VERSION ""

NS_ :

BS_:

BU_: GW_ABFD ADCU3_ABFD

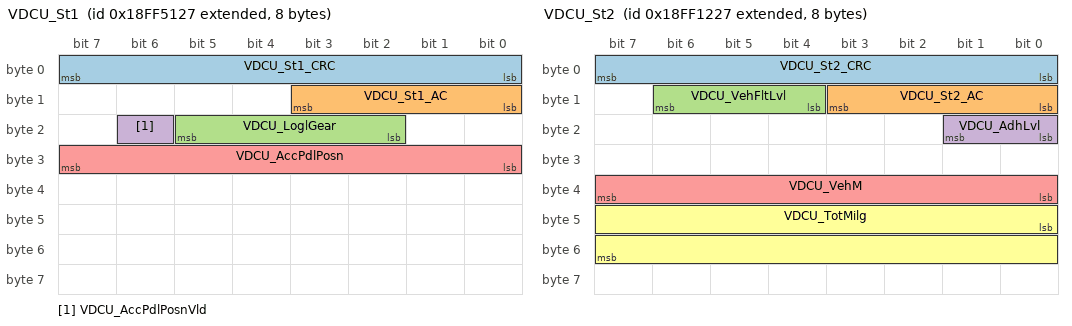
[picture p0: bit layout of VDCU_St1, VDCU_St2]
BO_ 2566869287 VDCU_St1: 8 GW_ABFD
 SG_ VDCU_St1_CRC : 0|8@1+ (1,0) [0|255] ""  ADCU3_ABFD
 SG_ VDCU_St1_AC : 8|4@1+ (1,0) [0|14] ""  ADCU3_ABFD
 SG_ VDCU_LoglGear : 18|4@1+ (1,0) [0|15] ""  ADCU3_ABFD
 SG_ VDCU_AccPdlPosnVld : 22|1@1+ (1,0) [0|1] ""  ADCU3_ABFD
 SG_ VDCU_AccPdlPosn : 24|8@1+ (1,0) [0|100] "%"  ADCU3_ABFD

BO_ 2566853159 VDCU_St2: 8 GW_ABFD
 SG_ VDCU_St2_CRC : 0|8@1+ (1,0) [0|255] ""  ADCU3_ABFD
 SG_ VDCU_St2_AC : 8|4@1+ (1,0) [0|14] ""  ADCU3_ABFD
 SG_ VDCU_VehFltLvl : 12|3@1+ (1,0) [0|7] ""  ADCU3_ABFD
 SG_ VDCU_AdhLvl : 16|2@1+ (1,0) [0|3] ""  ADCU3_ABFD
 SG_ VDCU_VehM : 32|8@1+ (400,0) [0|102000] "kg"  ADCU3_ABFD
 SG_ VDCU_TotMilg : 40|16@1+ (1,0) [0|2000] "km"  ADCU3_ABFD

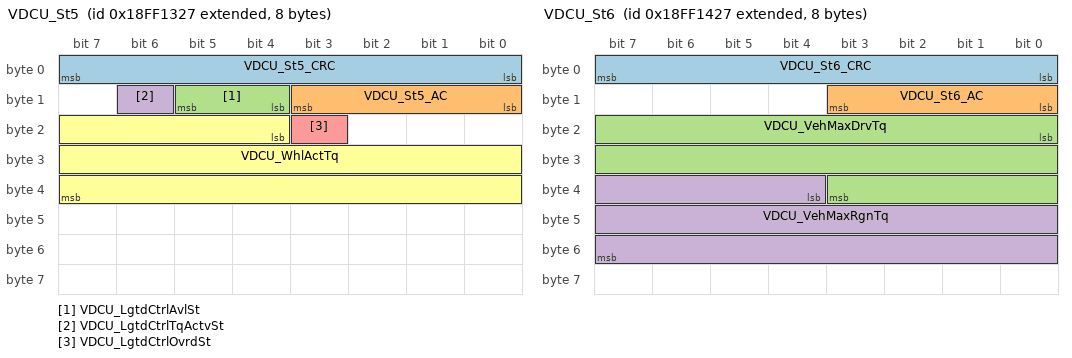
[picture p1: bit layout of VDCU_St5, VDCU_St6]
BO_ 2566853415 VDCU_St5: 8 GW_ABFD
 SG_ VDCU_St5_CRC : 0|8@1+ (1,0) [0|255] ""  ADCU3_ABFD
 SG_ VDCU_St5_AC : 8|4@1+ (1,0) [0|14] ""  ADCU3_ABFD
 SG_ VDCU_LgtdCtrlAvlSt : 12|2@1+ (1,0) [0|3] ""  ADCU3_ABFD
 SG_ VDCU_LgtdCtrlTqActvSt : 14|1@1+ (1,0) [0|1] ""  ADCU3_ABFD
 SG_ VDCU_LgtdCtrlOvrdSt : 19|1@1+ (1,0) [0|1] ""  ADCU3_ABFD
 SG_ VDCU_WhlActTq : 20|20@1+ (5,-150000) [-150000|150000] "Nm"  ADCU3_ABFD

BO_ 2566853671 VDCU_St6: 8 GW_ABFD
 SG_ VDCU_St6_CRC : 0|8@1+ (1,0) [0|255] ""  ADCU3_ABFD
 SG_ VDCU_St6_AC : 8|4@1+ (1,0) [0|14] ""  ADCU3_ABFD
 SG_ VDCU_VehMaxDrvTq : 16|20@1+ (5,0) [0|150000] "Nm"  ADCU3_ABFD
 SG_ VDCU_VehMaxRgnTq : 36|20@1+ (5,-150000) [-150000|0] "Nm"  ADCU3_ABFD

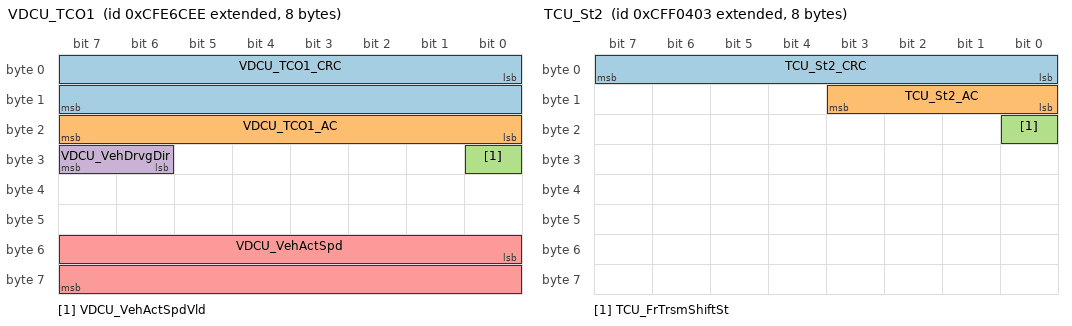
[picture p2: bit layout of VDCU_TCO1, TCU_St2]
BO_ 2365484270 VDCU_TCO1: 8 GW_ABFD
 SG_ VDCU_TCO1_CRC : 0|16@1+ (1,0) [0|65535] ""  ADCU3_ABFD
 SG_ VDCU_TCO1_AC : 16|8@1+ (1,0) [0|255] ""  ADCU3_ABFD
 SG_ VDCU_VehActSpdVld : 24|1@1+ (1,0) [0|1] ""  ADCU3_ABFD
 SG_ VDCU_VehDrvgDir : 30|2@1+ (1,0) [0|3] ""  ADCU3_ABFD
 SG_ VDCU_VehActSpd : 48|16@1+ (0.00390625,0) [0|250.996] "km/h"  ADCU3_ABFD

BO_ 2566844711 VDCU_CCVS1: 8 GW_ABFD
 SG_ VDCU_BrkPdlSwt : 28|2@1+ (1,0) [0|3] ""  ADCU3_ABFD

BO_ 2365526280 MCUF_St1: 8 GW_ABFD
 SG_ MCUF_FrMotActSpd : 32|16@1+ (1,-20000) [-20000|20000] "rpm"  ADCU3_ABFD

BO_ 2365522947 TCU_St2: 8 GW_ABFD
 SG_ TCU_St2_CRC : 0|8@1+ (1,0) [0|255] ""  ADCU3_ABFD
 SG_ TCU_St2_AC : 8|4@1+ (1,0) [0|14] ""  ADCU3_ABFD
 SG_ TCU_FrTrsmShiftSt : 16|1@1+ (1,0) [0|1] ""  ADCU3_ABFD

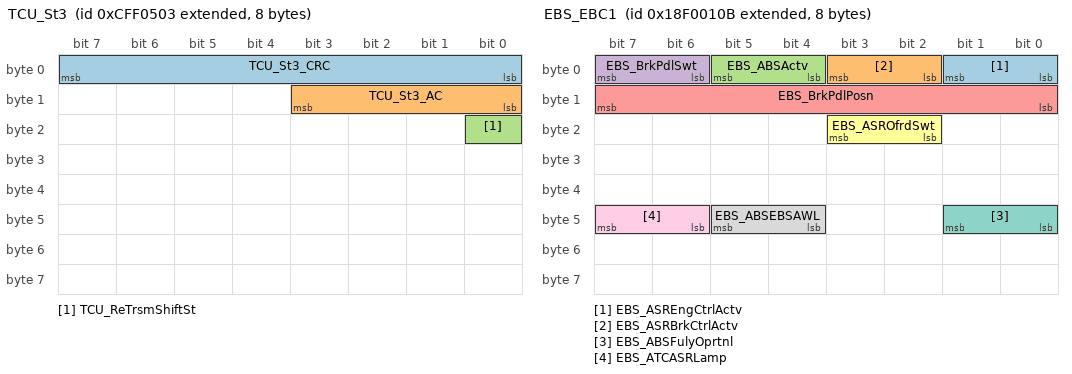
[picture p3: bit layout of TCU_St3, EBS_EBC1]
BO_ 2365523203 TCU_St3: 8 GW_ABFD
 SG_ TCU_St3_CRC : 0|8@1+ (1,0) [0|255] ""  ADCU3_ABFD
 SG_ TCU_St3_AC : 8|4@1+ (1,0) [0|14] ""  ADCU3_ABFD
 SG_ TCU_ReTrsmShiftSt : 16|1@1+ (1,0) [0|1] ""  ADCU3_ABFD

BO_ 2565865739 EBS_EBC1: 8 GW_ABFD
 SG_ EBS_ASREngCtrlActv : 0|2@1+ (1,0) [0|3] ""  ADCU3_ABFD
 SG_ EBS_ASRBrkCtrlActv : 2|2@1+ (1,0) [0|3] ""  ADCU3_ABFD
 SG_ EBS_ABSActv : 4|2@1+ (1,0) [0|3] ""  ADCU3_ABFD
 SG_ EBS_BrkPdlSwt : 6|2@1+ (1,0) [0|3] ""  ADCU3_ABFD
 SG_ EBS_BrkPdlPosn : 8|8@1+ (0.4,0) [0|100] "%"  ADCU3_ABFD
 SG_ EBS_ASROfrdSwt : 18|2@1+ (1,0) [0|3] ""  ADCU3_ABFD
 SG_ EBS_ABSFulyOprtnl : 40|2@1+ (1,0) [0|3] ""  ADCU3_ABFD
 SG_ EBS_ABSEBSAWL : 44|2@1+ (1,0) [0|3] ""  ADCU3_ABFD
 SG_ EBS_ATCASRLamp : 46|2@1+ (1,0) [0|3] ""  ADCU3_ABFD

BO_ 2566831883 EBS_EBC2: 8 GW_ABFD
 SG_ EBS_TwoFrAxleSpd : 0|16@1+ (0.00390625,0) [0|251] "km/h"  ADCU3_ABFD

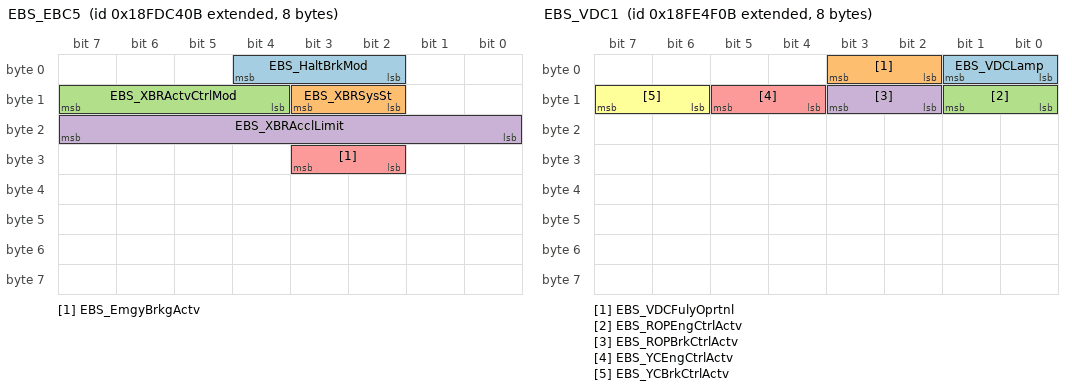
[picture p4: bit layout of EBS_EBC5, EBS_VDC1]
BO_ 2566767627 EBS_EBC5: 8 GW_ABFD
 SG_ EBS_HaltBrkMod : 2|3@1+ (1,0) [0|7] ""  ADCU3_ABFD
 SG_ EBS_XBRSysSt : 10|2@1+ (1,0) [0|3] ""  ADCU3_ABFD
 SG_ EBS_XBRActvCtrlMod : 12|4@1+ (1,0) [0|15] ""  ADCU3_ABFD
 SG_ EBS_XBRAcclLimit : 16|8@1+ (0.1,-12.5) [-10|0] "m/s^2"  ADCU3_ABFD
 SG_ EBS_EmgyBrkgActv : 26|2@1+ (1,0) [0|3] ""  ADCU3_ABFD

BO_ 2566803211 EBS_VDC1: 8 GW_ABFD
 SG_ EBS_VDCLamp : 0|2@1+ (1,0) [0|3] ""  ADCU3_ABFD
 SG_ EBS_VDCFulyOprtnl : 2|2@1+ (1,0) [0|3] ""  ADCU3_ABFD
 SG_ EBS_ROPEngCtrlActv : 8|2@1+ (1,0) [0|3] ""  ADCU3_ABFD
 SG_ EBS_ROPBrkCtrlActv : 10|2@1+ (1,0) [0|3] ""  ADCU3_ABFD
 SG_ EBS_YCEngCtrlActv : 12|2@1+ (1,0) [0|3] ""  ADCU3_ABFD
 SG_ EBS_YCBrkCtrlActv : 14|2@1+ (1,0) [0|3] ""  ADCU3_ABFD

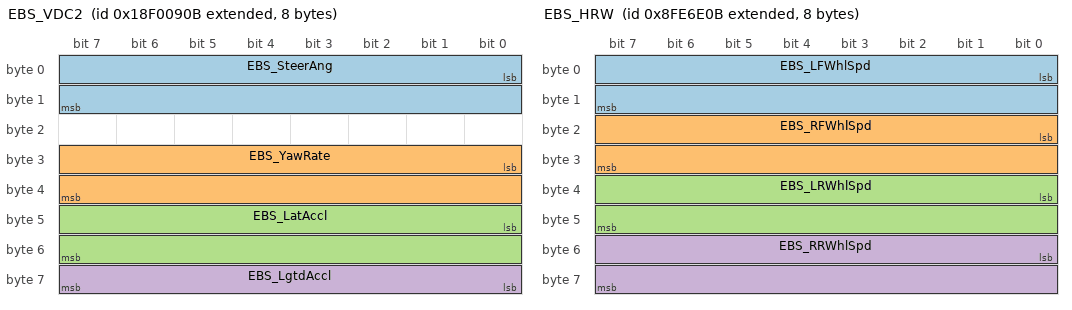
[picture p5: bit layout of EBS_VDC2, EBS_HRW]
BO_ 2565867787 EBS_VDC2: 8 GW_ABFD
 SG_ EBS_SteerAng : 0|16@1+ (0.0009765625,-31.374) [-31.374|31.374] "rad"  ADCU3_ABFD
 SG_ EBS_YawRate : 24|16@1+ (0.0001220703125,-3.92) [-3.92|3.92] "rad/s"  ADCU3_ABFD
 SG_ EBS_LatAccl : 40|16@1+ (0.00048828125,-15.687) [-15.687|15.687] "m/s^2"  ADCU3_ABFD
 SG_ EBS_LgtdAccl : 56|8@1+ (0.1,-12.5) [-12.5|12.5] "m/s^2"  ADCU3_ABFD

BO_ 2298375691 EBS_HRW: 8 GW_ABFD
 SG_ EBS_LFWhlSpd : 0|16@1+ (0.00390625,0) [0|251] "km/h"  ADCU3_ABFD
 SG_ EBS_RFWhlSpd : 16|16@1+ (0.00390625,0) [0|251] "km/h"  ADCU3_ABFD
 SG_ EBS_LRWhlSpd : 32|16@1+ (0.00390625,0) [0|251] "km/h"  ADCU3_ABFD
 SG_ EBS_RRWhlSpd : 48|16@1+ (0.00390625,0) [0|251] "km/h"  ADCU3_ABFD

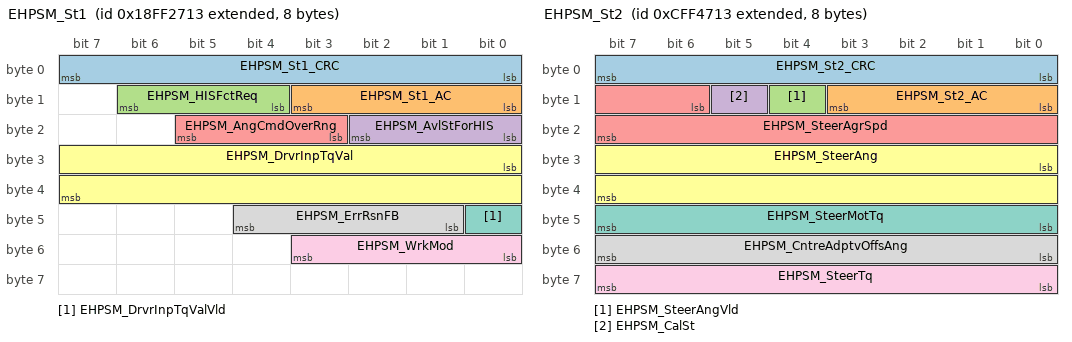
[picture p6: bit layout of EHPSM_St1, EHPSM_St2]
BO_ 2566858515 EHPSM_St1: 8 GW_ABFD
 SG_ EHPSM_St1_CRC : 0|8@1+ (1,0) [0|255] ""  ADCU3_ABFD
 SG_ EHPSM_St1_AC : 8|4@1+ (1,0) [0|14] ""  ADCU3_ABFD
 SG_ EHPSM_HISFctReq : 12|3@1+ (1,0) [0|7] ""  ADCU3_ABFD
 SG_ EHPSM_AvlStForHIS : 16|3@1+ (1,0) [0|7] ""  ADCU3_ABFD
 SG_ EHPSM_AngCmdOverRng : 19|3@1+ (1,0) [0|1] ""  ADCU3_ABFD
 SG_ EHPSM_DrvrInpTqVal : 24|16@1+ (0.1,-12.8) [-12.8|12.7] "Nm"  ADCU3_ABFD
 SG_ EHPSM_DrvrInpTqValVld : 40|1@1+ (1,0) [0|1] ""  ADCU3_ABFD
 SG_ EHPSM_ErrRsnFB : 41|4@1+ (1,0) [0|15] ""  ADCU3_ABFD
 SG_ EHPSM_WrkMod : 48|4@1+ (1,0) [0|15] ""  ADCU3_ABFD

BO_ 2365540115 EHPSM_St2: 8 GW_ABFD
 SG_ EHPSM_St2_CRC : 0|8@1+ (1,0) [0|255] ""  ADCU3_ABFD
 SG_ EHPSM_St2_AC : 8|4@1+ (1,0) [0|14] ""  ADCU3_ABFD
 SG_ EHPSM_SteerAngVld : 12|1@1+ (1,0) [0|1] ""  ADCU3_ABFD
 SG_ EHPSM_CalSt : 13|1@1+ (1,0) [0|1] ""  ADCU3_ABFD
 SG_ EHPSM_SteerAgrSpd : 14|10@1+ (4,-1016) [-1016|1016] "deg/s"  ADCU3_ABFD
 SG_ EHPSM_SteerAng : 24|16@1+ (0.1,-1575) [-1575|1575] "deg"  ADCU3_ABFD
 SG_ EHPSM_SteerMotTq : 40|8@1+ (0.1,-12.8) [-12.8|12.7] "Nm"  ADCU3_ABFD
 SG_ EHPSM_CntreAdptvOffsAng : 48|8@1+ (0.1,-12.8) [-12.8|12.7] "deg"  ADCU3_ABFD
 SG_ EHPSM_SteerTq : 56|8@1+ (0.1,-12.8) [-12.8|12.7] "Nm"  ADCU3_ABFD

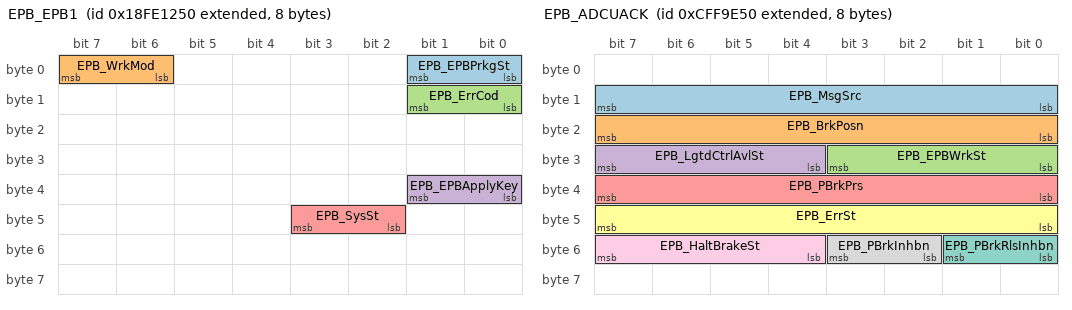
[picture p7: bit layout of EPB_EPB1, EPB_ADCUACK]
BO_ 2566787664 EPB_EPB1: 8 GW_ABFD
 SG_ EPB_EPBPrkgSt : 0|2@1+ (1,0) [0|3] ""  ADCU3_ABFD
 SG_ EPB_WrkMod : 6|2@1+ (1,0) [0|3] ""  ADCU3_ABFD
 SG_ EPB_ErrCod : 8|2@1+ (1,0) [0|3] ""  ADCU3_ABFD
 SG_ EPB_EPBApplyKey : 32|2@1+ (1,0) [0|3] ""  ADCU3_ABFD
 SG_ EPB_SysSt : 42|2@1+ (1,0) [0|3] ""  ADCU3_ABFD

BO_ 2365562448 EPB_ADCUACK: 8 GW_ABFD
 SG_ EPB_MsgSrc : 8|8@1+ (1,0) [0|255] ""  ADCU3_ABFD
 SG_ EPB_BrkPosn : 16|8@1+ (1,-125) [-100|100] "%"  ADCU3_ABFD
 SG_ EPB_EPBWrkSt : 24|4@1+ (1,0) [0|15] ""  ADCU3_ABFD
 SG_ EPB_LgtdCtrlAvlSt : 28|4@1+ (1,0) [0|15] ""  ADCU3_ABFD
 SG_ EPB_PBrkPrs : 32|8@1+ (4,0) [0|1020] ""  ADCU3_ABFD
 SG_ EPB_ErrSt : 40|8@1+ (1,0) [0|255] ""  ADCU3_ABFD
 SG_ EPB_PBrkRlsInhbn : 48|2@1+ (1,0) [0|3] ""  ADCU3_ABFD
 SG_ EPB_PBrkInhbn : 50|2@1+ (1,0) [0|3] ""  ADCU3_ABFD
 SG_ EPB_HaltBrakeSt : 52|4@1+ (1,0) [0|15] ""  ADCU3_ABFD

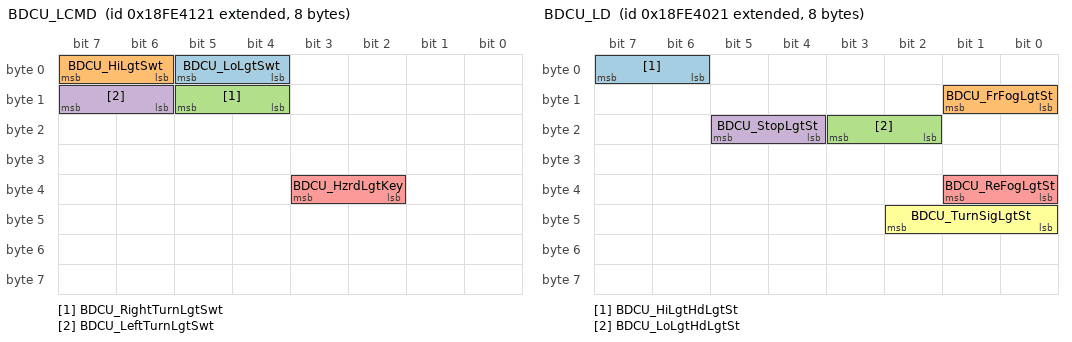
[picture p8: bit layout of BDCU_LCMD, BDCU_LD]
BO_ 2566799649 BDCU_LCMD: 8 GW_ABFD
 SG_ BDCU_LoLgtSwt : 4|2@1+ (1,0) [0|3] ""  ADCU3_ABFD
 SG_ BDCU_HiLgtSwt : 6|2@1+ (1,0) [0|3] ""  ADCU3_ABFD
 SG_ BDCU_RightTurnLgtSwt : 12|2@1+ (1,0) [0|3] ""  ADCU3_ABFD
 SG_ BDCU_LeftTurnLgtSwt : 14|2@1+ (1,0) [0|3] ""  ADCU3_ABFD
 SG_ BDCU_HzrdLgtKey : 34|2@1+ (1,0) [0|3] ""  ADCU3_ABFD

BO_ 2566799393 BDCU_LD: 8 GW_ABFD
 SG_ BDCU_HiLgtHdLgtSt : 6|2@1+ (1,0) [0|3] ""  ADCU3_ABFD
 SG_ BDCU_FrFogLgtSt : 8|2@1+ (1,0) [0|3] ""  ADCU3_ABFD
 SG_ BDCU_LoLgtHdLgtSt : 18|2@1+ (1,0) [0|3] ""  ADCU3_ABFD
 SG_ BDCU_StopLgtSt : 20|2@1+ (1,0) [0|3] ""  ADCU3_ABFD
 SG_ BDCU_ReFogLgtSt : 32|2@1+ (1,0) [0|3] ""  ADCU3_ABFD
 SG_ BDCU_TurnSigLgtSt : 40|3@1+ (1,0) [0|7] ""  ADCU3_ABFD

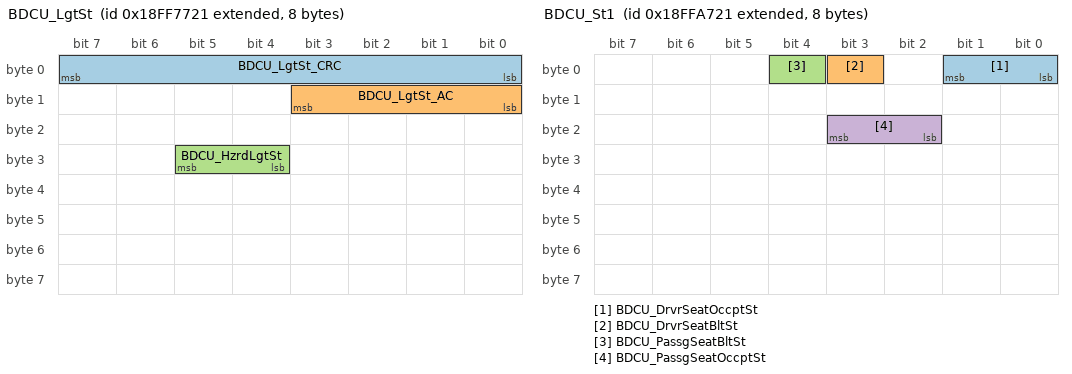
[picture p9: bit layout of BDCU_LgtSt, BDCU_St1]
BO_ 2566879009 BDCU_LgtSt: 8 GW_ABFD
 SG_ BDCU_LgtSt_CRC : 0|8@1+ (1,0) [0|255] ""  ADCU3_ABFD
 SG_ BDCU_LgtSt_AC : 8|4@1+ (1,0) [0|14] ""  ADCU3_ABFD
 SG_ BDCU_HzrdLgtSt : 28|2@1+ (1,0) [0|3] ""  ADCU3_ABFD

BO_ 2566891297 BDCU_St1: 8 GW_ABFD
 SG_ BDCU_DrvrSeatOccptSt : 0|2@1+ (1,0) [0|3] ""  ADCU3_ABFD
 SG_ BDCU_DrvrSeatBltSt : 3|1@1+ (1,0) [0|1] ""  ADCU3_ABFD
 SG_ BDCU_PassgSeatBltSt : 4|1@1+ (1,0) [0|1] ""  ADCU3_ABFD
 SG_ BDCU_PassgSeatOccptSt : 18|2@1+ (1,0) [0|3] ""  ADCU3_ABFD

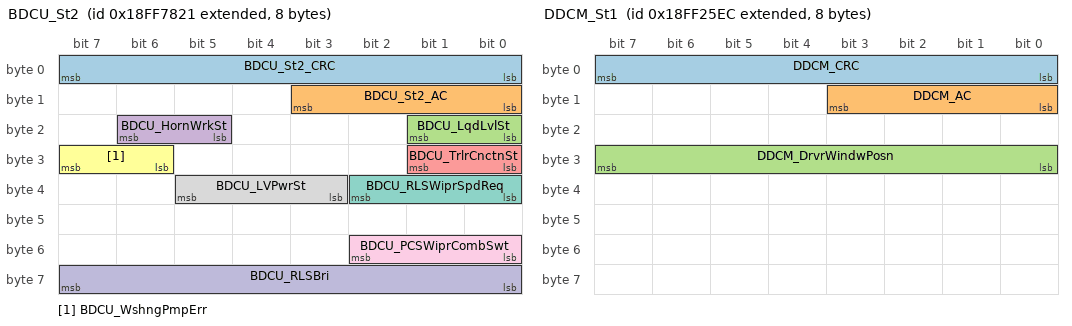
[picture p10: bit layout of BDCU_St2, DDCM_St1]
BO_ 2566879265 BDCU_St2: 8 GW_ABFD
 SG_ BDCU_St2_CRC : 0|8@1+ (1,0) [0|255] ""  ADCU3_ABFD
 SG_ BDCU_St2_AC : 8|4@1+ (1,0) [0|14] ""  ADCU3_ABFD
 SG_ BDCU_LqdLvlSt : 16|2@1+ (1,0) [0|3] ""  ADCU3_ABFD
 SG_ BDCU_HornWrkSt : 21|2@1+ (1,0) [0|3] ""  ADCU3_ABFD
 SG_ BDCU_TrlrCnctnSt : 24|2@1+ (1,0) [0|3] ""  ADCU3_ABFD
 SG_ BDCU_WshngPmpErr : 30|2@1+ (1,0) [0|3] ""  ADCU3_ABFD
 SG_ BDCU_RLSWiprSpdReq : 32|3@1+ (1,0) [0|7] ""  ADCU3_ABFD
 SG_ BDCU_LVPwrSt : 35|3@1+ (1,0) [0|7] ""  ADCU3_ABFD
 SG_ BDCU_PCSWiprCombSwt : 48|3@1+ (1,0) [0|7] ""  ADCU3_ABFD
 SG_ BDCU_RLSBri : 56|8@1+ (100,0) [0|25000] "LUX"  ADCU3_ABFD

BO_ 2566858220 DDCM_St1: 8 GW_ABFD
 SG_ DDCM_CRC : 0|8@1+ (1,0) [0|255] ""  ADCU3_ABFD
 SG_ DDCM_AC : 8|4@1+ (1,0) [0|14] ""  ADCU3_ABFD
 SG_ DDCM_DrvrWindwPosn : 24|8@1+ (1,0) [0|255] "%"  ADCU3_ABFD

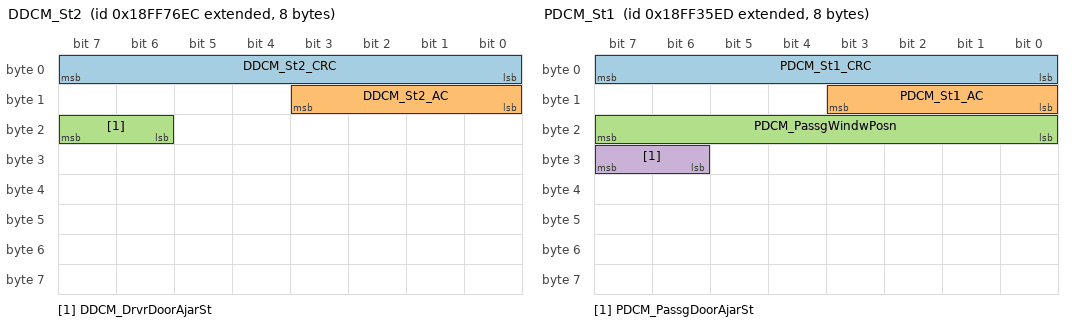
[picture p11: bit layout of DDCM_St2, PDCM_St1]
BO_ 2566878956 DDCM_St2: 8 GW_ABFD
 SG_ DDCM_St2_CRC : 0|8@1+ (1,0) [0|255] ""  ADCU3_ABFD
 SG_ DDCM_St2_AC : 8|4@1+ (1,0) [0|14] ""  ADCU3_ABFD
 SG_ DDCM_DrvrDoorAjarSt : 22|2@1+ (1,0) [0|3] ""  ADCU3_ABFD

BO_ 2566862317 PDCM_St1: 8 GW_ABFD
 SG_ PDCM_St1_CRC : 0|8@1+ (1,0) [0|255] ""  ADCU3_ABFD
 SG_ PDCM_St1_AC : 8|4@1+ (1,0) [0|14] ""  ADCU3_ABFD
 SG_ PDCM_PassgWindwPosn : 16|8@1+ (1,0) [0|100] "%"  ADCU3_ABFD
 SG_ PDCM_PassgDoorAjarSt : 30|2@1+ (1,0) [0|3] ""  ADCU3_ABFD

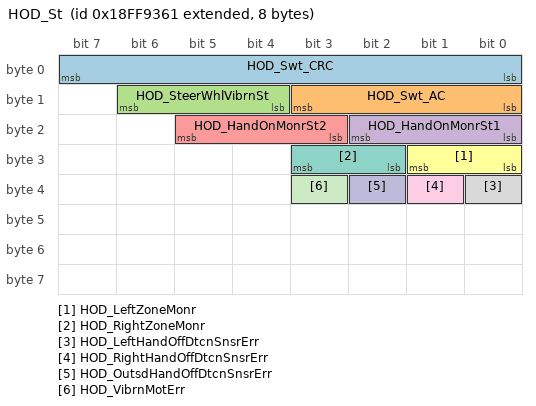
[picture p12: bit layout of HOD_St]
BO_ 2566886241 HOD_St: 8 GW_ABFD
 SG_ HOD_Swt_CRC : 0|8@1+ (1,0) [0|255] ""  ADCU3_ABFD
 SG_ HOD_Swt_AC : 8|4@1+ (1,0) [0|14] ""  ADCU3_ABFD
 SG_ HOD_SteerWhlVibrnSt : 12|3@1+ (1,0) [0|7] ""  ADCU3_ABFD
 SG_ HOD_HandOnMonrSt1 : 16|3@1+ (1,0) [0|7] ""  ADCU3_ABFD
 SG_ HOD_HandOnMonrSt2 : 19|3@1+ (1,0) [0|7] ""  ADCU3_ABFD
 SG_ HOD_LeftZoneMonr : 24|2@1+ (1,0) [0|3] ""  ADCU3_ABFD
 SG_ HOD_RightZoneMonr : 26|2@1+ (1,0) [0|3] ""  ADCU3_ABFD
 SG_ HOD_LeftHandOffDtcnSnsrErr : 32|1@1+ (1,0) [0|1] ""  ADCU3_ABFD
 SG_ HOD_RightHandOffDtcnSnsrErr : 33|1@1+ (1,0) [0|1] ""  ADCU3_ABFD
 SG_ HOD_OutsdHandOffDtcnSnsrErr : 34|1@1+ (1,0) [0|1] ""  ADCU3_ABFD
 SG_ HOD_VibrnMotErr : 35|1@1+ (1,0) [0|1] ""  ADCU3_ABFD

BO_ 2566845491 TPMS_TIRE: 8 GW_ABFD
 SG_ TPMS_TireHiTWarn : 32|2@1+ (1,0) [0|3] ""  ADCU3_ABFD
 SG_ TPMS_TireHiLoPWarn : 61|3@1+ (1,0) [0|3] ""  ADCU3_ABFD

BO_ 659 ADCU3A_St1: 64 ADCU3_ABFD
 SG_ ADCU3A_St1_CRC : 0|16@1+ (1,0) [0|65535] "" Vector__XXX
 SG_ ADCU3A_St1_AC : 16|8@1+ (1,0) [0|255] "" Vector__XXX
 SG_ ADCU3A_HNASwtFB : 24|1@1+ (1,0) [0|1] "" Vector__XXX
 SG_ ADCU3A_LaneChgSwtFB : 25|1@1+ (1,0) [0|1] "" Vector__XXX
 SG_ ADCU3A_AutoLaneChgCfmFB : 26|1@1+ (1,0) [0|1] "" Vector__XXX
 SG_ ADCU3A_AutoLaneChgRmnSetFB : 27|2@1+ (1,0) [0|3] "" Vector__XXX
 SG_ ADCU3A_AutoLaneChgSetFB : 29|2@1+ (1,0) [0|3] "" Vector__XXX
 SG_ ADCU3A_HWAStudyModSwtFB : 31|1@1+ (1,0) [0|1] "" Vector__XXX
 SG_ ADCU3A_HWAHNAWrkst : 33|4@1+ (1,0) [0|15] "" Vector__XXX
 SG_ ADCU3A_ALCFctSt : 37|3@1+ (1,0) [0|7] "" Vector__XXX
 SG_ ADCU3A_TakeOverReq : 40|3@1+ (1,0) [0|7] "" Vector__XXX
 SG_ ADCU3A_HWAHNAFctRmn : 43|4@1+ (1,0) [0|15] "" Vector__XXX
 SG_ ADCU3A_LaneChgReq : 48|2@1+ (1,0) [0|3] "" Vector__XXX
 SG_ ADCU3A_TurnLgtClsRmn : 50|1@1+ (1,0) [0|1] "" Vector__XXX
 SG_ ADCU3A_HWAFctLamp : 51|3@1+ (1,0) [0|7] "" Vector__XXX
 SG_ ADCU3A_LgtdCtrlSpdSetSt : 56|8@1+ (1,0) [0|255] "km/h" Vector__XXX
 SG_ ADCU3A_LgtdCtrlTigapSetSt : 64|3@1+ (1,0) [0|7] "" Vector__XXX
 SG_ ADCU3A_LgtdCtrlTarDisp : 67|3@1+ (1,0) [0|7] "" Vector__XXX
 SG_ ADCU3A_LeftFisrtLaneTyp : 82|3@1+ (1,0) [0|7] "" Vector__XXX
 SG_ ADCU3A_LeftFirstLaneTrackSt : 85|3@1+ (1,0) [0|7] "" Vector__XXX
 SG_ ADCU3A_LeftFirstLaneDy : 88|13@1+ (0.00390625,-16) [-16|15.9921875] "m" Vector__XXX
 SG_ ADCU3A_LeftFirstLaneAngYaw : 104|16@1+ (0.00390625,-125) [-125|130.9921875] "°" Vector__XXX
 SG_ ADCU3A_LeftFirstLaneCrvt : 120|16@1+ (7.8125E-006,-0.25) [-0.25|0.261984375] "1/m" Vector__XXX
 SG_ ADCU3A_LeftFirstLaneCrvtChg : 136|16@1+ (6.25E-008,-0.002) [-0.002|0.002095875] "1/m^2" Vector__XXX
 SG_ ADCU3A_LeftSecLaneTyp : 154|3@1+ (1,0) [0|7] "" Vector__XXX
 SG_ ADCU3_LeftSecLaneTrackSt : 157|3@1+ (1,0) [0|7] "" Vector__XXX
 SG_ ADCU3A_LeftSecLaneDy : 160|13@1+ (0.00390625,-16) [-16|15.9921875] "m" Vector__XXX
 SG_ ADCU3A_LeftSecLaneAngYaw : 176|16@1+ (0.00390625,-125) [-125|130.9921875] "°" Vector__XXX
 SG_ ADCU3A_LeftSecLaneCrvt : 192|16@1+ (7.8125E-006,-0.25) [-0.25|0.261984375] "1/m" Vector__XXX
 SG_ ADCU3A_LeftSecLaneCrvtChg : 208|16@1+ (6.25E-008,-0.002) [-0.002|0.002095875] "1/m^2" Vector__XXX
 SG_ ADCU3A_RightFisrtLaneTyp : 370|3@1+ (1,0) [0|7] "" Vector__XXX
 SG_ ADCU3A_RightFirstLaneTrackSt : 373|3@1+ (1,0) [0|7] "" Vector__XXX
 SG_ ADCU3A_RightFirstLaneDy : 376|13@1+ (0.00390625,-16) [-16|15.9921875] "m" Vector__XXX
 SG_ ADCU3A_RightFirstLaneAngYaw : 392|16@1+ (0.00390625,-125) [-125|130.9921875] "°" Vector__XXX
 SG_ ADCU3A_RightFirstLaneCrvt : 408|16@1+ (7.8125E-006,-0.25) [-0.25|0.261984375] "1/m" Vector__XXX
 SG_ ADCU3A_RightFirstLaneCrvtChg : 424|16@1+ (6.25E-008,-0.002) [-0.002|0.002095875] "1/m^2" Vector__XXX

BO_ 660 ADCU3A_St2: 64 ADCU3_ABFD
 SG_ ADCU3A_St2_CRC : 0|16@1+ (1,0) [0|65535] "" Vector__XXX
 SG_ ADCU3A_St2_AC : 16|8@1+ (1,0) [0|255] "" Vector__XXX
 SG_ ADCU3A_RightSecLaneTyp : 26|3@1+ (1,0) [0|7] "" Vector__XXX
 SG_ ADCU3_RightSecLaneTrackSt : 29|3@1+ (1,0) [0|7] "" Vector__XXX
 SG_ ADCU3A_RightSecLaneDy : 32|13@1+ (0.00390625,-16) [-16|15.9921875] "m" Vector__XXX
 SG_ ADCU3A_RightSecLaneAngYaw : 48|16@1+ (0.00390625,-125) [-125|130.9921875] "°" Vector__XXX
 SG_ ADCU3A_RightSecLaneCrvt : 64|16@1+ (7.8125E-006,-0.25) [-0.25|0.261984375] "1/m" Vector__XXX
 SG_ ADCU3A_RightSecLaneCrvtChg : 80|16@1+ (6.25E-008,-0.002) [-0.002|0.002095875] "1/m^2" Vector__XXX
 SG_ ADCU3A_LeftTar01YawAng : 96|9@1+ (1,-180) [-180|179] "°" Vector__XXX
 SG_ ADCU3A_LeftTar02YawAng : 105|9@1+ (1,-180) [-180|179] "°" Vector__XXX
 SG_ ADCU3A_LeftTar03YawAng : 114|9@1+ (1,-180) [-180|179] "°" Vector__XXX
 SG_ ADCU3A_LeftTar04YawAng : 123|9@1+ (1,-180) [-180|179] "°" Vector__XXX
 SG_ ADCU3A_LeftTar05YawAng : 132|9@1+ (1,-180) [-180|179] "°" Vector__XXX
 SG_ ADCU3A_LeftTar06YawAng : 141|9@1+ (1,-180) [-180|179] "°" Vector__XXX
 SG_ ADCU3A_LeftTar07YawAng : 150|9@1+ (1,-180) [-180|179] "°" Vector__XXX
 SG_ ADCU3A_LeftTar08YawAng : 159|9@1+ (1,-180) [-180|179] "°" Vector__XXX
 SG_ ADCU3A_RightTar01YawAng : 168|9@1+ (1,-180) [-180|179] "°" Vector__XXX
 SG_ ADCU3A_RightTar02YawAng : 177|9@1+ (1,-180) [-180|179] "°" Vector__XXX
 SG_ ADCU3A_RightTar03YawAng : 186|9@1+ (1,-180) [-180|179] "°" Vector__XXX
 SG_ ADCU3A_RightTar04YawAng : 195|9@1+ (1,-180) [-180|179] "°" Vector__XXX
 SG_ ADCU3A_RightTar05YawAng : 204|9@1+ (1,-180) [-180|179] "°" Vector__XXX
 SG_ ADCU3A_RightTar06YawAng : 213|9@1+ (1,-180) [-180|179] "°" Vector__XXX
 SG_ ADCU3A_RightTar07YawAng : 222|9@1+ (1,-180) [-180|179] "°" Vector__XXX
 SG_ ADCU3A_RightTar08YawAng : 231|9@1+ (1,-180) [-180|179] "°" Vector__XXX
 SG_ ADCU3A_LgtdCtrlMainTarID : 240|5@1+ (1,0) [0|31] "" Vector__XXX
 SG_ ADCU3A_LeftTar01Dtcd : 245|1@1+ (1,0) [0|1] "" Vector__XXX
 SG_ ADCU3A_LeftTar01ID : 248|5@1+ (1,0) [0|31] "" Vector__XXX
 SG_ ADCU3A_LeftTar01Typ : 256|4@1+ (1,0) [0|7] "" Vector__XXX
 SG_ ADCU3A_LeftTar01Dx : 264|13@1+ (0.05,-180) [-180|229.5] "m" Vector__XXX
 SG_ ADCU3A_LeftTar01Dy : 280|13@1+ (0.05,-180) [-180|229.5] "m" Vector__XXX
 SG_ ADCU3A_LeftTar02Dtcd : 293|1@1+ (1,0) [0|1] "" Vector__XXX
 SG_ ADCU3A_LeftTar02ID : 296|5@1+ (1,0) [0|31] "" Vector__XXX
 SG_ ADCU3A_LeftTar02Typ : 301|3@1+ (1,0) [0|7] "" Vector__XXX
 SG_ ADCU3A_LeftTar02Dx : 304|13@1+ (0.05,-180) [-180|229.5] "m" Vector__XXX
 SG_ ADCU3A_LeftTar02Dy : 320|13@1+ (0.05,-180) [-180|229.5] "m" Vector__XXX
 SG_ ADCU3A_LeftTar03Dtcd : 333|1@1+ (1,0) [0|1] "" Vector__XXX
 SG_ ADCU3A_LeftTar03ID : 336|5@1+ (1,0) [0|31] "" Vector__XXX
 SG_ ADCU3A_LeftTar03Typ : 341|3@1+ (1,0) [0|7] "" Vector__XXX
 SG_ ADCU3A_LeftTar03Dx : 344|13@1+ (0.05,-180) [-180|229.5] "m" Vector__XXX
 SG_ ADCU3A_LeftTar03Dy : 360|13@1+ (0.05,-180) [-180|229.5] "m" Vector__XXX
 SG_ ADCU3A_LeftTar04Dtcd : 373|1@1+ (1,0) [0|1] "" Vector__XXX
 SG_ ADCU3A_LeftTar04ID : 376|5@1+ (1,0) [0|31] "" Vector__XXX
 SG_ ADCU3A_LeftTar04Typ : 381|3@1+ (1,0) [0|7] "" Vector__XXX
 SG_ ADCU3A_LeftTar04Dx : 384|13@1+ (0.05,-180) [-180|229.5] "m" Vector__XXX
 SG_ ADCU3A_LeftTar04Dy : 400|13@1+ (0.05,-180) [-180|229.5] "m" Vector__XXX
 SG_ ADCU3A_LeftTar05Dtcd : 413|1@1+ (1,0) [0|1] "" Vector__XXX
 SG_ ADCU3A_LeftTar05ID : 416|5@1+ (1,0) [0|31] "" Vector__XXX
 SG_ ADCU3A_LeftTar05Typ : 421|3@1+ (1,0) [0|7] "" Vector__XXX
 SG_ ADCU3A_LeftTar05Dx : 424|13@1+ (0.05,-180) [-180|229.5] "m" Vector__XXX
 SG_ ADCU3A_LeftTar05Dy : 440|13@1+ (0.05,-180) [-180|229.5] "m" Vector__XXX
 SG_ ADCU3A_FrTar01YawAng : 456|9@1+ (1,-180) [-180|179] "°" Vector__XXX
 SG_ ADCU3A_FrTar02YawAng : 465|9@1+ (1,-180) [-180|179] "°" Vector__XXX

BO_ 675 ADCU3A_St3: 64 ADCU3_ABFD
 SG_ ADCU3A_St3_CRC : 0|16@1+ (1,0) [0|65535] "" Vector__XXX
 SG_ ADCU3A_St3_AC : 16|8@1+ (1,0) [0|255] "" Vector__XXX
 SG_ ADCU3A_LeftTar06Dtcd : 24|1@1+ (1,0) [0|1] "" Vector__XXX
 SG_ ADCU3A_LeftTar06ID : 26|5@1+ (1,0) [0|31] "" Vector__XXX
 SG_ ADCU3A_LeftTar06Typ : 32|3@1+ (1,0) [0|7] "" Vector__XXX
 SG_ ADCU3A_LeftTar06Dx : 35|13@1+ (0.05,-180) [-180|229.5] "m" Vector__XXX
 SG_ ADCU3A_LeftTar06Dy : 48|13@1+ (0.05,-180) [-180|229.5] "m" Vector__XXX
 SG_ ADCU3A_LeftTar07Dtcd : 61|1@1+ (1,0) [0|1] "" Vector__XXX
 SG_ ADCU3A_LeftTar07ID : 64|5@1+ (1,0) [0|31] "" Vector__XXX
 SG_ ADCU3A_LeftTar07Typ : 69|3@1+ (1,0) [0|7] "" Vector__XXX
 SG_ ADCU3A_LeftTar07Dx : 72|13@1+ (0.05,-180) [-180|229.5] "m" Vector__XXX
 SG_ ADCU3A_LeftTar07Dy : 88|13@1+ (0.05,-180) [-180|229.5] "m" Vector__XXX
 SG_ ADCU3A_LeftTar08Dtcd : 101|1@1+ (1,0) [0|1] "" Vector__XXX
 SG_ ADCU3A_LeftTar08ID : 104|5@1+ (1,0) [0|31] "" Vector__XXX
 SG_ ADCU3A_LeftTar08Typ : 109|3@1+ (1,0) [0|7] "" Vector__XXX
 SG_ ADCU3A_LeftTar08Dx : 112|13@1+ (0.05,-180) [-180|229.5] "m" Vector__XXX
 SG_ ADCU3A_LeftTar08Dy : 128|13@1+ (0.05,-180) [-180|229.5] "m" Vector__XXX
 SG_ ADCU3A_RightTar01Dtcd : 141|1@1+ (1,0) [0|1] "" Vector__XXX
 SG_ ADCU3A_RightTar01ID : 144|5@1+ (1,0) [0|31] "" Vector__XXX
 SG_ ADCU3A_RightTar01Typ : 149|3@1+ (1,0) [0|7] "" Vector__XXX
 SG_ ADCU3A_RightTar01Dx : 152|13@1+ (0.05,-180) [-180|229.5] "m" Vector__XXX
 SG_ ADCU3A_RightTar01Dy : 168|13@1+ (0.05,-180) [-180|229.5] "m" Vector__XXX
 SG_ ADCU3A_RightTar02Dtcd : 181|1@1+ (1,0) [0|1] "" Vector__XXX
 SG_ ADCU3A_RightTar02ID : 184|5@1+ (1,0) [0|31] "" Vector__XXX
 SG_ ADCU3A_RightTar02Typ : 189|3@1+ (1,0) [0|7] "" Vector__XXX
 SG_ ADCU3A_RightTar02Dx : 192|13@1+ (0.05,-180) [-180|229.5] "m" Vector__XXX
 SG_ ADCU3A_RightTar02Dy : 208|13@1+ (0.05,-180) [-180|229.5] "m" Vector__XXX
 SG_ ADCU3A_RightTar03Dtcd : 221|1@1+ (1,0) [0|1] "" Vector__XXX
 SG_ ADCU3A_RightTar03ID : 224|5@1+ (1,0) [0|31] "" Vector__XXX
 SG_ ADCU3A_RightTar03Typ : 229|3@1+ (1,0) [0|7] "" Vector__XXX
 SG_ ADCU3A_RightTar03Dx : 232|13@1+ (0.05,-180) [-180|229.5] "m" Vector__XXX
 SG_ ADCU3A_RightTar03Dy : 248|13@1+ (0.05,-180) [-180|229.5] "m" Vector__XXX
 SG_ ADCU3A_RightTar04Dtcd : 261|1@1+ (1,0) [0|1] "" Vector__XXX
 SG_ ADCU3A_RightTar04ID : 264|5@1+ (1,0) [0|31] "" Vector__XXX
 SG_ ADCU3A_RightTar04Typ : 269|3@1+ (1,0) [0|7] "" Vector__XXX
 SG_ ADCU3A_RightTar04Dx : 272|13@1+ (0.05,-180) [-180|229.5] "m" Vector__XXX
 SG_ ADCU3A_RightTar04Dy : 288|13@1+ (0.05,-180) [-180|229.5] "m" Vector__XXX
 SG_ ADCU3A_RightTar05Dtcd : 301|1@1+ (1,0) [0|1] "" Vector__XXX
 SG_ ADCU3A_RightTar05ID : 304|5@1+ (1,0) [0|31] "" Vector__XXX
 SG_ ADCU3A_RightTar05Typ : 309|3@1+ (1,0) [0|7] "" Vector__XXX
 SG_ ADCU3A_RightTar05Dx : 312|13@1+ (0.05,-180) [-180|229.5] "m" Vector__XXX
 SG_ ADCU3A_RightTar05Dy : 328|13@1+ (0.05,-180) [-180|229.5] "m" Vector__XXX
 SG_ ADCU3A_RightTar06Dtcd : 341|1@1+ (1,0) [0|1] "" Vector__XXX
 SG_ ADCU3A_RightTar06ID : 344|5@1+ (1,0) [0|31] "" Vector__XXX
 SG_ ADCU3A_RightTar06Typ : 349|3@1+ (1,0) [0|7] "" Vector__XXX
 SG_ ADCU3A_RightTar06Dx : 352|13@1+ (0.05,-180) [-180|229.5] "m" Vector__XXX
 SG_ ADCU3A_RightTar06Dy : 368|13@1+ (0.05,-180) [-180|229.5] "m" Vector__XXX
 SG_ ADCU3A_RightTar07Dtcd : 381|1@1+ (1,0) [0|1] "" Vector__XXX
 SG_ ADCU3A_RightTar07ID : 384|5@1+ (1,0) [0|31] "" Vector__XXX
 SG_ ADCU3A_RightTar07Typ : 389|3@1+ (1,0) [0|7] "" Vector__XXX
 SG_ ADCU3A_RightTar07Dx : 392|13@1+ (0.05,-180) [-180|229.5] "m" Vector__XXX
 SG_ ADCU3A_RightTar07Dy : 408|13@1+ (0.05,-180) [-180|229.5] "m" Vector__XXX
 SG_ ADCU3A_RightTar08Dtcd : 421|1@1+ (1,0) [0|1] "" Vector__XXX
 SG_ ADCU3A_RightTar08ID : 424|5@1+ (1,0) [0|31] "" Vector__XXX
 SG_ ADCU3A_RightTar08Typ : 429|3@1+ (1,0) [0|7] "" Vector__XXX
 SG_ ADCU3A_RightTar08Dx : 432|13@1+ (0.05,-180) [-180|229.5] "m" Vector__XXX
 SG_ ADCU3A_RightTar08Dy : 448|13@1+ (0.05,-180) [-180|229.5] "m" Vector__XXX
 SG_ ADCU3A_FrTar03YawAng : 464|9@1+ (1,-180) [-180|179] "°" Vector__XXX

BO_ 676 ADCU3A_St4: 64 ADCU3_ABFD
 SG_ ADCU3A_St4_CRC : 0|16@1+ (1,0) [0|65535] "" Vector__XXX
 SG_ ADCU3A_St4_AC : 16|8@1+ (1,0) [0|255] "" Vector__XXX
 SG_ ADCU3A_FrTar01Dtcd : 24|1@1+ (1,0) [0|1] "" Vector__XXX
 SG_ ADCU3A_FrTar01ID : 26|5@1+ (1,0) [0|31] "" Vector__XXX
 SG_ ADCU3A_FrTar01Typ : 32|3@1+ (1,0) [0|7] "" Vector__XXX
 SG_ ADCU3A_FrTar01Dx : 35|13@1+ (0.05,-180) [-180|229.5] "m" Vector__XXX
 SG_ ADCU3A_FrTar01Dy : 48|13@1+ (0.05,-180) [-180|229.5] "m" Vector__XXX
 SG_ ADCU3A_FrTar02Dtcd : 61|1@1+ (1,0) [0|1] "" Vector__XXX
 SG_ ADCU3A_FrTar02ID : 64|5@1+ (1,0) [0|31] "" Vector__XXX
 SG_ ADCU3A_FrTar02Typ : 69|3@1+ (1,0) [0|7] "" Vector__XXX
 SG_ ADCU3A_FrTar02Dx : 72|13@1+ (0.05,-180) [-180|229.5] "m" Vector__XXX
 SG_ ADCU3A_FrTar02Dy : 88|13@1+ (0.05,-180) [-180|229.5] "m" Vector__XXX
 SG_ ADCU3A_FrTar03Dtcd : 101|1@1+ (1,0) [0|1] "" Vector__XXX
 SG_ ADCU3A_FrTar03ID : 104|5@1+ (1,0) [0|31] "" Vector__XXX
 SG_ ADCU3A_FrTar03Typ : 109|3@1+ (1,0) [0|7] "" Vector__XXX
 SG_ ADCU3A_FrTar03Dx : 112|13@1+ (0.05,-180) [-180|229.5] "m" Vector__XXX
 SG_ ADCU3A_FrTar03Dy : 128|13@1+ (0.05,-180) [-180|229.5] "m" Vector__XXX
 SG_ ADCU3A_FrTar04Dtcd : 141|1@1+ (1,0) [0|1] "" Vector__XXX
 SG_ ADCU3A_FrTar04ID : 144|5@1+ (1,0) [0|31] "" Vector__XXX
 SG_ ADCU3A_FrTar04Typ : 149|3@1+ (1,0) [0|7] "" Vector__XXX
 SG_ ADCU3A_FrTar04Dx : 152|13@1+ (0.05,-180) [-180|229.5] "m" Vector__XXX
 SG_ ADCU3A_FrTar04Dy : 168|13@1+ (0.05,-180) [-180|229.5] "m" Vector__XXX
 SG_ ADCU3A_ReTar01Dtcd : 181|1@1+ (1,0) [0|1] "" Vector__XXX
 SG_ ADCU3A_ReTar01ID : 184|5@1+ (1,0) [0|31] "" Vector__XXX
 SG_ ADCU3A_ReTar01Typ : 189|3@1+ (1,0) [0|7] "" Vector__XXX
 SG_ ADCU3A_ReTar01Dx : 192|13@1+ (0.05,-180) [-180|229.5] "m" Vector__XXX
 SG_ ADCU3A_ReTar01Dy : 208|13@1+ (0.05,-180) [-180|229.5] "m" Vector__XXX
 SG_ ADCU3A_ReTar02Dtcd : 221|1@1+ (1,0) [0|1] "" Vector__XXX
 SG_ ADCU3A_ReTar02ID : 224|5@1+ (1,0) [0|31] "" Vector__XXX
 SG_ ADCU3A_ReTar02Typ : 229|3@1+ (1,0) [0|7] "" Vector__XXX
 SG_ ADCU3A_ReTar02Dx : 232|13@1+ (0.05,-180) [-180|229.5] "m" Vector__XXX
 SG_ ADCU3A_ReTar02Dy : 248|13@1+ (0.05,-180) [-180|229.5] "m" Vector__XXX
 SG_ ADCU3A_ReTar03Dtcd : 261|1@1+ (1,0) [0|1] "" Vector__XXX
 SG_ ADCU3A_ReTar03ID : 264|5@1+ (1,0) [0|31] "" Vector__XXX
 SG_ ADCU3A_ReTar03Typ : 269|3@1+ (1,0) [0|7] "" Vector__XXX
 SG_ ADCU3A_ReTar03Dx : 272|13@1+ (0.05,-180) [-180|229.5] "m" Vector__XXX
 SG_ ADCU3A_ReTar03Dy : 288|13@1+ (0.05,-180) [-180|229.5] "m" Vector__XXX
 SG_ ADCU3A_ReTar04Dtcd : 301|1@1+ (1,0) [0|1] "" Vector__XXX
 SG_ ADCU3A_ReTar04ID : 304|5@1+ (1,0) [0|31] "" Vector__XXX
 SG_ ADCU3A_ReTar04Typ : 309|3@1+ (1,0) [0|7] "" Vector__XXX
 SG_ ADCU3A_ReTar04Dx : 312|13@1+ (0.05,-180) [-180|229.5] "m" Vector__XXX
 SG_ ADCU3A_ReTar04Dy : 328|13@1+ (0.05,-180) [-180|229.5] "m" Vector__XXX
 SG_ ADCU3A_VehTarLeadLaneDir : 344|2@1+ (1,0) [0|3] "" Vector__XXX
 SG_ ADCU3A_VehTarLeadLaneColr : 346|3@1+ (1,0) [0|7] "" Vector__XXX
 SG_ ADCU3A_VehTarLeadLaneC0 : 352|7@1+ (0.1,-5.5) [-5.5|5.5] "m" Vector__XXX
 SG_ ADCU3A_VehTarLeadLaneC1 : 360|8@1+ (0.01,-1.1) [-1.1|1.1] "rad" Vector__XXX
 SG_ ADCU3A_VehTarLeadLaneC2 : 368|10@1+ (0.0001,-0.05) [-0.05|0.05] "1/m" Vector__XXX
 SG_ ADCU3A_VehTarLeadLaneC3 : 381|11@1+ (1,-1000) [-1000|1000] "1/m^2" Vector__XXX
 SG_ ADCU3A_VehTarLeadLaneC4 : 392|24@1+ (1,-1000000) [-1000000|1000000] "1/m^3" Vector__XXX
 SG_ ADCU3A_VehTarLeadLaneC5 : 416|24@1+ (5,-10000000) [-10000000|10000000] "1/m^4" Vector__XXX
 SG_ ADCU3A_VehCurrLeadLaneDir : 440|2@1+ (1,0) [0|3] "" Vector__XXX
 SG_ ADCU3A_VehCurrLeadLaneColr : 442|3@1+ (1,0) [0|7] "" Vector__XXX
 SG_ ADCU3A_VehCurrLeadLaneLen : 445|9@1+ (1,0) [0|510] "m" Vector__XXX
 SG_ ADCU3A_FrTar04YawAng : 454|9@1+ (1,-180) [-180|179] "°" Vector__XXX
 SG_ ADCU3A_ReTar01YawAng : 463|9@1+ (1,-180) [-180|179] "°" Vector__XXX
 SG_ ADCU3A_ReTar02YawAng : 472|9@1+ (1,-180) [-180|179] "°" Vector__XXX
 SG_ ADCU3A_ReTar03YawAng : 481|9@1+ (1,-180) [-180|179] "°" Vector__XXX
 SG_ ADCU3A_ReTar04YawAng : 490|9@1+ (1,-180) [-180|179] "°" Vector__XXX

CM_ " ";
CM_ SG_ 2566869287 VDCU_St1_CRC "CRC8";
CM_ SG_ 2566869287 VDCU_St1_AC "Alive Counter";
CM_ SG_ 2566869287 VDCU_LoglGear "Logical Gear
逻辑挡位";
CM_ SG_ 2566869287 VDCU_AccPdlPosnVld "Accelerator Pedal Position Valid
加速踏板开度有效性";
CM_ SG_ 2566869287 VDCU_AccPdlPosn "Accelerator Pedal Position 
加速踏板开度";
CM_ SG_ 2566853159 VDCU_St2_CRC "CRC8";
CM_ SG_ 2566853159 VDCU_St2_AC "Alive Counter";
CM_ SG_ 2566853159 VDCU_VehFltLvl "Vehicle fault level
整车故障等级";
CM_ SG_ 2566853159 VDCU_AdhLvl "Adhesion Level
附着等级";
CM_ SG_ 2566853159 VDCU_VehM "Vehicle Mass
整车质量";
CM_ SG_ 2566853159 VDCU_TotMilg "Total mileage
总续航里程";
CM_ SG_ 2566853415 VDCU_St5_CRC "CRC8";
CM_ SG_ 2566853415 VDCU_St5_AC "Alive Counter";
CM_ SG_ 2566853415 VDCU_LgtdCtrlAvlSt "VDCU Longitudinal control available state
VDCU纵向控制可用状态";
CM_ SG_ 2566853415 VDCU_LgtdCtrlTqActvSt "Longitudinal Control Torque Active State
纵向控制扭矩激活状态";
CM_ SG_ 2566853415 VDCU_LgtdCtrlOvrdSt "Longitudinal Control Override State
纵向控制Override状态";
CM_ SG_ 2566853415 VDCU_WhlActTq "Wheel Actual Torque
轮端实际扭矩";
CM_ SG_ 2566853671 VDCU_St6_CRC "CRC8";
CM_ SG_ 2566853671 VDCU_St6_AC "Alive Counter";
CM_ SG_ 2566853671 VDCU_VehMaxDrvTq "Vehicle Maximum Driving Torque
车辆最大驱动扭矩";
CM_ SG_ 2566853671 VDCU_VehMaxRgnTq "Vehicle Maximum Regeneration Torque 
车辆最大回收扭矩";
CM_ SG_ 2365484270 VDCU_TCO1_CRC "CRC16";
CM_ SG_ 2365484270 VDCU_TCO1_AC "Alive Counter";
CM_ SG_ 2365484270 VDCU_VehActSpdVld "Vehicle actual speed valid
整车实际车速有效性";
CM_ SG_ 2365484270 VDCU_VehDrvgDir "Direction indicator
整车行驶方向";
CM_ SG_ 2365484270 VDCU_VehActSpd "Vehicle actual speed
整车实际车速";
CM_ SG_ 2566844711 VDCU_BrkPdlSwt "Brake Pedal switch
制动踏板开关";
CM_ SG_ 2365526280 MCUF_FrMotActSpd "Actual speed of front motor
前电机实际转速";
CM_ SG_ 2365522947 TCU_St2_CRC "CRC8";
CM_ SG_ 2365522947 TCU_St2_AC "Alive Counter";
CM_ SG_ 2365522947 TCU_FrTrsmShiftSt "Front gearbox shift state
前变速箱换挡状态";
CM_ SG_ 2365523203 TCU_St3_CRC "CRC8";
CM_ SG_ 2365523203 TCU_St3_AC "Alive Counter";
CM_ SG_ 2365523203 TCU_ReTrsmShiftSt "Rear gearbox shift state
后变速箱换挡状态";
CM_ SG_ 2565865739 EBS_ASREngCtrlActv "ASR engine control active
ASR发动机控制激活";
CM_ SG_ 2565865739 EBS_ASRBrkCtrlActv "ASR brake control active
ASR制动激活";
CM_ SG_ 2565865739 EBS_ABSActv "ABS active
ABS激活";
CM_ SG_ 2565865739 EBS_BrkPdlSwt "Brake Pedal Switch
EBS制动踏板开关";
CM_ SG_ 2565865739 EBS_BrkPdlPosn "Brake pedal position
制动踏板位置";
CM_ SG_ 2565865739 EBS_ASROfrdSwt "ASR offroad switch
ASR越野开关";
CM_ SG_ 2565865739 EBS_ABSFulyOprtnl "ABS fully operational
ABS全工作状态";
CM_ SG_ 2565865739 EBS_ABSEBSAWL "ABS/EBS amber warning state
ABS/EBS黄灯警告状态";
CM_ SG_ 2565865739 EBS_ATCASRLamp "ATC/ASR lamp state
ATC/ASR灯状态";
CM_ SG_ 2566831883 EBS_TwoFrAxleSpd "Two front axle speed
前轴速度";
CM_ SG_ 2566767627 EBS_HaltBrkMod "Halt brake mode
临停制动状态模式";
CM_ SG_ 2566767627 EBS_XBRSysSt "XBR system state
外部制动状态";
CM_ SG_ 2566767627 EBS_XBRActvCtrlMod "XBR主动控制模式";
CM_ SG_ 2566767627 EBS_XBRAcclLimit "XBR acceleration limit
外部加速度限值";
CM_ SG_ 2566767627 EBS_EmgyBrkgActv "Emergency braking active
紧急制动激活";
CM_ SG_ 2566803211 EBS_VDCLamp "VDC lamp state
VDC灯状态";
CM_ SG_ 2566803211 EBS_VDCFulyOprtnl "VDC fully operational
VDC工作状态";
CM_ SG_ 2566803211 EBS_ROPEngCtrlActv "ROP engine control active
防侧倾发动机控制激活状态";
CM_ SG_ 2566803211 EBS_ROPBrkCtrlActv "ROP brake control active
防侧倾制动控制激活状态";
CM_ SG_ 2566803211 EBS_YCEngCtrlActv "YC engine control active
横摆角速度发动机控制激活状态";
CM_ SG_ 2566803211 EBS_YCBrkCtrlActv "YC brake control active
横摆角速度制动控制激活状态";
CM_ SG_ 2565867787 EBS_SteerAng "Steering Angle
EBS方向盘转角";
CM_ SG_ 2565867787 EBS_YawRate "Yaw Rate
YRS横摆角速度";
CM_ SG_ 2565867787 EBS_LatAccl "Lateral Acceleration
YRS横向加速度";
CM_ SG_ 2565867787 EBS_LgtdAccl "Longitudinal Acceleration
YRS纵向加速度";
CM_ SG_ 2298375691 EBS_LFWhlSpd "Left Front Wheel Speed
左前轮速";
CM_ SG_ 2298375691 EBS_RFWhlSpd "Right Front Wheel Speed
右前轮速";
CM_ SG_ 2298375691 EBS_LRWhlSpd "Left Rear Wheel Speed
左后轮速";
CM_ SG_ 2298375691 EBS_RRWhlSpd "Right Rear Wheel Speed
右后轮速";
CM_ SG_ 2566858515 EHPSM_St1_CRC "CRC8";
CM_ SG_ 2566858515 EHPSM_St1_AC "Alive Counter";
CM_ SG_ 2566858515 EHPSM_HISFctReq "EHPS-M function request
EHPS-M响应HIS状态";
CM_ SG_ 2566858515 EHPSM_AvlStForHIS "EHPS-M HWP available state
EHPS-M响应HIS功能的使能状态";
CM_ SG_ 2566858515 EHPSM_AngCmdOverRng "EHPS-M over range feedback
EHPS-M反馈请求目标超限";
CM_ SG_ 2566858515 EHPSM_DrvrInpTqVal "Driver input torque value
EHPS-M反馈主驾手力矩";
CM_ SG_ 2566858515 EHPSM_DrvrInpTqValVld "Driver input torque value valid
EHPS-M反馈主驾手力矩有效性";
CM_ SG_ 2566858515 EHPSM_ErrRsnFB "Error Reason Feedback
EHPS-M反馈故障的原因";
CM_ SG_ 2566858515 EHPSM_WrkMod "Controller working mode
EHPS-M控制器工作模式";
CM_ SG_ 2365540115 EHPSM_St2_CRC "CRC8";
CM_ SG_ 2365540115 EHPSM_St2_AC "Alive Counter";
CM_ SG_ 2365540115 EHPSM_SteerAngVld "EHPS-M Steering Angle Valid
EHPS-M方向盘转角有效性";
CM_ SG_ 2365540115 EHPSM_CalSt "EHPS-M Zero Calibration State
EHPS-M零点标定状态";
CM_ SG_ 2365540115 EHPSM_SteerAgrSpd "EHPS-M Steering Angular Speed
EHPS-M方向盘转向角速度";
CM_ SG_ 2365540115 EHPSM_SteerAng "EHPS-M Steering Angle
EHPS-M方向盘转角";
CM_ SG_ 2365540115 EHPSM_SteerMotTq "EHPS-M Motor Output Torque
EHPS-M电机输出扭矩";
CM_ SG_ 2365540115 EHPSM_CntreAdptvOffsAng "EHPS-M Steering Neutral Adaptive Offset Angle
EHPS-M转向中位自适应偏移角度";
CM_ SG_ 2365540115 EHPSM_SteerTq "EHPS-M Steering Wheel Steering Torque
EHPS-M方向盘转向力矩";
CM_ SG_ 2566787664 EPB_EPBPrkgSt "EPB Parking State
EPB驻车状态";
CM_ SG_ 2566787664 EPB_WrkMod "Working Mode
工作模式";
CM_ SG_ 2566787664 EPB_ErrCod "EPB System Error
EPB系统故障";
CM_ SG_ 2566787664 EPB_EPBApplyKey "EPB Apply Key
EPB夹紧按键";
CM_ SG_ 2566787664 EPB_SysSt "System State
系统是否能响应无人驾驶";
CM_ SG_ 2365562448 EPB_MsgSrc "The Source Address Of The EPBC1 Active Unit
当前响应的报文源";
CM_ SG_ 2365562448 EPB_BrkPosn "EPB Electronic Switch Travel
EPB电子开关行程";
CM_ SG_ 2365562448 EPB_EPBWrkSt "EPB Work State
EPB工作状态";
CM_ SG_ 2365562448 EPB_LgtdCtrlAvlSt "Available Status Of EPB Longitudinal Control
EPB纵向控制可用状态";
CM_ SG_ 2365562448 EPB_PBrkPrs "Park Brake Pressure
驻车输出气压";
CM_ SG_ 2365562448 EPB_ErrSt "Total Number Of System Faults
系统故障总数";
CM_ SG_ 2365562448 EPB_PBrkRlsInhbn "Park Brake Release Inhibition
驻车释放抑制";
CM_ SG_ 2365562448 EPB_PBrkInhbn "Park Brake Inhibition
驻车执行抑制";
CM_ SG_ 2365562448 EPB_HaltBrakeSt "临停控制状态，ADCU直接请求EBS临停，通过该状态去判断EBS能够执行临停";
CM_ SG_ 2566799649 BDCU_LoLgtSwt "Low Light Switch
近光灯开关";
CM_ SG_ 2566799649 BDCU_HiLgtSwt "High Light Switch
远光灯开关";
CM_ SG_ 2566799649 BDCU_RightTurnLgtSwt "Right Turn Light Switch
右转向灯开关";
CM_ SG_ 2566799649 BDCU_LeftTurnLgtSwt "Left Turn Light Switch
左转向灯开关";
CM_ SG_ 2566799649 BDCU_HzrdLgtKey "Hazard Light Key
危险警报灯开关";
CM_ SG_ 2566799393 BDCU_HiLgtHdLgtSt "High Light State
远光灯状态";
CM_ SG_ 2566799393 BDCU_FrFogLgtSt "Front Fog Light State
前雾灯状态";
CM_ SG_ 2566799393 BDCU_LoLgtHdLgtSt "Low Light State
近光灯状态";
CM_ SG_ 2566799393 BDCU_StopLgtSt "Tractor Brake Light State
主车制动灯状态";
CM_ SG_ 2566799393 BDCU_ReFogLgtSt "Rear Fog Light State
后雾灯状态";
CM_ SG_ 2566799393 BDCU_TurnSigLgtSt "Turn Light State
转向灯状态";
CM_ SG_ 2566879009 BDCU_LgtSt_CRC "CRC8";
CM_ SG_ 2566879009 BDCU_LgtSt_AC "Alive Counter";
CM_ SG_ 2566879009 BDCU_HzrdLgtSt "Hazard Warning Light State
危险警报灯状态";
CM_ SG_ 2566891297 BDCU_DrvrSeatOccptSt "Driver Seat Occupancy State
主驾座椅占位状态";
CM_ SG_ 2566891297 BDCU_DrvrSeatBltSt "Driver Seat Belt State
主驾安全带状态";
CM_ SG_ 2566891297 BDCU_PassgSeatBltSt "Passenger Seat Belt State
副驾安全带状态";
CM_ SG_ 2566891297 BDCU_PassgSeatOccptSt "Passenger Seat Occupancy State
副驾座椅占位状态";
CM_ SG_ 2566879265 BDCU_St2_CRC "CRC8";
CM_ SG_ 2566879265 BDCU_St2_AC "Alive Counter";
CM_ SG_ 2566879265 BDCU_LqdLvlSt "Washing Fluid Level State
洗涤液液位状态";
CM_ SG_ 2566879265 BDCU_HornWrkSt "Speaker Working State
喇叭工作状态";
CM_ SG_ 2566879265 BDCU_TrlrCnctnSt "Trailer Connection State
挂车连接状态";
CM_ SG_ 2566879265 BDCU_WshngPmpErr "洗涤泵故障状态";
CM_ SG_ 2566879265 BDCU_RLSWiprSpdReq "自动雨刮速度请求";
CM_ SG_ 2566879265 BDCU_LVPwrSt "Low Voltage Power State
低压电源状态";
CM_ SG_ 2566879265 BDCU_PCSWiprCombSwt "雨刮组合开关状态";
CM_ SG_ 2566879265 BDCU_RLSBri "Ambient Light Intensity
环境光强度";
CM_ SG_ 2566858220 DDCM_CRC "CRC8";
CM_ SG_ 2566858220 DDCM_AC "Alive Counter";
CM_ SG_ 2566858220 DDCM_DrvrWindwPosn "Driver window opening feedback
主驾车窗开度反馈";
CM_ SG_ 2566878956 DDCM_St2_CRC "CRC8";
CM_ SG_ 2566878956 DDCM_St2_AC "Alive Counter";
CM_ SG_ 2566878956 DDCM_DrvrDoorAjarSt "Driver driver door state
主驾车门状态";
CM_ SG_ 2566862317 PDCM_St1_CRC "CRC8";
CM_ SG_ 2566862317 PDCM_St1_AC "Alive Counter";
CM_ SG_ 2566862317 PDCM_PassgWindwPosn "Passenger window opening feedback
副驾车窗开度反馈";
CM_ SG_ 2566862317 PDCM_PassgDoorAjarSt "Passenger door state
副驾车门状态";
CM_ SG_ 2566886241 HOD_Swt_CRC "CRC8";
CM_ SG_ 2566886241 HOD_Swt_AC "Alive Counter";
CM_ SG_ 2566886241 HOD_SteerWhlVibrnSt "Steering wheel vibration state
方向盘震动";
CM_ SG_ 2566886241 HOD_HandOnMonrSt1 "Hands-off monitor state 1
离手检测状态1";
CM_ SG_ 2566886241 HOD_HandOnMonrSt2 "Hands-off monitor state 2
离手检测状态2";
CM_ SG_ 2566886241 HOD_LeftZoneMonr "Steering wheel Left zoning monitoring
方向盘左区监测";
CM_ SG_ 2566886241 HOD_RightZoneMonr "Steering wheel Right zoning monitoring
方向盘右区监测";
CM_ SG_ 2566886241 HOD_LeftHandOffDtcnSnsrErr "Left Hands-off detection sensor Error
左侧离手监测传感器故障";
CM_ SG_ 2566886241 HOD_RightHandOffDtcnSnsrErr "Right Hands-off detection sensor Error
右侧离手监测传感器故障";
CM_ SG_ 2566886241 HOD_OutsdHandOffDtcnSnsrErr "Outside Hands-off detection sensor Error
外测离手监测传感器故障";
CM_ SG_ 2566886241 HOD_VibrnMotErr "Vibration motor Error
震动电机故障";
CM_ SG_ 2566845491 TPMS_TireHiTWarn "High temperature warning
轮胎高温报警";
CM_ SG_ 2566845491 TPMS_TireHiLoPWarn "Pressure warning
胎压压力报警";
CM_ SG_ 659 ADCU3A_St1_CRC "CRC16";
CM_ SG_ 659 ADCU3A_St1_AC "Alive Counter";
CM_ SG_ 659 ADCU3A_HNASwtFB "HNA switch Feedback
HNA功能开关状态";
CM_ SG_ 659 ADCU3A_LaneChgSwtFB "Lane change auxiliary switch feedback
变道辅助开关反馈";
CM_ SG_ 659 ADCU3A_AutoLaneChgCfmFB "Automatic lane change confirmation switch feedback
自动变道确认开关反馈";
CM_ SG_ 659 ADCU3A_AutoLaneChgRmnSetFB "Lane change reminder switch feedback
变道提醒开关反馈";
CM_ SG_ 659 ADCU3A_AutoLaneChgSetFB "Lane change style setting feedback
变道风格设置反馈";
CM_ SG_ 659 ADCU3A_HWAStudyModSwtFB "HWA study mode switch Feedback
HWA功能学习模式开关反馈";
CM_ SG_ 659 ADCU3A_HWAHNAWrkst "HWA/HNA work state
HWA/HNA工作状态";
CM_ SG_ 659 ADCU3A_ALCFctSt "HWA_ALC function state
变道辅助功能状态显示";
CM_ SG_ 659 ADCU3A_TakeOverReq "Take over request
车辆接管请求";
CM_ SG_ 659 ADCU3A_HWAHNAFctRmn "HWA_HNA function reminder
HWA/HNA功能提醒";
CM_ SG_ 659 ADCU3A_LaneChgReq "Lane Change request
变道确认请求";
CM_ SG_ 659 ADCU3A_TurnLgtClsRmn "Turn light Close reminder
转向灯关闭提醒";
CM_ SG_ 659 ADCU3A_HWAFctLamp "HWA Function Lamp
HWA功能指示灯";
CM_ SG_ 659 ADCU3A_LgtdCtrlSpdSetSt "Longitudinal control Speed set
纵向控制功能设置车速显示";
CM_ SG_ 659 ADCU3A_LgtdCtrlTigapSetSt "Longitudinal control timegap set
纵向功能时距设置时距显示";
CM_ SG_ 659 ADCU3A_LgtdCtrlTarDisp "Longitudinal control target distance display
纵向目标距离显示";
CM_ SG_ 659 ADCU3A_LeftFisrtLaneTyp "Left first lane type
左侧第一条车道线类型";
CM_ SG_ 659 ADCU3A_LeftFirstLaneTrackSt "Left First Lane Tracking Status
左侧第一条车道线跟踪状态";
CM_ SG_ 659 ADCU3A_LeftFirstLaneDy "Left first lane Dy
左侧第一车道线Y向偏移量";
CM_ SG_ 659 ADCU3A_LeftFirstLaneAngYaw "Left first lane angle Yaw
左侧第一车道线角度";
CM_ SG_ 659 ADCU3A_LeftFirstLaneCrvt "Left first lane curvature
左侧第一车道曲率";
CM_ SG_ 659 ADCU3A_LeftFirstLaneCrvtChg "Left first lane curvature change
左侧第一车道曲率变化";
CM_ SG_ 659 ADCU3A_LeftSecLaneTyp "Left second lane type
左侧第二条车道线类型";
CM_ SG_ 659 ADCU3_LeftSecLaneTrackSt "Left second Lane Tracking Status
左侧第二条车道线跟踪状态";
CM_ SG_ 659 ADCU3A_LeftSecLaneDy "Left second lane Dy
左侧第二车道线Y向偏移量";
CM_ SG_ 659 ADCU3A_LeftSecLaneAngYaw "Left second lane angle Yaw
左侧第二车道线角度";
CM_ SG_ 659 ADCU3A_LeftSecLaneCrvt "Left second lane curvature
左侧第二车道曲率";
CM_ SG_ 659 ADCU3A_LeftSecLaneCrvtChg "Left second lane curvature change
左侧第二车道曲率变化";
CM_ SG_ 659 ADCU3A_RightFisrtLaneTyp "Right first lane type
右侧第一条车道线类型";
CM_ SG_ 659 ADCU3A_RightFirstLaneTrackSt "Right First Lane Tracking Status
右侧第一条车道线跟踪状态";
CM_ SG_ 659 ADCU3A_RightFirstLaneDy "Right first lane Dy
右侧第一车道线Y向偏移量";
CM_ SG_ 659 ADCU3A_RightFirstLaneAngYaw "Right first lane angle Yaw
右侧第一车道线角度";
CM_ SG_ 659 ADCU3A_RightFirstLaneCrvt "Right first lane curvature
右侧第一车道曲率";
CM_ SG_ 659 ADCU3A_RightFirstLaneCrvtChg "Right first lane curvature change
右侧第一车道曲率变化";
CM_ SG_ 660 ADCU3A_St2_CRC "CRC16";
CM_ SG_ 660 ADCU3A_St2_AC "Alive Counter";
CM_ SG_ 660 ADCU3A_RightSecLaneTyp "Right second lane type
右侧第二条车道线类型";
CM_ SG_ 660 ADCU3_RightSecLaneTrackSt "Right second Lane Tracking Status
右侧第二条车道线跟踪状态";
CM_ SG_ 660 ADCU3A_RightSecLaneDy "Right second lane Dy
右侧第二车道线Y向偏移量";
CM_ SG_ 660 ADCU3A_RightSecLaneAngYaw "Right second lane angle Yaw
右侧第二车道线角度";
CM_ SG_ 660 ADCU3A_RightSecLaneCrvt "Right second lane curvature
右侧第二车道曲率";
CM_ SG_ 660 ADCU3A_RightSecLaneCrvtChg "Right second lane curvature change
右侧第二车道曲率变化";
CM_ SG_ 660 ADCU3A_LeftTar01YawAng "Left target01 Yaw Angle
左侧目标01航向角";
CM_ SG_ 660 ADCU3A_LeftTar02YawAng "Left target02 Yaw Angle
左侧目标02航向角";
CM_ SG_ 660 ADCU3A_LeftTar03YawAng "Left target03 Yaw Angle
左侧目标03航向角";
CM_ SG_ 660 ADCU3A_LeftTar04YawAng "Left target04 Yaw Angle
左侧目标04航向角";
CM_ SG_ 660 ADCU3A_LeftTar05YawAng "Left target05 Yaw Angle
左侧目标05航向角";
CM_ SG_ 660 ADCU3A_LeftTar06YawAng "Left target06 Yaw Angle
左侧目标06航向角";
CM_ SG_ 660 ADCU3A_LeftTar07YawAng "Left target07 Yaw Angle
左侧目标07航向角";
CM_ SG_ 660 ADCU3A_LeftTar08YawAng "Left target08 Yaw Angle
左侧目标08航向角";
CM_ SG_ 660 ADCU3A_RightTar01YawAng "Right target01 Yaw Angle
右侧目标01航向角";
CM_ SG_ 660 ADCU3A_RightTar02YawAng "Right target02 Yaw Angle
右侧目标02航向角";
CM_ SG_ 660 ADCU3A_RightTar03YawAng "Right target03 Yaw Angle
右侧目标03航向角";
CM_ SG_ 660 ADCU3A_RightTar04YawAng "Right target04 Yaw Angle
右侧目标04航向角";
CM_ SG_ 660 ADCU3A_RightTar05YawAng "Right target05 Yaw Angle
右侧目标05航向角";
CM_ SG_ 660 ADCU3A_RightTar06YawAng "Right target06 Yaw Angle
右侧目标06航向角";
CM_ SG_ 660 ADCU3A_RightTar07YawAng "Right target07 Yaw Angle
右侧目标07航向角";
CM_ SG_ 660 ADCU3A_RightTar08YawAng "Right target08 Yaw Angle
右侧目标08航向角";
CM_ SG_ 660 ADCU3A_LgtdCtrlMainTarID "Main target ID
主目标ID";
CM_ SG_ 660 ADCU3A_LeftTar01Dtcd "Left target01 detected
左侧目标01探测";
CM_ SG_ 660 ADCU3A_LeftTar01ID "Left target01 ID
左侧目标01ID";
CM_ SG_ 660 ADCU3A_LeftTar01Typ "Left target01 type
左侧目标01类型";
CM_ SG_ 660 ADCU3A_LeftTar01Dx "Left target01_Dx
左侧目标01_X值";
CM_ SG_ 660 ADCU3A_LeftTar01Dy "Left target01_Dy
左侧目标01_Y值";
CM_ SG_ 660 ADCU3A_LeftTar02Dtcd "Left target02 detected
左侧目标02探测";
CM_ SG_ 660 ADCU3A_LeftTar02ID "Left target02 ID
左侧目标02ID";
CM_ SG_ 660 ADCU3A_LeftTar02Typ "Left target02 type
左侧目标02类型";
CM_ SG_ 660 ADCU3A_LeftTar02Dx "Left target02_Dx
左侧目标02_X值";
CM_ SG_ 660 ADCU3A_LeftTar02Dy "Left target02_Dy
左侧目标02_Y值";
CM_ SG_ 660 ADCU3A_LeftTar03Dtcd "Left target03 detected
左侧目标03探测";
CM_ SG_ 660 ADCU3A_LeftTar03ID "Left target03 ID
左侧目标03ID";
CM_ SG_ 660 ADCU3A_LeftTar03Typ "Left target03 type
左侧目标03类型";
CM_ SG_ 660 ADCU3A_LeftTar03Dx "Left target03_Dx
左侧目标03_X值";
CM_ SG_ 660 ADCU3A_LeftTar03Dy "Left target03_Dy
左侧目标03_Y值";
CM_ SG_ 660 ADCU3A_LeftTar04Dtcd "Left target04 detected
左侧目标04探测";
CM_ SG_ 660 ADCU3A_LeftTar04ID "Left target04 ID
左侧目标04ID";
CM_ SG_ 660 ADCU3A_LeftTar04Typ "Left target04 type
左侧目标04类型";
CM_ SG_ 660 ADCU3A_LeftTar04Dx "Left target04_Dx
左侧目标04_X值";
CM_ SG_ 660 ADCU3A_LeftTar04Dy "Left target04_Dy
左侧目标04_Y值";
CM_ SG_ 660 ADCU3A_LeftTar05Dtcd "Left target05 detected
左侧目标05探测";
CM_ SG_ 660 ADCU3A_LeftTar05ID "Left target05 ID
左侧目标05ID";
CM_ SG_ 660 ADCU3A_LeftTar05Typ "Left target05 type
左侧目标05类型";
CM_ SG_ 660 ADCU3A_LeftTar05Dx "Left target05_Dx
左侧目标05_X值";
CM_ SG_ 660 ADCU3A_LeftTar05Dy "Left target05_Dy
左侧目标05_Y值";
CM_ SG_ 660 ADCU3A_FrTar01YawAng "Front target01 Yaw Angle
前方目标01航向角";
CM_ SG_ 660 ADCU3A_FrTar02YawAng "Front target02 Yaw Angle
前方目标02航向角";
CM_ SG_ 675 ADCU3A_St3_CRC "CRC16";
CM_ SG_ 675 ADCU3A_St3_AC "Alive Counter";
CM_ SG_ 675 ADCU3A_LeftTar06Dtcd "Left target06 detected
左侧目标06探测";
CM_ SG_ 675 ADCU3A_LeftTar06ID "Left target06 ID
左侧目标06ID";
CM_ SG_ 675 ADCU3A_LeftTar06Typ "Left target06 type
左侧目标06类型";
CM_ SG_ 675 ADCU3A_LeftTar06Dx "Left target06_Dx
左侧目标06_X值";
CM_ SG_ 675 ADCU3A_LeftTar06Dy "Left target06_Dy
左侧目标06_Y值";
CM_ SG_ 675 ADCU3A_LeftTar07Dtcd "Left target07 detected
左侧目标07探测";
CM_ SG_ 675 ADCU3A_LeftTar07ID "Left target07 ID
左侧目标07ID";
CM_ SG_ 675 ADCU3A_LeftTar07Typ "Left target07 type
左侧目标07类型";
CM_ SG_ 675 ADCU3A_LeftTar07Dx "Left target07_Dx
左侧目标07_X值";
CM_ SG_ 675 ADCU3A_LeftTar07Dy "Left target07_Dy
左侧目标07_Y值";
CM_ SG_ 675 ADCU3A_LeftTar08Dtcd "Left target08 detected
左侧目标08探测";
CM_ SG_ 675 ADCU3A_LeftTar08ID "Left target08 ID
左侧目标08ID";
CM_ SG_ 675 ADCU3A_LeftTar08Typ "Left target08 type
左侧目标08类型";
CM_ SG_ 675 ADCU3A_LeftTar08Dx "Left target08_Dx
左侧目标08_X值";
CM_ SG_ 675 ADCU3A_LeftTar08Dy "Left target08_Dy
左侧目标08_Y值";
CM_ SG_ 675 ADCU3A_RightTar01Dtcd "Right target01 detected
右侧目标01探测";
CM_ SG_ 675 ADCU3A_RightTar01ID "Right target01 ID
右侧目标01ID";
CM_ SG_ 675 ADCU3A_RightTar01Typ "Right target01 type
右侧目标01类型";
CM_ SG_ 675 ADCU3A_RightTar01Dx "Right target01_Dx
右侧目标01_X值";
CM_ SG_ 675 ADCU3A_RightTar01Dy "Right target01_Dy
右侧目标01_Y值";
CM_ SG_ 675 ADCU3A_RightTar02Dtcd "Right target02 detected
右侧目标02探测";
CM_ SG_ 675 ADCU3A_RightTar02ID "Right target02 ID
右侧目标02ID";
CM_ SG_ 675 ADCU3A_RightTar02Typ "Right target02 type
右侧目标02类型";
CM_ SG_ 675 ADCU3A_RightTar02Dx "Right target02_Dx
右侧目标02_X值";
CM_ SG_ 675 ADCU3A_RightTar02Dy "Right target02_Dy
右侧目标02_Y值";
CM_ SG_ 675 ADCU3A_RightTar03Dtcd "Right target03 detected
右侧目标03探测";
CM_ SG_ 675 ADCU3A_RightTar03ID "Right target03 ID
右侧目标03ID";
CM_ SG_ 675 ADCU3A_RightTar03Typ "Right target03 type
右侧目标03类型";
CM_ SG_ 675 ADCU3A_RightTar03Dx "Right target03_Dx
右侧目标03_X值";
CM_ SG_ 675 ADCU3A_RightTar03Dy "Right target03_Dy
右侧目标03_Y值";
CM_ SG_ 675 ADCU3A_RightTar04Dtcd "Right target04 detected
右侧目标04探测";
CM_ SG_ 675 ADCU3A_RightTar04ID "Right target04 ID
右侧目标04ID";
CM_ SG_ 675 ADCU3A_RightTar04Typ "Right target04 type
右侧目标04类型";
CM_ SG_ 675 ADCU3A_RightTar04Dx "Right target04_Dx
右侧目标04_X值";
CM_ SG_ 675 ADCU3A_RightTar04Dy "Right target04_Dy
右侧目标04_Y值";
CM_ SG_ 675 ADCU3A_RightTar05Dtcd "Right target05 detected
右侧目标05探测";
CM_ SG_ 675 ADCU3A_RightTar05ID "Right target05 ID
右侧目标05ID";
CM_ SG_ 675 ADCU3A_RightTar05Typ "Right target05 type
右侧目标05类型";
CM_ SG_ 675 ADCU3A_RightTar05Dx "Right target05_Dx
右侧目标05_X值";
CM_ SG_ 675 ADCU3A_RightTar05Dy "Right target05_Dy
右侧目标05_Y值";
CM_ SG_ 675 ADCU3A_RightTar06Dtcd "Right target06 detected
右侧目标06探测";
CM_ SG_ 675 ADCU3A_RightTar06ID "Right target06 ID
右侧目标06ID";
CM_ SG_ 675 ADCU3A_RightTar06Typ "Right target06 type
右侧目标06类型";
CM_ SG_ 675 ADCU3A_RightTar06Dx "Right target06_Dx
右侧目标06_X值";
CM_ SG_ 675 ADCU3A_RightTar06Dy "Right target06_Dy
右侧目标06_Y值";
CM_ SG_ 675 ADCU3A_RightTar07Dtcd "Right target07 detected
右侧目标07探测";
CM_ SG_ 675 ADCU3A_RightTar07ID "Right target07 ID
右侧目标07ID";
CM_ SG_ 675 ADCU3A_RightTar07Typ "Right target07 type
右侧目标07类型";
CM_ SG_ 675 ADCU3A_RightTar07Dx "Right target07_Dx
右侧目标07_X值";
CM_ SG_ 675 ADCU3A_RightTar07Dy "Right target07_Dy
右侧目标07_Y值";
CM_ SG_ 675 ADCU3A_RightTar08Dtcd "Right target08 detected
右侧目标08探测";
CM_ SG_ 675 ADCU3A_RightTar08ID "Right target08 ID
右侧目标08ID";
CM_ SG_ 675 ADCU3A_RightTar08Typ "Right target08 type
右侧目标08类型";
CM_ SG_ 675 ADCU3A_RightTar08Dx "Right target08_Dx
右侧目标08_X值";
CM_ SG_ 675 ADCU3A_RightTar08Dy "Right target08_Dy
右侧目标08_Y值";
CM_ SG_ 675 ADCU3A_FrTar03YawAng "Front target03 Yaw Angle
前方目标03航向角";
CM_ SG_ 676 ADCU3A_St4_CRC "CRC16";
CM_ SG_ 676 ADCU3A_St4_AC "Alive Counter";
CM_ SG_ 676 ADCU3A_FrTar01Dtcd "Front target01 detected
前方目标01探测";
CM_ SG_ 676 ADCU3A_FrTar01ID "Front target01 ID
前方目标01ID";
CM_ SG_ 676 ADCU3A_FrTar01Typ "Front target01 type
前方目标01类型";
CM_ SG_ 676 ADCU3A_FrTar01Dx "Front target01_Dx
前方目标01_X值";
CM_ SG_ 676 ADCU3A_FrTar01Dy "Front target01_Dy
前方目标01_Y值";
CM_ SG_ 676 ADCU3A_FrTar02Dtcd "Front target02 detected
前方目标02探测";
CM_ SG_ 676 ADCU3A_FrTar02ID "Front target02 ID
前方目标02ID";
CM_ SG_ 676 ADCU3A_FrTar02Typ "Front target02 type
前方目标02类型";
CM_ SG_ 676 ADCU3A_FrTar02Dx "Front target02_Dx
前方目标02_X值";
CM_ SG_ 676 ADCU3A_FrTar02Dy "Front target02_Dy
前方目标02_Y值";
CM_ SG_ 676 ADCU3A_FrTar03Dtcd "Front target03 detected
前方目标03探测";
CM_ SG_ 676 ADCU3A_FrTar03ID "Front target03 ID
前方目标03ID";
CM_ SG_ 676 ADCU3A_FrTar03Typ "Front target03 type
前方目标03类型";
CM_ SG_ 676 ADCU3A_FrTar03Dx "Front target03_Dx
前方目标03_X值";
CM_ SG_ 676 ADCU3A_FrTar03Dy "Front target03_Dy
前方目标03_Y值";
CM_ SG_ 676 ADCU3A_FrTar04Dtcd "Front target04 detected
前方目标04探测";
CM_ SG_ 676 ADCU3A_FrTar04ID "Front target04 ID
前方目标04ID";
CM_ SG_ 676 ADCU3A_FrTar04Typ "Front target04 type
前方目标04类型";
CM_ SG_ 676 ADCU3A_FrTar04Dx "Front target04_Dx
前方目标04_X值";
CM_ SG_ 676 ADCU3A_FrTar04Dy "Front target04_Dy
前方目标04_Y值";
CM_ SG_ 676 ADCU3A_ReTar01Dtcd "Rear target01 detected
后方目标01探测";
CM_ SG_ 676 ADCU3A_ReTar01ID "Rear target01 ID
后方目标01ID";
CM_ SG_ 676 ADCU3A_ReTar01Typ "Rear target01 type
后方目标01类型";
CM_ SG_ 676 ADCU3A_ReTar01Dx "Rear target01_Dx
后方目标01_X值";
CM_ SG_ 676 ADCU3A_ReTar01Dy "Rear target01_Dy
后方目标01_Y值";
CM_ SG_ 676 ADCU3A_ReTar02Dtcd "Rear target02 detected
后方目标02探测";
CM_ SG_ 676 ADCU3A_ReTar02ID "Rear target02 ID
后方目标02ID";
CM_ SG_ 676 ADCU3A_ReTar02Typ "Rear target02 type
后方目标02类型";
CM_ SG_ 676 ADCU3A_ReTar02Dx "Rear target02_Dx
后方目标02_X值";
CM_ SG_ 676 ADCU3A_ReTar02Dy "Rear target02_Dy
后方目标02_Y值";
CM_ SG_ 676 ADCU3A_ReTar03Dtcd "Rear target03 detected
后方目标03探测";
CM_ SG_ 676 ADCU3A_ReTar03ID "Rear target03 ID
后方目标03ID";
CM_ SG_ 676 ADCU3A_ReTar03Typ "Rear target03 type
后方目标03类型";
CM_ SG_ 676 ADCU3A_ReTar03Dx "Rear target03_Dx
后方目标03_X值";
CM_ SG_ 676 ADCU3A_ReTar03Dy "Rear target03_Dy
后方目标03_Y值";
CM_ SG_ 676 ADCU3A_ReTar04Dtcd "Rear target04 detected
后方目标04探测";
CM_ SG_ 676 ADCU3A_ReTar04ID "Rear target04 ID
后方目标04ID";
CM_ SG_ 676 ADCU3A_ReTar04Typ "Rear target04 type
后方目标04类型";
CM_ SG_ 676 ADCU3A_ReTar04Dx "Rear target04_Dx
后方目标04_X值";
CM_ SG_ 676 ADCU3A_ReTar04Dy "Rear target04_Dy
后方目标04_Y值";
CM_ SG_ 676 ADCU3A_VehTarLeadLaneDir "Vehicle target lead lane direction
车辆目标方向引导线";
CM_ SG_ 676 ADCU3A_VehTarLeadLaneColr "Vehicle target lead lane colour
车辆目标方向引导线颜色";
CM_ SG_ 676 ADCU3A_VehTarLeadLaneC0 "Vehicle target lead lane eqution C0 When HNA Active
HNA开启时引导线五阶方程常数项";
CM_ SG_ 676 ADCU3A_VehTarLeadLaneC1 "Vehicle target lead lane eqution C1 When HNA Active
HNA开启时引导线五阶方程一次项";
CM_ SG_ 676 ADCU3A_VehTarLeadLaneC2 "Vehicle target lead lane eqution C2 When HNA Active
HNA开启时引导线五阶方程二次项";
CM_ SG_ 676 ADCU3A_VehTarLeadLaneC3 "Vehicle target lead lane eqution C3 When HNA Active
HNA开启时引导线五阶方程三次项";
CM_ SG_ 676 ADCU3A_VehTarLeadLaneC4 "Vehicle target lead lane eqution C4 When HNA Active
HNA开启时引导线五阶方程四次项";
CM_ SG_ 676 ADCU3A_VehTarLeadLaneC5 "Vehicle target lead lane eqution C5 When HNA Active
HNA开启时引导线五阶方程五次项";
CM_ SG_ 676 ADCU3A_VehCurrLeadLaneDir "Vehicle current lead lane direction
车辆当前行驶方向引导线";
CM_ SG_ 676 ADCU3A_VehCurrLeadLaneColr "Vehicle current lead lane colour
车辆当前行驶方向引导线颜色";
CM_ SG_ 676 ADCU3A_VehCurrLeadLaneLen "Vehicle current lead lane Length
引导线X向最大距离";
CM_ SG_ 676 ADCU3A_FrTar04YawAng "Front target04 Yaw Angle
前方目标04航向角";
CM_ SG_ 676 ADCU3A_ReTar01YawAng "Rear target01 Yaw Angle
后方目标01航向角";
CM_ SG_ 676 ADCU3A_ReTar02YawAng "Rear target02 Yaw Angle
后方目标02航向角";
CM_ SG_ 676 ADCU3A_ReTar03YawAng "Rear target03 Yaw Angle
后方目标03航向角";
CM_ SG_ 676 ADCU3A_ReTar04YawAng "Rear target04 Yaw Angle
后方目标04航向角";
BA_DEF_ BO_  "DiagState" ENUM  "No","Yes";
BA_DEF_ BO_  "GenMsgSendType" ENUM  "Cyclic","Event","IfActive","CE","CA","NoMsgSendType";
BA_DEF_ BO_  "GenMsgCycleTime" INT 0 0;
BA_DEF_ SG_  "GenSigSendType" ENUM  "Cyclic","OnChange","OnWrite","IfActive","OnChangeWithRepetition","OnWriteWithRepetition","IfActiveWithRepetition","NoSigSendType","OnChangeAndIfActive","OnChangeAndIfActiveWithRepetition","CA","CE","Event";
BA_DEF_ SG_  "GenSigStartValue" INT 0 0;
BA_DEF_ BO_  "GenMsgCycleTimeFast" INT 0 0;
BA_DEF_  "DBName" STRING ;
BA_DEF_ BO_  "CANFD_BRS" ENUM  "0","1";
BA_DEF_ BO_  "VFrameFormat" ENUM  "StandardCAN","ExtendedCAN","reserved","reserved","reserved","reserved","reserved","reserved","reserved","reserved","reserved","reserved","reserved","reserved","StandardCAN_FD","ExtendedCAN_FD";
BA_DEF_  "NmMessageCount" INT 0 255;
BA_DEF_  "NmBaseAddress" HEX 1024 1087;
BA_DEF_  "BusType" STRING ;
BA_DEF_DEF_  "DiagState" "No";
BA_DEF_DEF_  "GenMsgSendType" "Cyclic";
BA_DEF_DEF_  "GenMsgCycleTime" 0;
BA_DEF_DEF_  "GenSigSendType" "Cyclic";
BA_DEF_DEF_  "GenSigStartValue" 0;
BA_DEF_DEF_  "GenMsgCycleTimeFast" 0;
BA_DEF_DEF_  "DBName" "";
BA_DEF_DEF_  "CANFD_BRS" "1";
BA_DEF_DEF_  "VFrameFormat" "StandardCAN_FD";
BA_DEF_DEF_  "NmMessageCount" 128;
BA_DEF_DEF_  "NmBaseAddress" 1024;
BA_DEF_DEF_  "BusType" "CAN FD";
BA_ "DBName" "SXXT1_CANFD_ADCU3_ADBackbone";
BA_ "GenMsgCycleTime" BO_ 2566869287 20;
BA_ "VFrameFormat" BO_ 2566869287 15;
BA_ "GenMsgCycleTime" BO_ 2566853159 100;
BA_ "VFrameFormat" BO_ 2566853159 15;
BA_ "GenMsgCycleTime" BO_ 2566853415 20;
BA_ "VFrameFormat" BO_ 2566853415 15;
BA_ "GenMsgCycleTime" BO_ 2566853671 100;
BA_ "VFrameFormat" BO_ 2566853671 15;
BA_ "GenMsgCycleTime" BO_ 2365484270 20;
BA_ "VFrameFormat" BO_ 2365484270 15;
BA_ "GenMsgCycleTime" BO_ 2566844711 100;
BA_ "VFrameFormat" BO_ 2566844711 15;
BA_ "GenMsgCycleTime" BO_ 2365526280 20;
BA_ "VFrameFormat" BO_ 2365526280 15;
BA_ "GenMsgCycleTime" BO_ 2365522947 10;
BA_ "VFrameFormat" BO_ 2365522947 15;
BA_ "GenMsgCycleTime" BO_ 2365523203 10;
BA_ "VFrameFormat" BO_ 2365523203 15;
BA_ "GenMsgCycleTime" BO_ 2565865739 100;
BA_ "VFrameFormat" BO_ 2565865739 15;
BA_ "GenMsgCycleTime" BO_ 2566831883 50;
BA_ "VFrameFormat" BO_ 2566831883 15;
BA_ "GenMsgCycleTime" BO_ 2566767627 100;
BA_ "VFrameFormat" BO_ 2566767627 15;
BA_ "GenMsgCycleTime" BO_ 2566803211 100;
BA_ "VFrameFormat" BO_ 2566803211 15;
BA_ "GenMsgCycleTime" BO_ 2565867787 10;
BA_ "VFrameFormat" BO_ 2565867787 15;
BA_ "GenMsgCycleTime" BO_ 2298375691 20;
BA_ "VFrameFormat" BO_ 2298375691 15;
BA_ "GenMsgCycleTime" BO_ 2566858515 20;
BA_ "VFrameFormat" BO_ 2566858515 15;
BA_ "GenMsgCycleTime" BO_ 2365540115 10;
BA_ "VFrameFormat" BO_ 2365540115 15;
BA_ "GenMsgCycleTime" BO_ 2566787664 100;
BA_ "VFrameFormat" BO_ 2566787664 15;
BA_ "GenMsgCycleTime" BO_ 2365562448 20;
BA_ "VFrameFormat" BO_ 2365562448 15;
BA_ "GenMsgCycleTime" BO_ 2566799649 100;
BA_ "VFrameFormat" BO_ 2566799649 15;
BA_ "GenMsgCycleTime" BO_ 2566799393 50;
BA_ "VFrameFormat" BO_ 2566799393 15;
BA_ "GenMsgCycleTime" BO_ 2566879009 100;
BA_ "VFrameFormat" BO_ 2566879009 15;
BA_ "GenMsgCycleTime" BO_ 2566891297 50;
BA_ "VFrameFormat" BO_ 2566891297 15;
BA_ "GenMsgCycleTime" BO_ 2566879265 100;
BA_ "VFrameFormat" BO_ 2566879265 15;
BA_ "GenMsgCycleTime" BO_ 2566858220 100;
BA_ "VFrameFormat" BO_ 2566858220 15;
BA_ "GenMsgCycleTime" BO_ 2566878956 50;
BA_ "VFrameFormat" BO_ 2566878956 15;
BA_ "GenMsgCycleTime" BO_ 2566862317 50;
BA_ "VFrameFormat" BO_ 2566862317 15;
BA_ "GenMsgCycleTime" BO_ 2566886241 50;
BA_ "VFrameFormat" BO_ 2566886241 15;
BA_ "GenMsgCycleTime" BO_ 2566845491 500;
BA_ "VFrameFormat" BO_ 2566845491 15;
BA_ "GenMsgCycleTime" BO_ 659 50;
BA_ "GenMsgCycleTime" BO_ 660 50;
BA_ "GenMsgCycleTime" BO_ 675 50;
BA_ "GenMsgCycleTime" BO_ 676 50;
BA_ "GenSigStartValue" SG_ 2566845491 TPMS_TireHiTWarn 3;
BA_ "GenSigStartValue" SG_ 2566845491 TPMS_TireHiLoPWarn 7;
BA_ "GenSigStartValue" SG_ 659 ADCU3A_LeftFirstLaneDy 4096;
BA_ "GenSigStartValue" SG_ 659 ADCU3A_LeftFirstLaneAngYaw 32000;
BA_ "GenSigStartValue" SG_ 659 ADCU3A_LeftFirstLaneCrvt 32000;
BA_ "GenSigStartValue" SG_ 659 ADCU3A_LeftFirstLaneCrvtChg 32000;
BA_ "GenSigStartValue" SG_ 659 ADCU3A_LeftSecLaneDy 4096;
BA_ "GenSigStartValue" SG_ 659 ADCU3A_LeftSecLaneAngYaw 32000;
BA_ "GenSigStartValue" SG_ 659 ADCU3A_LeftSecLaneCrvt 32000;
BA_ "GenSigStartValue" SG_ 659 ADCU3A_LeftSecLaneCrvtChg 32000;
BA_ "GenSigStartValue" SG_ 659 ADCU3A_RightFirstLaneDy 4096;
BA_ "GenSigStartValue" SG_ 659 ADCU3A_RightFirstLaneAngYaw 32000;
BA_ "GenSigStartValue" SG_ 659 ADCU3A_RightFirstLaneCrvt 32000;
BA_ "GenSigStartValue" SG_ 659 ADCU3A_RightFirstLaneCrvtChg 32000;
BA_ "GenSigStartValue" SG_ 660 ADCU3A_RightSecLaneDy 4096;
BA_ "GenSigStartValue" SG_ 660 ADCU3A_RightSecLaneAngYaw 32000;
BA_ "GenSigStartValue" SG_ 660 ADCU3A_RightSecLaneCrvt 32000;
BA_ "GenSigStartValue" SG_ 660 ADCU3A_RightSecLaneCrvtChg 32000;
BA_ "GenSigStartValue" SG_ 660 ADCU3A_LeftTar01YawAng 180;
BA_ "GenSigStartValue" SG_ 660 ADCU3A_LeftTar02YawAng 180;
BA_ "GenSigStartValue" SG_ 660 ADCU3A_LeftTar03YawAng 180;
BA_ "GenSigStartValue" SG_ 660 ADCU3A_LeftTar04YawAng 180;
BA_ "GenSigStartValue" SG_ 660 ADCU3A_LeftTar05YawAng 180;
BA_ "GenSigStartValue" SG_ 660 ADCU3A_LeftTar06YawAng 180;
BA_ "GenSigStartValue" SG_ 660 ADCU3A_LeftTar07YawAng 180;
BA_ "GenSigStartValue" SG_ 660 ADCU3A_LeftTar08YawAng 180;
BA_ "GenSigStartValue" SG_ 660 ADCU3A_RightTar01YawAng 180;
BA_ "GenSigStartValue" SG_ 660 ADCU3A_RightTar02YawAng 180;
BA_ "GenSigStartValue" SG_ 660 ADCU3A_RightTar03YawAng 180;
BA_ "GenSigStartValue" SG_ 660 ADCU3A_RightTar04YawAng 180;
BA_ "GenSigStartValue" SG_ 660 ADCU3A_RightTar05YawAng 180;
BA_ "GenSigStartValue" SG_ 660 ADCU3A_RightTar06YawAng 180;
BA_ "GenSigStartValue" SG_ 660 ADCU3A_RightTar07YawAng 180;
BA_ "GenSigStartValue" SG_ 660 ADCU3A_RightTar08YawAng 180;
BA_ "GenSigStartValue" SG_ 660 ADCU3A_LeftTar01Dx 3600;
BA_ "GenSigStartValue" SG_ 660 ADCU3A_LeftTar01Dy 3600;
BA_ "GenSigStartValue" SG_ 660 ADCU3A_LeftTar02Dx 3600;
BA_ "GenSigStartValue" SG_ 660 ADCU3A_LeftTar02Dy 3600;
BA_ "GenSigStartValue" SG_ 660 ADCU3A_LeftTar03Dx 3600;
BA_ "GenSigStartValue" SG_ 660 ADCU3A_LeftTar03Dy 3600;
BA_ "GenSigStartValue" SG_ 660 ADCU3A_LeftTar04Dx 3600;
BA_ "GenSigStartValue" SG_ 660 ADCU3A_LeftTar04Dy 3600;
BA_ "GenSigStartValue" SG_ 660 ADCU3A_LeftTar05Dx 3600;
BA_ "GenSigStartValue" SG_ 660 ADCU3A_LeftTar05Dy 3600;
BA_ "GenSigStartValue" SG_ 660 ADCU3A_FrTar01YawAng 180;
BA_ "GenSigStartValue" SG_ 660 ADCU3A_FrTar02YawAng 180;
BA_ "GenSigStartValue" SG_ 675 ADCU3A_LeftTar06Dx 3600;
BA_ "GenSigStartValue" SG_ 675 ADCU3A_LeftTar06Dy 3600;
BA_ "GenSigStartValue" SG_ 675 ADCU3A_LeftTar07Dx 3600;
BA_ "GenSigStartValue" SG_ 675 ADCU3A_LeftTar07Dy 3600;
BA_ "GenSigStartValue" SG_ 675 ADCU3A_LeftTar08Dx 3600;
BA_ "GenSigStartValue" SG_ 675 ADCU3A_LeftTar08Dy 3600;
BA_ "GenSigStartValue" SG_ 675 ADCU3A_RightTar01Dx 3600;
BA_ "GenSigStartValue" SG_ 675 ADCU3A_RightTar01Dy 3600;
BA_ "GenSigStartValue" SG_ 675 ADCU3A_RightTar02Dx 3600;
BA_ "GenSigStartValue" SG_ 675 ADCU3A_RightTar02Dy 3600;
BA_ "GenSigStartValue" SG_ 675 ADCU3A_RightTar03Dx 3600;
BA_ "GenSigStartValue" SG_ 675 ADCU3A_RightTar03Dy 3600;
BA_ "GenSigStartValue" SG_ 675 ADCU3A_RightTar04Dx 3600;
BA_ "GenSigStartValue" SG_ 675 ADCU3A_RightTar04Dy 3600;
BA_ "GenSigStartValue" SG_ 675 ADCU3A_RightTar05Dx 3600;
BA_ "GenSigStartValue" SG_ 675 ADCU3A_RightTar05Dy 3600;
BA_ "GenSigStartValue" SG_ 675 ADCU3A_RightTar06Dx 3600;
BA_ "GenSigStartValue" SG_ 675 ADCU3A_RightTar06Dy 3600;
BA_ "GenSigStartValue" SG_ 675 ADCU3A_RightTar07Dx 3600;
BA_ "GenSigStartValue" SG_ 675 ADCU3A_RightTar07Dy 3600;
BA_ "GenSigStartValue" SG_ 675 ADCU3A_RightTar08Dx 3600;
BA_ "GenSigStartValue" SG_ 675 ADCU3A_RightTar08Dy 3600;
BA_ "GenSigStartValue" SG_ 675 ADCU3A_FrTar03YawAng 180;
BA_ "GenSigStartValue" SG_ 676 ADCU3A_FrTar01Dx 3600;
BA_ "GenSigStartValue" SG_ 676 ADCU3A_FrTar01Dy 3600;
BA_ "GenSigStartValue" SG_ 676 ADCU3A_FrTar02Dx 3600;
BA_ "GenSigStartValue" SG_ 676 ADCU3A_FrTar02Dy 3600;
BA_ "GenSigStartValue" SG_ 676 ADCU3A_FrTar03Dx 3600;
BA_ "GenSigStartValue" SG_ 676 ADCU3A_FrTar03Dy 3600;
BA_ "GenSigStartValue" SG_ 676 ADCU3A_FrTar04Dx 3600;
BA_ "GenSigStartValue" SG_ 676 ADCU3A_FrTar04Dy 3600;
BA_ "GenSigStartValue" SG_ 676 ADCU3A_ReTar01Dx 3600;
BA_ "GenSigStartValue" SG_ 676 ADCU3A_ReTar01Dy 3600;
BA_ "GenSigStartValue" SG_ 676 ADCU3A_ReTar02Dx 3600;
BA_ "GenSigStartValue" SG_ 676 ADCU3A_ReTar02Dy 3600;
BA_ "GenSigStartValue" SG_ 676 ADCU3A_ReTar03Dx 3600;
BA_ "GenSigStartValue" SG_ 676 ADCU3A_ReTar03Dy 3600;
BA_ "GenSigStartValue" SG_ 676 ADCU3A_ReTar04Dx 3600;
BA_ "GenSigStartValue" SG_ 676 ADCU3A_ReTar04Dy 3600;
BA_ "GenSigStartValue" SG_ 676 ADCU3A_VehTarLeadLaneC0 55;
BA_ "GenSigStartValue" SG_ 676 ADCU3A_VehTarLeadLaneC1 220;
BA_ "GenSigStartValue" SG_ 676 ADCU3A_VehTarLeadLaneC2 509;
BA_ "GenSigStartValue" SG_ 676 ADCU3A_VehTarLeadLaneC3 1000;
BA_ "GenSigStartValue" SG_ 676 ADCU3A_VehTarLeadLaneC4 999456;
BA_ "GenSigStartValue" SG_ 676 ADCU3A_VehTarLeadLaneC5 2000000;
BA_ "GenSigStartValue" SG_ 676 ADCU3A_FrTar04YawAng 180;
BA_ "GenSigStartValue" SG_ 676 ADCU3A_ReTar01YawAng 180;
BA_ "GenSigStartValue" SG_ 676 ADCU3A_ReTar02YawAng 180;
BA_ "GenSigStartValue" SG_ 676 ADCU3A_ReTar03YawAng 180;
BA_ "GenSigStartValue" SG_ 676 ADCU3A_ReTar04YawAng 180;
VAL_ 2566869287 VDCU_LoglGear 15 "Invalid" 14 "Invalid" 13 "Invalid" 12 "Invalid" 11 "Invalid" 10 "Invalid" 9 "Invalid" 8 "Invalid" 7 "Invalid" 6 "Invalid" 5 "Dm" 4 "D" 3 "N" 2 "R" 1 "Rm" 0 "Init" ;
VAL_ 2566869287 VDCU_AccPdlPosnVld 1 "Valid" 0 "Invalid" ;
VAL_ 2566853159 VDCU_VehFltLvl 7 "Reserved" 6 "HV Off" 5 "Delay HV Off" 4 "Zero Torque" 3 "Limphome" 2 "Drive Limited" 1 "Warning" 0 "Normal" ;
VAL_ 2566853159 VDCU_AdhLvl 3 "Unknown" 2 "Low" 1 "Middle" 0 "High" ;
VAL_ 2566853159 VDCU_TotMilg 65535 "Invalid" ;
VAL_ 2566853415 VDCU_LgtdCtrlAvlSt 3 "L3 Available Degrade" 2 "L3 Available" 1 "L2 and Below Available" 0 "Not Available" ;
VAL_ 2566853415 VDCU_LgtdCtrlTqActvSt 1 "Active" 0 "Inactive" ;
VAL_ 2566853415 VDCU_LgtdCtrlOvrdSt 1 "Override" 0 "Not Override" ;
VAL_ 2365484270 VDCU_VehActSpdVld 1 "Valid" 0 "Invalid" ;
VAL_ 2365484270 VDCU_VehDrvgDir 3 "Unknown" 2 "Standstill" 1 "Reverse" 0 "Forward" ;
VAL_ 2365484270 VDCU_VehActSpd 65535 "Invalid" ;
VAL_ 2566844711 VDCU_BrkPdlSwt 3 "Not Available" 2 "Reserved" 1 "Depressed" 0 "Released" ;
VAL_ 2365522947 TCU_FrTrsmShiftSt 1 "Shifting" 0 "Shift Completed" ;
VAL_ 2365523203 TCU_ReTrsmShiftSt 1 "Shifting" 0 "Shift Completed" ;
VAL_ 2565865739 EBS_ASREngCtrlActv 3 "Not Available" 2 "Reserved" 1 "Active" 0 "Inactive" ;
VAL_ 2565865739 EBS_ASRBrkCtrlActv 3 "Not Available" 2 "Reserved" 1 "Active" 0 "Inactive" ;
VAL_ 2565865739 EBS_ABSActv 3 "Not Available" 2 "Reserved" 1 "Active" 0 "Inactive" ;
VAL_ 2565865739 EBS_BrkPdlSwt 3 "Not Available" 2 "Error" 1 "Pressed" 0 "Not Pressed" ;
VAL_ 2565865739 EBS_BrkPdlPosn 255 "Not Available" 254 "Error" ;
VAL_ 2565865739 EBS_ASROfrdSwt 3 "Not Available" 2 "Reserved" 1 "Switch Active" 0 "Switch Inactive" ;
VAL_ 2565865739 EBS_ABSFulyOprtnl 3 "Not Available" 2 "Reserved" 1 "Fully" 0 "Not Fully" ;
VAL_ 2565865739 EBS_ABSEBSAWL 3 "Take no action" 2 "Reserved" 1 "On" 0 "Off" ;
VAL_ 2565865739 EBS_ATCASRLamp 3 "Take no action" 2 "Reserved" 1 "On" 0 "Off" ;
VAL_ 2566831883 EBS_TwoFrAxleSpd 65535 "Not Available" 65534 "Not Available" 65533 "Not Available" 65532 "Not Available" 65531 "Not Available" 65530 "Not Available" 65529 "Not Available" 65528 "Not Available" 65527 "Not Available" 65526 "Not Available" 65525 "Not Available" 65524 "Not Available" 65523 "Not Available" 65522 "Not Available" 65521 "Not Available" 65520 "Not Available" 65519 "Not Available" 65518 "Not Available" 65517 "Not Available" 65516 "Not Available" 65515 "Not Available" 65514 "Not Available" 65513 "Not Available" 65512 "Not Available" 65511 "Not Available" 65510 "Not Available" 65509 "Not Available" 65508 "Not Available" 65507 "Not Available" 65506 "Not Available" 65505 "Not Available" 65504 "Not Available" 65503 "Not Available" 65502 "Not Available" 65501 "Not Available" 65500 "Not Available" 65499 "Not Available" 65498 "Not Available" 65497 "Not Available" 65496 "Not Available" 65495 "Not Available" 65494 "Not Available" 65493 "Not Available" 65492 "Not Available" 65491 "Not Available" 65490 "Not Available" 65489 "Not Available" 65488 "Not Available" 65487 "Not Available" 65486 "Not Available" 65485 "Not Available" 65484 "Not Available" 65483 "Not Available" 65482 "Not Available" 65481 "Not Available" 65480 "Not Available" 65479 "Not Available" 65478 "Not Available" 65477 "Not Available" 65476 "Not Available" 65475 "Not Available" 65474 "Not Available" 65473 "Not Available" 65472 "Not Available" 65471 "Not Available" 65470 "Not Available" 65469 "Not Available" 65468 "Not Available" 65467 "Not Available" 65466 "Not Available" 65465 "Not Available" 65464 "Not Available" 65463 "Not Available" 65462 "Not Available" 65461 "Not Available" 65460 "Not Available" 65459 "Not Available" 65458 "Not Available" 65457 "Not Available" 65456 "Not Available" 65455 "Not Available" 65454 "Not Available" 65453 "Not Available" 65452 "Not Available" 65451 "Not Available" 65450 "Not Available" 65449 "Not Available" 65448 "Not Available" 65447 "Not Available" 65446 "Not Available" 65445 "Not Available" 65444 "Not Available" 65443 "Not Available" 65442 "Not Available" 65441 "Not Available" 65440 "Not Available" 65439 "Not Available" 65438 "Not Available" 65437 "Not Available" 65436 "Not Available" 65435 "Not Available" 65434 "Not Available" 65433 "Not Available" 65432 "Not Available" 65431 "Not Available" 65430 "Not Available" 65429 "Not Available" 65428 "Not Available" 65427 "Not Available" 65426 "Not Available" 65425 "Not Available" 65424 "Not Available" 65423 "Not Available" 65422 "Not Available" 65421 "Not Available" 65420 "Not Available" 65419 "Not Available" 65418 "Not Available" 65417 "Not Available" 65416 "Not Available" 65415 "Not Available" 65414 "Not Available" 65413 "Not Available" 65412 "Not Available" 65411 "Not Available" 65410 "Not Available" 65409 "Not Available" 65408 "Not Available" 65407 "Not Available" 65406 "Not Available" 65405 "Not Available" 65404 "Not Available" 65403 "Not Available" 65402 "Not Available" 65401 "Not Available" 65400 "Not Available" 65399 "Not Available" 65398 "Not Available" 65397 "Not Available" 65396 "Not Available" 65395 "Not Available" 65394 "Not Available" 65393 "Not Available" 65392 "Not Available" 65391 "Not Available" 65390 "Not Available" 65389 "Not Available" 65388 "Not Available" 65387 "Not Available" 65386 "Not Available" 65385 "Not Available" 65384 "Not Available" 65383 "Not Available" 65382 "Not Available" 65381 "Not Available" 65380 "Not Available" 65379 "Not Available" 65378 "Not Available" 65377 "Not Available" 65376 "Not Available" 65375 "Not Available" 65374 "Not Available" 65373 "Not Available" 65372 "Not Available" 65371 "Not Available" 65370 "Not Available" 65369 "Not Available" 65368 "Not Available" 65367 "Not Available" 65366 "Not Available" 65365 "Not Available" 65364 "Not Available" 65363 "Not Available" 65362 "Not Available" 65361 "Not Available" 65360 "Not Available" 65359 "Not Available" 65358 "Not Available" 65357 "Not Available" 65356 "Not Available" 65355 "Not Available" 65354 "Not Available" 65353 "Not Available" 65352 "Not Available" 65351 "Not Available" 65350 "Not Available" 65349 "Not Available" 65348 "Not Available" 65347 "Not Available" 65346 "Not Available" 65345 "Not Available" 65344 "Not Available" 65343 "Not Available" 65342 "Not Available" 65341 "Not Available" 65340 "Not Available" 65339 "Not Available" 65338 "Not Available" 65337 "Not Available" 65336 "Not Available" 65335 "Not Available" 65334 "Not Available" 65333 "Not Available" 65332 "Not Available" 65331 "Not Available" 65330 "Not Available" 65329 "Not Available" 65328 "Not Available" 65327 "Not Available" 65326 "Not Available" 65325 "Not Available" 65324 "Not Available" 65323 "Not Available" 65322 "Not Available" 65321 "Not Available" 65320 "Not Available" 65319 "Not Available" 65318 "Not Available" 65317 "Not Available" 65316 "Not Available" 65315 "Not Available" 65314 "Not Available" 65313 "Not Available" 65312 "Not Available" 65311 "Not Available" 65310 "Not Available" 65309 "Not Available" 65308 "Not Available" 65307 "Not Available" 65306 "Not Available" 65305 "Not Available" 65304 "Not Available" 65303 "Not Available" 65302 "Not Available" 65301 "Not Available" 65300 "Not Available" 65299 "Not Available" 65298 "Not Available" 65297 "Not Available" 65296 "Not Available" 65295 "Not Available" 65294 "Not Available" 65293 "Not Available" 65292 "Not Available" 65291 "Not Available" 65290 "Not Available" 65289 "Not Available" 65288 "Not Available" 65287 "Not Available" 65286 "Not Available" 65285 "Not Available" 65284 "Not Available" 65283 "Not Available" 65282 "Not Available" 65281 "Not Available" 65280 "Not Available" 65279 "Not Available" 65024 "Error" 65023 "Invalid" 65022 "Invalid" 65021 "Invalid" 65020 "Invalid" 65019 "Invalid" 65018 "Invalid" 65017 "Invalid" 65016 "Invalid" 65015 "Invalid" 65014 "Invalid" 65013 "Invalid" 65012 "Invalid" 65011 "Invalid" 65010 "Invalid" 65009 "Invalid" 65008 "Invalid" 65007 "Invalid" 65006 "Invalid" 65005 "Invalid" 65004 "Invalid" 65003 "Invalid" 65002 "Invalid" 65001 "Invalid" 65000 "Invalid" 64999 "Invalid" 64998 "Invalid" 64997 "Invalid" 64996 "Invalid" 64995 "Invalid" 64994 "Invalid" 64993 "Invalid" 64992 "Invalid" 64991 "Invalid" 64990 "Invalid" 64989 "Invalid" 64988 "Invalid" 64987 "Invalid" 64986 "Invalid" 64985 "Invalid" 64984 "Invalid" 64983 "Invalid" 64982 "Invalid" 64981 "Invalid" 64980 "Invalid" 64979 "Invalid" 64978 "Invalid" 64977 "Invalid" 64976 "Invalid" 64975 "Invalid" 64974 "Invalid" 64973 "Invalid" 64972 "Invalid" 64971 "Invalid" 64970 "Invalid" 64969 "Invalid" 64968 "Invalid" 64967 "Invalid" 64966 "Invalid" 64965 "Invalid" 64964 "Invalid" 64963 "Invalid" 64962 "Invalid" 64961 "Invalid" 64960 "Invalid" 64959 "Invalid" 64958 "Invalid" 64957 "Invalid" 64956 "Invalid" 64955 "Invalid" 64954 "Invalid" 64953 "Invalid" 64952 "Invalid" 64951 "Invalid" 64950 "Invalid" 64949 "Invalid" 64948 "Invalid" 64947 "Invalid" 64946 "Invalid" 64945 "Invalid" 64944 "Invalid" 64943 "Invalid" 64942 "Invalid" 64941 "Invalid" 64940 "Invalid" 64939 "Invalid" 64938 "Invalid" 64937 "Invalid" 64936 "Invalid" 64935 "Invalid" 64934 "Invalid" 64933 "Invalid" 64932 "Invalid" 64931 "Invalid" 64930 "Invalid" 64929 "Invalid" 64928 "Invalid" 64927 "Invalid" 64926 "Invalid" 64925 "Invalid" 64924 "Invalid" 64923 "Invalid" 64922 "Invalid" 64921 "Invalid" 64920 "Invalid" 64919 "Invalid" 64918 "Invalid" 64917 "Invalid" 64916 "Invalid" 64915 "Invalid" 64914 "Invalid" 64913 "Invalid" 64912 "Invalid" 64911 "Invalid" 64910 "Invalid" 64909 "Invalid" 64908 "Invalid" 64907 "Invalid" 64906 "Invalid" 64905 "Invalid" 64904 "Invalid" 64903 "Invalid" 64902 "Invalid" 64901 "Invalid" 64900 "Invalid" 64899 "Invalid" 64898 "Invalid" 64897 "Invalid" 64896 "Invalid" 64895 "Invalid" 64894 "Invalid" 64893 "Invalid" 64892 "Invalid" 64891 "Invalid" 64890 "Invalid" 64889 "Invalid" 64888 "Invalid" 64887 "Invalid" 64886 "Invalid" 64885 "Invalid" 64884 "Invalid" 64883 "Invalid" 64882 "Invalid" 64881 "Invalid" 64880 "Invalid" 64879 "Invalid" 64878 "Invalid" 64877 "Invalid" 64876 "Invalid" 64875 "Invalid" 64874 "Invalid" 64873 "Invalid" 64872 "Invalid" 64871 "Invalid" 64870 "Invalid" 64869 "Invalid" 64868 "Invalid" 64867 "Invalid" 64866 "Invalid" 64865 "Invalid" 64864 "Invalid" 64863 "Invalid" 64862 "Invalid" 64861 "Invalid" 64860 "Invalid" 64859 "Invalid" 64858 "Invalid" 64857 "Invalid" 64856 "Invalid" 64855 "Invalid" 64854 "Invalid" 64853 "Invalid" 64852 "Invalid" 64851 "Invalid" 64850 "Invalid" 64849 "Invalid" 64848 "Invalid" 64847 "Invalid" 64846 "Invalid" 64845 "Invalid" 64844 "Invalid" 64843 "Invalid" 64842 "Invalid" 64841 "Invalid" 64840 "Invalid" 64839 "Invalid" 64838 "Invalid" 64837 "Invalid" 64836 "Invalid" 64835 "Invalid" 64834 "Invalid" 64833 "Invalid" 64832 "Invalid" 64831 "Invalid" 64830 "Invalid" 64829 "Invalid" 64828 "Invalid" 64827 "Invalid" 64826 "Invalid" 64825 "Invalid" 64824 "Invalid" 64823 "Invalid" 64822 "Invalid" 64821 "Invalid" 64820 "Invalid" 64819 "Invalid" 64818 "Invalid" 64817 "Invalid" 64816 "Invalid" 64815 "Invalid" 64814 "Invalid" 64813 "Invalid" 64812 "Invalid" 64811 "Invalid" 64810 "Invalid" 64809 "Invalid" 64808 "Invalid" 64807 "Invalid" 64806 "Invalid" 64805 "Invalid" 64804 "Invalid" 64803 "Invalid" 64802 "Invalid" 64801 "Invalid" 64800 "Invalid" 64799 "Invalid" 64798 "Invalid" 64797 "Invalid" 64796 "Invalid" 64795 "Invalid" 64794 "Invalid" 64793 "Invalid" 64792 "Invalid" 64791 "Invalid" 64790 "Invalid" 64789 "Invalid" 64788 "Invalid" 64787 "Invalid" 64786 "Invalid" 64785 "Invalid" 64784 "Invalid" 64783 "Invalid" 64782 "Invalid" 64781 "Invalid" 64780 "Invalid" 64779 "Invalid" 64778 "Invalid" 64777 "Invalid" 64776 "Invalid" 64775 "Invalid" 64774 "Invalid" 64773 "Invalid" 64772 "Invalid" 64771 "Invalid" 64770 "Invalid" 64769 "Invalid" 64768 "Invalid" 64767 "Invalid" 64766 "Invalid" 64765 "Invalid" 64764 "Invalid" 64763 "Invalid" 64762 "Invalid" 64761 "Invalid" 64760 "Invalid" 64759 "Invalid" 64758 "Invalid" 64757 "Invalid" 64756 "Invalid" 64755 "Invalid" 64754 "Invalid" 64753 "Invalid" 64752 "Invalid" 64751 "Invalid" 64750 "Invalid" 64749 "Invalid" 64748 "Invalid" 64747 "Invalid" 64746 "Invalid" 64745 "Invalid" 64744 "Invalid" 64743 "Invalid" 64742 "Invalid" 64741 "Invalid" 64740 "Invalid" 64739 "Invalid" 64738 "Invalid" 64737 "Invalid" 64736 "Invalid" 64735 "Invalid" 64734 "Invalid" 64733 "Invalid" 64732 "Invalid" 64731 "Invalid" 64730 "Invalid" 64729 "Invalid" 64728 "Invalid" 64727 "Invalid" 64726 "Invalid" 64725 "Invalid" 64724 "Invalid" 64723 "Invalid" 64722 "Invalid" 64721 "Invalid" 64720 "Invalid" 64719 "Invalid" 64718 "Invalid" 64717 "Invalid" 64716 "Invalid" 64715 "Invalid" 64714 "Invalid" 64713 "Invalid" 64712 "Invalid" 64711 "Invalid" 64710 "Invalid" 64709 "Invalid" 64708 "Invalid" 64707 "Invalid" 64706 "Invalid" 64705 "Invalid" 64704 "Invalid" 64703 "Invalid" 64702 "Invalid" 64701 "Invalid" 64700 "Invalid" 64699 "Invalid" 64698 "Invalid" 64697 "Invalid" 64696 "Invalid" 64695 "Invalid" 64694 "Invalid" 64693 "Invalid" 64692 "Invalid" 64691 "Invalid" 64690 "Invalid" 64689 "Invalid" 64688 "Invalid" 64687 "Invalid" 64686 "Invalid" 64685 "Invalid" 64684 "Invalid" 64683 "Invalid" 64682 "Invalid" 64681 "Invalid" 64680 "Invalid" 64679 "Invalid" 64678 "Invalid" 64677 "Invalid" 64676 "Invalid" 64675 "Invalid" 64674 "Invalid" 64673 "Invalid" 64672 "Invalid" 64671 "Invalid" 64670 "Invalid" 64669 "Invalid" 64668 "Invalid" 64667 "Invalid" 64666 "Invalid" 64665 "Invalid" 64664 "Invalid" 64663 "Invalid" 64662 "Invalid" 64661 "Invalid" 64660 "Invalid" 64659 "Invalid" 64658 "Invalid" 64657 "Invalid" 64656 "Invalid" 64655 "Invalid" 64654 "Invalid" 64653 "Invalid" 64652 "Invalid" 64651 "Invalid" 64650 "Invalid" 64649 "Invalid" 64648 "Invalid" 64647 "Invalid" 64646 "Invalid" 64645 "Invalid" 64644 "Invalid" 64643 "Invalid" 64642 "Invalid" 64641 "Invalid" 64640 "Invalid" 64639 "Invalid" 64638 "Invalid" 64637 "Invalid" 64636 "Invalid" 64635 "Invalid" 64634 "Invalid" 64633 "Invalid" 64632 "Invalid" 64631 "Invalid" 64630 "Invalid" 64629 "Invalid" 64628 "Invalid" 64627 "Invalid" 64626 "Invalid" 64625 "Invalid" 64624 "Invalid" 64623 "Invalid" 64622 "Invalid" 64621 "Invalid" 64620 "Invalid" 64619 "Invalid" 64618 "Invalid" 64617 "Invalid" 64616 "Invalid" 64615 "Invalid" 64614 "Invalid" 64613 "Invalid" 64612 "Invalid" 64611 "Invalid" 64610 "Invalid" 64609 "Invalid" 64608 "Invalid" 64607 "Invalid" 64606 "Invalid" 64605 "Invalid" 64604 "Invalid" 64603 "Invalid" 64602 "Invalid" 64601 "Invalid" 64600 "Invalid" 64599 "Invalid" 64598 "Invalid" 64597 "Invalid" 64596 "Invalid" 64595 "Invalid" 64594 "Invalid" 64593 "Invalid" 64592 "Invalid" 64591 "Invalid" 64590 "Invalid" 64589 "Invalid" 64588 "Invalid" 64587 "Invalid" 64586 "Invalid" 64585 "Invalid" 64584 "Invalid" 64583 "Invalid" 64582 "Invalid" 64581 "Invalid" 64580 "Invalid" 64579 "Invalid" 64578 "Invalid" 64577 "Invalid" 64576 "Invalid" 64575 "Invalid" 64574 "Invalid" 64573 "Invalid" 64572 "Invalid" 64571 "Invalid" 64570 "Invalid" 64569 "Invalid" 64568 "Invalid" 64567 "Invalid" 64566 "Invalid" 64565 "Invalid" 64564 "Invalid" 64563 "Invalid" 64562 "Invalid" 64561 "Invalid" 64560 "Invalid" 64559 "Invalid" 64558 "Invalid" 64557 "Invalid" 64556 "Invalid" 64555 "Invalid" 64554 "Invalid" 64553 "Invalid" 64552 "Invalid" 64551 "Invalid" 64550 "Invalid" 64549 "Invalid" 64548 "Invalid" 64547 "Invalid" 64546 "Invalid" 64545 "Invalid" 64544 "Invalid" 64543 "Invalid" 64542 "Invalid" 64541 "Invalid" 64540 "Invalid" 64539 "Invalid" 64538 "Invalid" 64537 "Invalid" 64536 "Invalid" 64535 "Invalid" 64534 "Invalid" 64533 "Invalid" 64532 "Invalid" 64531 "Invalid" 64530 "Invalid" 64529 "Invalid" 64528 "Invalid" 64527 "Invalid" 64526 "Invalid" 64525 "Invalid" 64524 "Invalid" 64523 "Invalid" 64522 "Invalid" 64521 "Invalid" 64520 "Invalid" 64519 "Invalid" 64518 "Invalid" 64517 "Invalid" 64516 "Invalid" 64515 "Invalid" 64514 "Invalid" 64513 "Invalid" 64512 "Invalid" 64511 "Invalid" 64510 "Invalid" 64509 "Invalid" 64508 "Invalid" 64507 "Invalid" 64506 "Invalid" 64505 "Invalid" 64504 "Invalid" 64503 "Invalid" 64502 "Invalid" 64501 "Invalid" 64500 "Invalid" 64499 "Invalid" 64498 "Invalid" 64497 "Invalid" 64496 "Invalid" 64495 "Invalid" 64494 "Invalid" 64493 "Invalid" 64492 "Invalid" 64491 "Invalid" 64490 "Invalid" 64489 "Invalid" 64488 "Invalid" 64487 "Invalid" 64486 "Invalid" 64485 "Invalid" 64484 "Invalid" 64483 "Invalid" 64482 "Invalid" 64481 "Invalid" 64480 "Invalid" 64479 "Invalid" 64478 "Invalid" 64477 "Invalid" 64476 "Invalid" 64475 "Invalid" 64474 "Invalid" 64473 "Invalid" 64472 "Invalid" 64471 "Invalid" 64470 "Invalid" 64469 "Invalid" 64468 "Invalid" 64467 "Invalid" 64466 "Invalid" 64465 "Invalid" 64464 "Invalid" 64463 "Invalid" 64462 "Invalid" 64461 "Invalid" 64460 "Invalid" 64459 "Invalid" 64458 "Invalid" 64457 "Invalid" 64456 "Invalid" 64455 "Invalid" 64454 "Invalid" 64453 "Invalid" 64452 "Invalid" 64451 "Invalid" 64450 "Invalid" 64449 "Invalid" 64448 "Invalid" 64447 "Invalid" 64446 "Invalid" 64445 "Invalid" 64444 "Invalid" 64443 "Invalid" 64442 "Invalid" 64441 "Invalid" 64440 "Invalid" 64439 "Invalid" 64438 "Invalid" 64437 "Invalid" 64436 "Invalid" 64435 "Invalid" 64434 "Invalid" 64433 "Invalid" 64432 "Invalid" 64431 "Invalid" 64430 "Invalid" 64429 "Invalid" 64428 "Invalid" 64427 "Invalid" 64426 "Invalid" 64425 "Invalid" 64424 "Invalid" 64423 "Invalid" 64422 "Invalid" 64421 "Invalid" 64420 "Invalid" 64419 "Invalid" 64418 "Invalid" 64417 "Invalid" 64416 "Invalid" 64415 "Invalid" 64414 "Invalid" 64413 "Invalid" 64412 "Invalid" 64411 "Invalid" 64410 "Invalid" 64409 "Invalid" 64408 "Invalid" 64407 "Invalid" 64406 "Invalid" 64405 "Invalid" 64404 "Invalid" 64403 "Invalid" 64402 "Invalid" 64401 "Invalid" 64400 "Invalid" 64399 "Invalid" 64398 "Invalid" 64397 "Invalid" 64396 "Invalid" 64395 "Invalid" 64394 "Invalid" 64393 "Invalid" 64392 "Invalid" 64391 "Invalid" 64390 "Invalid" 64389 "Invalid" 64388 "Invalid" 64387 "Invalid" 64386 "Invalid" 64385 "Invalid" 64384 "Invalid" 64383 "Invalid" 64382 "Invalid" 64381 "Invalid" 64380 "Invalid" 64379 "Invalid" 64378 "Invalid" 64377 "Invalid" 64376 "Invalid" 64375 "Invalid" 64374 "Invalid" 64373 "Invalid" 64372 "Invalid" 64371 "Invalid" 64370 "Invalid" 64369 "Invalid" 64368 "Invalid" 64367 "Invalid" 64366 "Invalid" 64365 "Invalid" 64364 "Invalid" 64363 "Invalid" 64362 "Invalid" 64361 "Invalid" 64360 "Invalid" 64359 "Invalid" 64358 "Invalid" 64357 "Invalid" 64356 "Invalid" 64355 "Invalid" 64354 "Invalid" 64353 "Invalid" 64352 "Invalid" 64351 "Invalid" 64350 "Invalid" 64349 "Invalid" 64348 "Invalid" 64347 "Invalid" 64346 "Invalid" 64345 "Invalid" 64344 "Invalid" 64343 "Invalid" 64342 "Invalid" 64341 "Invalid" 64340 "Invalid" 64339 "Invalid" 64338 "Invalid" 64337 "Invalid" 64336 "Invalid" 64335 "Invalid" 64334 "Invalid" 64333 "Invalid" 64332 "Invalid" 64331 "Invalid" 64330 "Invalid" 64329 "Invalid" 64328 "Invalid" 64327 "Invalid" 64326 "Invalid" 64325 "Invalid" 64324 "Invalid" 64323 "Invalid" 64322 "Invalid" 64321 "Invalid" 64320 "Invalid" 64319 "Invalid" 64318 "Invalid" 64317 "Invalid" 64316 "Invalid" 64315 "Invalid" 64314 "Invalid" 64313 "Invalid" 64312 "Invalid" 64311 "Invalid" 64310 "Invalid" 64309 "Invalid" 64308 "Invalid" 64307 "Invalid" 64306 "Invalid" 64305 "Invalid" 64304 "Invalid" 64303 "Invalid" 64302 "Invalid" 64301 "Invalid" 64300 "Invalid" 64299 "Invalid" 64298 "Invalid" 64297 "Invalid" 64296 "Invalid" 64295 "Invalid" 64294 "Invalid" 64293 "Invalid" 64292 "Invalid" 64291 "Invalid" 64290 "Invalid" 64289 "Invalid" 64288 "Invalid" 64287 "Invalid" 64286 "Invalid" 64285 "Invalid" 64284 "Invalid" 64283 "Invalid" 64282 "Invalid" 64281 "Invalid" 64280 "Invalid" 64279 "Invalid" 64278 "Invalid" 64277 "Invalid" 64276 "Invalid" 64275 "Invalid" 64274 "Invalid" 64273 "Invalid" 64272 "Invalid" 64271 "Invalid" 64270 "Invalid" 64269 "Invalid" 64268 "Invalid" 64267 "Invalid" 64266 "Invalid" 64265 "Invalid" 64264 "Invalid" 64263 "Invalid" 64262 "Invalid" 64261 "Invalid" 64260 "Invalid" 64259 "Invalid" 64258 "Invalid" 64257 "Invalid" 64256 "Invalid" ;
VAL_ 2566767627 EBS_HaltBrkMod 7 "Not Available" 6 "Halt Brake Not Functional" 5 "Reserved" 4 "Reserved" 3 "Reserved" 2 "Active But not Functioning Properly" 1 "Active" 0 "Inactive" ;
VAL_ 2566767627 EBS_XBRSysSt 3 "Not Available" 2 "No external brake demand will be accepted" 1 "Only external brake demand of highest XBR Priority (0x0) will be accepted" 0 "Any external brake demand will be accepted" ;
VAL_ 2566767627 EBS_XBRActvCtrlMod 15 "Not Available" 14 "Reserved" 13 "Reserved" 12 "Reserved" 11 "Reserved" 10 "Reserved" 9 "Reserved" 8 "Reserved" 7 "Reserved" 6 "Reserved" 5 "Reserved" 4 "Reserved" 3 "Maximum Node Of XBR Acceleration Control Being Executed  XBR" 2 "Addition Mode Of XBR Acceleration Control Being Executed  XBR" 1 "Driver's brake demand being executed, no external brake demand" 0 "No Brake Demand Being Executed" ;
VAL_ 2566767627 EBS_EmgyBrkgActv 3 "Not Available" 2 "Reserved" 1 "Active" 0 "Inactive" ;
VAL_ 2566803211 EBS_VDCLamp 3 "Take No Action" 2 "Reserved" 1 "On" 0 "Off" ;
VAL_ 2566803211 EBS_VDCFulyOprtnl 3 "Take No Action" 2 "Reserved" 1 "Fully Operational" 0 "Not Fully Operational" ;
VAL_ 2566803211 EBS_ROPEngCtrlActv 3 "Take No Action" 2 "Reserved" 1 "ROP Engine Control Active" 0 "ROP Engine Control Passive But Installed" ;
VAL_ 2566803211 EBS_ROPBrkCtrlActv 3 "Take No Action" 2 "Reserved" 1 "ROP Brake Control Active" 0 "ROP Brake Control Passive But Installed" ;
VAL_ 2566803211 EBS_YCEngCtrlActv 3 "Take No Action" 2 "Reserved" 1 "YC Engine Control Active" 0 "YC Engine Control Passive But Installed" ;
VAL_ 2566803211 EBS_YCBrkCtrlActv 3 "Take No Action" 2 "Reserved" 1 "YC Brake Control Active" 0 "YC Brake Control Passive But Installed" ;
VAL_ 2565867787 EBS_SteerAng 65535 "Not Available" 65534 "Not Available" 65533 "Not Available" 65532 "Not Available" 65531 "Not Available" 65530 "Not Available" 65529 "Not Available" 65528 "Not Available" 65527 "Not Available" 65526 "Not Available" 65525 "Not Available" 65524 "Not Available" 65523 "Not Available" 65522 "Not Available" 65521 "Not Available" 65520 "Not Available" 65519 "Not Available" 65518 "Not Available" 65517 "Not Available" 65516 "Not Available" 65515 "Not Available" 65514 "Not Available" 65513 "Not Available" 65512 "Not Available" 65511 "Not Available" 65510 "Not Available" 65509 "Not Available" 65508 "Not Available" 65507 "Not Available" 65506 "Not Available" 65505 "Not Available" 65504 "Not Available" 65503 "Not Available" 65502 "Not Available" 65501 "Not Available" 65500 "Not Available" 65499 "Not Available" 65498 "Not Available" 65497 "Not Available" 65496 "Not Available" 65495 "Not Available" 65494 "Not Available" 65493 "Not Available" 65492 "Not Available" 65491 "Not Available" 65490 "Not Available" 65489 "Not Available" 65488 "Not Available" 65487 "Not Available" 65486 "Not Available" 65485 "Not Available" 65484 "Not Available" 65483 "Not Available" 65482 "Not Available" 65481 "Not Available" 65480 "Not Available" 65479 "Not Available" 65478 "Not Available" 65477 "Not Available" 65476 "Not Available" 65475 "Not Available" 65474 "Not Available" 65473 "Not Available" 65472 "Not Available" 65471 "Not Available" 65470 "Not Available" 65469 "Not Available" 65468 "Not Available" 65467 "Not Available" 65466 "Not Available" 65465 "Not Available" 65464 "Not Available" 65463 "Not Available" 65462 "Not Available" 65461 "Not Available" 65460 "Not Available" 65459 "Not Available" 65458 "Not Available" 65457 "Not Available" 65456 "Not Available" 65455 "Not Available" 65454 "Not Available" 65453 "Not Available" 65452 "Not Available" 65451 "Not Available" 65450 "Not Available" 65449 "Not Available" 65448 "Not Available" 65447 "Not Available" 65446 "Not Available" 65445 "Not Available" 65444 "Not Available" 65443 "Not Available" 65442 "Not Available" 65441 "Not Available" 65440 "Not Available" 65439 "Not Available" 65438 "Not Available" 65437 "Not Available" 65436 "Not Available" 65435 "Not Available" 65434 "Not Available" 65433 "Not Available" 65432 "Not Available" 65431 "Not Available" 65430 "Not Available" 65429 "Not Available" 65428 "Not Available" 65427 "Not Available" 65426 "Not Available" 65425 "Not Available" 65424 "Not Available" 65423 "Not Available" 65422 "Not Available" 65421 "Not Available" 65420 "Not Available" 65419 "Not Available" 65418 "Not Available" 65417 "Not Available" 65416 "Not Available" 65415 "Not Available" 65414 "Not Available" 65413 "Not Available" 65412 "Not Available" 65411 "Not Available" 65410 "Not Available" 65409 "Not Available" 65408 "Not Available" 65407 "Not Available" 65406 "Not Available" 65405 "Not Available" 65404 "Not Available" 65403 "Not Available" 65402 "Not Available" 65401 "Not Available" 65400 "Not Available" 65399 "Not Available" 65398 "Not Available" 65397 "Not Available" 65396 "Not Available" 65395 "Not Available" 65394 "Not Available" 65393 "Not Available" 65392 "Not Available" 65391 "Not Available" 65390 "Not Available" 65389 "Not Available" 65388 "Not Available" 65387 "Not Available" 65386 "Not Available" 65385 "Not Available" 65384 "Not Available" 65383 "Not Available" 65382 "Not Available" 65381 "Not Available" 65380 "Not Available" 65379 "Not Available" 65378 "Not Available" 65377 "Not Available" 65376 "Not Available" 65375 "Not Available" 65374 "Not Available" 65373 "Not Available" 65372 "Not Available" 65371 "Not Available" 65370 "Not Available" 65369 "Not Available" 65368 "Not Available" 65367 "Not Available" 65366 "Not Available" 65365 "Not Available" 65364 "Not Available" 65363 "Not Available" 65362 "Not Available" 65361 "Not Available" 65360 "Not Available" 65359 "Not Available" 65358 "Not Available" 65357 "Not Available" 65356 "Not Available" 65355 "Not Available" 65354 "Not Available" 65353 "Not Available" 65352 "Not Available" 65351 "Not Available" 65350 "Not Available" 65349 "Not Available" 65348 "Not Available" 65347 "Not Available" 65346 "Not Available" 65345 "Not Available" 65344 "Not Available" 65343 "Not Available" 65342 "Not Available" 65341 "Not Available" 65340 "Not Available" 65339 "Not Available" 65338 "Not Available" 65337 "Not Available" 65336 "Not Available" 65335 "Not Available" 65334 "Not Available" 65333 "Not Available" 65332 "Not Available" 65331 "Not Available" 65330 "Not Available" 65329 "Not Available" 65328 "Not Available" 65327 "Not Available" 65326 "Not Available" 65325 "Not Available" 65324 "Not Available" 65323 "Not Available" 65322 "Not Available" 65321 "Not Available" 65320 "Not Available" 65319 "Not Available" 65318 "Not Available" 65317 "Not Available" 65316 "Not Available" 65315 "Not Available" 65314 "Not Available" 65313 "Not Available" 65312 "Not Available" 65311 "Not Available" 65310 "Not Available" 65309 "Not Available" 65308 "Not Available" 65307 "Not Available" 65306 "Not Available" 65305 "Not Available" 65304 "Not Available" 65303 "Not Available" 65302 "Not Available" 65301 "Not Available" 65300 "Not Available" 65299 "Not Available" 65298 "Not Available" 65297 "Not Available" 65296 "Not Available" 65295 "Not Available" 65294 "Not Available" 65293 "Not Available" 65292 "Not Available" 65291 "Not Available" 65290 "Not Available" 65289 "Not Available" 65288 "Not Available" 65287 "Not Available" 65286 "Not Available" 65285 "Not Available" 65284 "Not Available" 65283 "Not Available" 65282 "Not Available" 65281 "Not Available" 65280 "Not Available" 65279 "Error" 65278 "Error" 65277 "Error" 65276 "Error" 65275 "Error" 65274 "Error" 65273 "Error" 65272 "Error" 65271 "Error" 65270 "Error" 65269 "Error" 65268 "Error" 65267 "Error" 65266 "Error" 65265 "Error" 65264 "Error" 65263 "Error" 65262 "Error" 65261 "Error" 65260 "Error" 65259 "Error" 65258 "Error" 65257 "Error" 65256 "Error" 65255 "Error" 65254 "Error" 65253 "Error" 65252 "Error" 65251 "Error" 65250 "Error" 65249 "Error" 65248 "Error" 65247 "Error" 65246 "Error" 65245 "Error" 65244 "Error" 65243 "Error" 65242 "Error" 65241 "Error" 65240 "Error" 65239 "Error" 65238 "Error" 65237 "Error" 65236 "Error" 65235 "Error" 65234 "Error" 65233 "Error" 65232 "Error" 65231 "Error" 65230 "Error" 65229 "Error" 65228 "Error" 65227 "Error" 65226 "Error" 65225 "Error" 65224 "Error" 65223 "Error" 65222 "Error" 65221 "Error" 65220 "Error" 65219 "Error" 65218 "Error" 65217 "Error" 65216 "Error" 65215 "Error" 65214 "Error" 65213 "Error" 65212 "Error" 65211 "Error" 65210 "Error" 65209 "Error" 65208 "Error" 65207 "Error" 65206 "Error" 65205 "Error" 65204 "Error" 65203 "Error" 65202 "Error" 65201 "Error" 65200 "Error" 65199 "Error" 65198 "Error" 65197 "Error" 65196 "Error" 65195 "Error" 65194 "Error" 65193 "Error" 65192 "Error" 65191 "Error" 65190 "Error" 65189 "Error" 65188 "Error" 65187 "Error" 65186 "Error" 65185 "Error" 65184 "Error" 65183 "Error" 65182 "Error" 65181 "Error" 65180 "Error" 65179 "Error" 65178 "Error" 65177 "Error" 65176 "Error" 65175 "Error" 65174 "Error" 65173 "Error" 65172 "Error" 65171 "Error" 65170 "Error" 65169 "Error" 65168 "Error" 65167 "Error" 65166 "Error" 65165 "Error" 65164 "Error" 65163 "Error" 65162 "Error" 65161 "Error" 65160 "Error" 65159 "Error" 65158 "Error" 65157 "Error" 65156 "Error" 65155 "Error" 65154 "Error" 65153 "Error" 65152 "Error" 65151 "Error" 65150 "Error" 65149 "Error" 65148 "Error" 65147 "Error" 65146 "Error" 65145 "Error" 65144 "Error" 65143 "Error" 65142 "Error" 65141 "Error" 65140 "Error" 65139 "Error" 65138 "Error" 65137 "Error" 65136 "Error" 65135 "Error" 65134 "Error" 65133 "Error" 65132 "Error" 65131 "Error" 65130 "Error" 65129 "Error" 65128 "Error" 65127 "Error" 65126 "Error" 65125 "Error" 65124 "Error" 65123 "Error" 65122 "Error" 65121 "Error" 65120 "Error" 65119 "Error" 65118 "Error" 65117 "Error" 65116 "Error" 65115 "Error" 65114 "Error" 65113 "Error" 65112 "Error" 65111 "Error" 65110 "Error" 65109 "Error" 65108 "Error" 65107 "Error" 65106 "Error" 65105 "Error" 65104 "Error" 65103 "Error" 65102 "Error" 65101 "Error" 65100 "Error" 65099 "Error" 65098 "Error" 65097 "Error" 65096 "Error" 65095 "Error" 65094 "Error" 65093 "Error" 65092 "Error" 65091 "Error" 65090 "Error" 65089 "Error" 65088 "Error" 65087 "Error" 65086 "Error" 65085 "Error" 65084 "Error" 65083 "Error" 65082 "Error" 65081 "Error" 65080 "Error" 65079 "Error" 65078 "Error" 65077 "Error" 65076 "Error" 65075 "Error" 65074 "Error" 65073 "Error" 65072 "Error" 65071 "Error" 65070 "Error" 65069 "Error" 65068 "Error" 65067 "Error" 65066 "Error" 65065 "Error" 65064 "Error" 65063 "Error" 65062 "Error" 65061 "Error" 65060 "Error" 65059 "Error" 65058 "Error" 65057 "Error" 65056 "Error" 65055 "Error" 65054 "Error" 65053 "Error" 65052 "Error" 65051 "Error" 65050 "Error" 65049 "Error" 65048 "Error" 65047 "Error" 65046 "Error" 65045 "Error" 65044 "Error" 65043 "Error" 65042 "Error" 65041 "Error" 65040 "Error" 65039 "Error" 65038 "Error" 65037 "Error" 65036 "Error" 65035 "Error" 65034 "Error" 65033 "Error" 65032 "Error" 65031 "Error" 65030 "Error" 65029 "Error" 65028 "Error" 65027 "Error" 65026 "Error" 65025 "Error" 65024 "Error" ;
VAL_ 2565867787 EBS_YawRate 65535 "Not Available" 65534 "Not Available" 65533 "Not Available" 65532 "Not Available" 65531 "Not Available" 65530 "Not Available" 65529 "Not Available" 65528 "Not Available" 65527 "Not Available" 65526 "Not Available" 65525 "Not Available" 65524 "Not Available" 65523 "Not Available" 65522 "Not Available" 65521 "Not Available" 65520 "Not Available" 65519 "Not Available" 65518 "Not Available" 65517 "Not Available" 65516 "Not Available" 65515 "Not Available" 65514 "Not Available" 65513 "Not Available" 65512 "Not Available" 65511 "Not Available" 65510 "Not Available" 65509 "Not Available" 65508 "Not Available" 65507 "Not Available" 65506 "Not Available" 65505 "Not Available" 65504 "Not Available" 65503 "Not Available" 65502 "Not Available" 65501 "Not Available" 65500 "Not Available" 65499 "Not Available" 65498 "Not Available" 65497 "Not Available" 65496 "Not Available" 65495 "Not Available" 65494 "Not Available" 65493 "Not Available" 65492 "Not Available" 65491 "Not Available" 65490 "Not Available" 65489 "Not Available" 65488 "Not Available" 65487 "Not Available" 65486 "Not Available" 65485 "Not Available" 65484 "Not Available" 65483 "Not Available" 65482 "Not Available" 65481 "Not Available" 65480 "Not Available" 65479 "Not Available" 65478 "Not Available" 65477 "Not Available" 65476 "Not Available" 65475 "Not Available" 65474 "Not Available" 65473 "Not Available" 65472 "Not Available" 65471 "Not Available" 65470 "Not Available" 65469 "Not Available" 65468 "Not Available" 65467 "Not Available" 65466 "Not Available" 65465 "Not Available" 65464 "Not Available" 65463 "Not Available" 65462 "Not Available" 65461 "Not Available" 65460 "Not Available" 65459 "Not Available" 65458 "Not Available" 65457 "Not Available" 65456 "Not Available" 65455 "Not Available" 65454 "Not Available" 65453 "Not Available" 65452 "Not Available" 65451 "Not Available" 65450 "Not Available" 65449 "Not Available" 65448 "Not Available" 65447 "Not Available" 65446 "Not Available" 65445 "Not Available" 65444 "Not Available" 65443 "Not Available" 65442 "Not Available" 65441 "Not Available" 65440 "Not Available" 65439 "Not Available" 65438 "Not Available" 65437 "Not Available" 65436 "Not Available" 65435 "Not Available" 65434 "Not Available" 65433 "Not Available" 65432 "Not Available" 65431 "Not Available" 65430 "Not Available" 65429 "Not Available" 65428 "Not Available" 65427 "Not Available" 65426 "Not Available" 65425 "Not Available" 65424 "Not Available" 65423 "Not Available" 65422 "Not Available" 65421 "Not Available" 65420 "Not Available" 65419 "Not Available" 65418 "Not Available" 65417 "Not Available" 65416 "Not Available" 65415 "Not Available" 65414 "Not Available" 65413 "Not Available" 65412 "Not Available" 65411 "Not Available" 65410 "Not Available" 65409 "Not Available" 65408 "Not Available" 65407 "Not Available" 65406 "Not Available" 65405 "Not Available" 65404 "Not Available" 65403 "Not Available" 65402 "Not Available" 65401 "Not Available" 65400 "Not Available" 65399 "Not Available" 65398 "Not Available" 65397 "Not Available" 65396 "Not Available" 65395 "Not Available" 65394 "Not Available" 65393 "Not Available" 65392 "Not Available" 65391 "Not Available" 65390 "Not Available" 65389 "Not Available" 65388 "Not Available" 65387 "Not Available" 65386 "Not Available" 65385 "Not Available" 65384 "Not Available" 65383 "Not Available" 65382 "Not Available" 65381 "Not Available" 65380 "Not Available" 65379 "Not Available" 65378 "Not Available" 65377 "Not Available" 65376 "Not Available" 65375 "Not Available" 65374 "Not Available" 65373 "Not Available" 65372 "Not Available" 65371 "Not Available" 65370 "Not Available" 65369 "Not Available" 65368 "Not Available" 65367 "Not Available" 65366 "Not Available" 65365 "Not Available" 65364 "Not Available" 65363 "Not Available" 65362 "Not Available" 65361 "Not Available" 65360 "Not Available" 65359 "Not Available" 65358 "Not Available" 65357 "Not Available" 65356 "Not Available" 65355 "Not Available" 65354 "Not Available" 65353 "Not Available" 65352 "Not Available" 65351 "Not Available" 65350 "Not Available" 65349 "Not Available" 65348 "Not Available" 65347 "Not Available" 65346 "Not Available" 65345 "Not Available" 65344 "Not Available" 65343 "Not Available" 65342 "Not Available" 65341 "Not Available" 65340 "Not Available" 65339 "Not Available" 65338 "Not Available" 65337 "Not Available" 65336 "Not Available" 65335 "Not Available" 65334 "Not Available" 65333 "Not Available" 65332 "Not Available" 65331 "Not Available" 65330 "Not Available" 65329 "Not Available" 65328 "Not Available" 65327 "Not Available" 65326 "Not Available" 65325 "Not Available" 65324 "Not Available" 65323 "Not Available" 65322 "Not Available" 65321 "Not Available" 65320 "Not Available" 65319 "Not Available" 65318 "Not Available" 65317 "Not Available" 65316 "Not Available" 65315 "Not Available" 65314 "Not Available" 65313 "Not Available" 65312 "Not Available" 65311 "Not Available" 65310 "Not Available" 65309 "Not Available" 65308 "Not Available" 65307 "Not Available" 65306 "Not Available" 65305 "Not Available" 65304 "Not Available" 65303 "Not Available" 65302 "Not Available" 65301 "Not Available" 65300 "Not Available" 65299 "Not Available" 65298 "Not Available" 65297 "Not Available" 65296 "Not Available" 65295 "Not Available" 65294 "Not Available" 65293 "Not Available" 65292 "Not Available" 65291 "Not Available" 65290 "Not Available" 65289 "Not Available" 65288 "Not Available" 65287 "Not Available" 65286 "Not Available" 65285 "Not Available" 65284 "Not Available" 65283 "Not Available" 65282 "Not Available" 65281 "Not Available" 65280 "Not Available" 65279 "Error" 65278 "Error" 65277 "Error" 65276 "Error" 65275 "Error" 65274 "Error" 65273 "Error" 65272 "Error" 65271 "Error" 65270 "Error" 65269 "Error" 65268 "Error" 65267 "Error" 65266 "Error" 65265 "Error" 65264 "Error" 65263 "Error" 65262 "Error" 65261 "Error" 65260 "Error" 65259 "Error" 65258 "Error" 65257 "Error" 65256 "Error" 65255 "Error" 65254 "Error" 65253 "Error" 65252 "Error" 65251 "Error" 65250 "Error" 65249 "Error" 65248 "Error" 65247 "Error" 65246 "Error" 65245 "Error" 65244 "Error" 65243 "Error" 65242 "Error" 65241 "Error" 65240 "Error" 65239 "Error" 65238 "Error" 65237 "Error" 65236 "Error" 65235 "Error" 65234 "Error" 65233 "Error" 65232 "Error" 65231 "Error" 65230 "Error" 65229 "Error" 65228 "Error" 65227 "Error" 65226 "Error" 65225 "Error" 65224 "Error" 65223 "Error" 65222 "Error" 65221 "Error" 65220 "Error" 65219 "Error" 65218 "Error" 65217 "Error" 65216 "Error" 65215 "Error" 65214 "Error" 65213 "Error" 65212 "Error" 65211 "Error" 65210 "Error" 65209 "Error" 65208 "Error" 65207 "Error" 65206 "Error" 65205 "Error" 65204 "Error" 65203 "Error" 65202 "Error" 65201 "Error" 65200 "Error" 65199 "Error" 65198 "Error" 65197 "Error" 65196 "Error" 65195 "Error" 65194 "Error" 65193 "Error" 65192 "Error" 65191 "Error" 65190 "Error" 65189 "Error" 65188 "Error" 65187 "Error" 65186 "Error" 65185 "Error" 65184 "Error" 65183 "Error" 65182 "Error" 65181 "Error" 65180 "Error" 65179 "Error" 65178 "Error" 65177 "Error" 65176 "Error" 65175 "Error" 65174 "Error" 65173 "Error" 65172 "Error" 65171 "Error" 65170 "Error" 65169 "Error" 65168 "Error" 65167 "Error" 65166 "Error" 65165 "Error" 65164 "Error" 65163 "Error" 65162 "Error" 65161 "Error" 65160 "Error" 65159 "Error" 65158 "Error" 65157 "Error" 65156 "Error" 65155 "Error" 65154 "Error" 65153 "Error" 65152 "Error" 65151 "Error" 65150 "Error" 65149 "Error" 65148 "Error" 65147 "Error" 65146 "Error" 65145 "Error" 65144 "Error" 65143 "Error" 65142 "Error" 65141 "Error" 65140 "Error" 65139 "Error" 65138 "Error" 65137 "Error" 65136 "Error" 65135 "Error" 65134 "Error" 65133 "Error" 65132 "Error" 65131 "Error" 65130 "Error" 65129 "Error" 65128 "Error" 65127 "Error" 65126 "Error" 65125 "Error" 65124 "Error" 65123 "Error" 65122 "Error" 65121 "Error" 65120 "Error" 65119 "Error" 65118 "Error" 65117 "Error" 65116 "Error" 65115 "Error" 65114 "Error" 65113 "Error" 65112 "Error" 65111 "Error" 65110 "Error" 65109 "Error" 65108 "Error" 65107 "Error" 65106 "Error" 65105 "Error" 65104 "Error" 65103 "Error" 65102 "Error" 65101 "Error" 65100 "Error" 65099 "Error" 65098 "Error" 65097 "Error" 65096 "Error" 65095 "Error" 65094 "Error" 65093 "Error" 65092 "Error" 65091 "Error" 65090 "Error" 65089 "Error" 65088 "Error" 65087 "Error" 65086 "Error" 65085 "Error" 65084 "Error" 65083 "Error" 65082 "Error" 65081 "Error" 65080 "Error" 65079 "Error" 65078 "Error" 65077 "Error" 65076 "Error" 65075 "Error" 65074 "Error" 65073 "Error" 65072 "Error" 65071 "Error" 65070 "Error" 65069 "Error" 65068 "Error" 65067 "Error" 65066 "Error" 65065 "Error" 65064 "Error" 65063 "Error" 65062 "Error" 65061 "Error" 65060 "Error" 65059 "Error" 65058 "Error" 65057 "Error" 65056 "Error" 65055 "Error" 65054 "Error" 65053 "Error" 65052 "Error" 65051 "Error" 65050 "Error" 65049 "Error" 65048 "Error" 65047 "Error" 65046 "Error" 65045 "Error" 65044 "Error" 65043 "Error" 65042 "Error" 65041 "Error" 65040 "Error" 65039 "Error" 65038 "Error" 65037 "Error" 65036 "Error" 65035 "Error" 65034 "Error" 65033 "Error" 65032 "Error" 65031 "Error" 65030 "Error" 65029 "Error" 65028 "Error" 65027 "Error" 65026 "Error" 65025 "Error" 65024 "Error" ;
VAL_ 2565867787 EBS_LatAccl 65535 "Not Available" 65534 "Not Available" 65533 "Not Available" 65532 "Not Available" 65531 "Not Available" 65530 "Not Available" 65529 "Not Available" 65528 "Not Available" 65527 "Not Available" 65526 "Not Available" 65525 "Not Available" 65524 "Not Available" 65523 "Not Available" 65522 "Not Available" 65521 "Not Available" 65520 "Not Available" 65519 "Not Available" 65518 "Not Available" 65517 "Not Available" 65516 "Not Available" 65515 "Not Available" 65514 "Not Available" 65513 "Not Available" 65512 "Not Available" 65511 "Not Available" 65510 "Not Available" 65509 "Not Available" 65508 "Not Available" 65507 "Not Available" 65506 "Not Available" 65505 "Not Available" 65504 "Not Available" 65503 "Not Available" 65502 "Not Available" 65501 "Not Available" 65500 "Not Available" 65499 "Not Available" 65498 "Not Available" 65497 "Not Available" 65496 "Not Available" 65495 "Not Available" 65494 "Not Available" 65493 "Not Available" 65492 "Not Available" 65491 "Not Available" 65490 "Not Available" 65489 "Not Available" 65488 "Not Available" 65487 "Not Available" 65486 "Not Available" 65485 "Not Available" 65484 "Not Available" 65483 "Not Available" 65482 "Not Available" 65481 "Not Available" 65480 "Not Available" 65479 "Not Available" 65478 "Not Available" 65477 "Not Available" 65476 "Not Available" 65475 "Not Available" 65474 "Not Available" 65473 "Not Available" 65472 "Not Available" 65471 "Not Available" 65470 "Not Available" 65469 "Not Available" 65468 "Not Available" 65467 "Not Available" 65466 "Not Available" 65465 "Not Available" 65464 "Not Available" 65463 "Not Available" 65462 "Not Available" 65461 "Not Available" 65460 "Not Available" 65459 "Not Available" 65458 "Not Available" 65457 "Not Available" 65456 "Not Available" 65455 "Not Available" 65454 "Not Available" 65453 "Not Available" 65452 "Not Available" 65451 "Not Available" 65450 "Not Available" 65449 "Not Available" 65448 "Not Available" 65447 "Not Available" 65446 "Not Available" 65445 "Not Available" 65444 "Not Available" 65443 "Not Available" 65442 "Not Available" 65441 "Not Available" 65440 "Not Available" 65439 "Not Available" 65438 "Not Available" 65437 "Not Available" 65436 "Not Available" 65435 "Not Available" 65434 "Not Available" 65433 "Not Available" 65432 "Not Available" 65431 "Not Available" 65430 "Not Available" 65429 "Not Available" 65428 "Not Available" 65427 "Not Available" 65426 "Not Available" 65425 "Not Available" 65424 "Not Available" 65423 "Not Available" 65422 "Not Available" 65421 "Not Available" 65420 "Not Available" 65419 "Not Available" 65418 "Not Available" 65417 "Not Available" 65416 "Not Available" 65415 "Not Available" 65414 "Not Available" 65413 "Not Available" 65412 "Not Available" 65411 "Not Available" 65410 "Not Available" 65409 "Not Available" 65408 "Not Available" 65407 "Not Available" 65406 "Not Available" 65405 "Not Available" 65404 "Not Available" 65403 "Not Available" 65402 "Not Available" 65401 "Not Available" 65400 "Not Available" 65399 "Not Available" 65398 "Not Available" 65397 "Not Available" 65396 "Not Available" 65395 "Not Available" 65394 "Not Available" 65393 "Not Available" 65392 "Not Available" 65391 "Not Available" 65390 "Not Available" 65389 "Not Available" 65388 "Not Available" 65387 "Not Available" 65386 "Not Available" 65385 "Not Available" 65384 "Not Available" 65383 "Not Available" 65382 "Not Available" 65381 "Not Available" 65380 "Not Available" 65379 "Not Available" 65378 "Not Available" 65377 "Not Available" 65376 "Not Available" 65375 "Not Available" 65374 "Not Available" 65373 "Not Available" 65372 "Not Available" 65371 "Not Available" 65370 "Not Available" 65369 "Not Available" 65368 "Not Available" 65367 "Not Available" 65366 "Not Available" 65365 "Not Available" 65364 "Not Available" 65363 "Not Available" 65362 "Not Available" 65361 "Not Available" 65360 "Not Available" 65359 "Not Available" 65358 "Not Available" 65357 "Not Available" 65356 "Not Available" 65355 "Not Available" 65354 "Not Available" 65353 "Not Available" 65352 "Not Available" 65351 "Not Available" 65350 "Not Available" 65349 "Not Available" 65348 "Not Available" 65347 "Not Available" 65346 "Not Available" 65345 "Not Available" 65344 "Not Available" 65343 "Not Available" 65342 "Not Available" 65341 "Not Available" 65340 "Not Available" 65339 "Not Available" 65338 "Not Available" 65337 "Not Available" 65336 "Not Available" 65335 "Not Available" 65334 "Not Available" 65333 "Not Available" 65332 "Not Available" 65331 "Not Available" 65330 "Not Available" 65329 "Not Available" 65328 "Not Available" 65327 "Not Available" 65326 "Not Available" 65325 "Not Available" 65324 "Not Available" 65323 "Not Available" 65322 "Not Available" 65321 "Not Available" 65320 "Not Available" 65319 "Not Available" 65318 "Not Available" 65317 "Not Available" 65316 "Not Available" 65315 "Not Available" 65314 "Not Available" 65313 "Not Available" 65312 "Not Available" 65311 "Not Available" 65310 "Not Available" 65309 "Not Available" 65308 "Not Available" 65307 "Not Available" 65306 "Not Available" 65305 "Not Available" 65304 "Not Available" 65303 "Not Available" 65302 "Not Available" 65301 "Not Available" 65300 "Not Available" 65299 "Not Available" 65298 "Not Available" 65297 "Not Available" 65296 "Not Available" 65295 "Not Available" 65294 "Not Available" 65293 "Not Available" 65292 "Not Available" 65291 "Not Available" 65290 "Not Available" 65289 "Not Available" 65288 "Not Available" 65287 "Not Available" 65286 "Not Available" 65285 "Not Available" 65284 "Not Available" 65283 "Not Available" 65282 "Not Available" 65281 "Not Available" 65280 "Not Available" 65279 "Error" 65278 "Error" 65277 "Error" 65276 "Error" 65275 "Error" 65274 "Error" 65273 "Error" 65272 "Error" 65271 "Error" 65270 "Error" 65269 "Error" 65268 "Error" 65267 "Error" 65266 "Error" 65265 "Error" 65264 "Error" 65263 "Error" 65262 "Error" 65261 "Error" 65260 "Error" 65259 "Error" 65258 "Error" 65257 "Error" 65256 "Error" 65255 "Error" 65254 "Error" 65253 "Error" 65252 "Error" 65251 "Error" 65250 "Error" 65249 "Error" 65248 "Error" 65247 "Error" 65246 "Error" 65245 "Error" 65244 "Error" 65243 "Error" 65242 "Error" 65241 "Error" 65240 "Error" 65239 "Error" 65238 "Error" 65237 "Error" 65236 "Error" 65235 "Error" 65234 "Error" 65233 "Error" 65232 "Error" 65231 "Error" 65230 "Error" 65229 "Error" 65228 "Error" 65227 "Error" 65226 "Error" 65225 "Error" 65224 "Error" 65223 "Error" 65222 "Error" 65221 "Error" 65220 "Error" 65219 "Error" 65218 "Error" 65217 "Error" 65216 "Error" 65215 "Error" 65214 "Error" 65213 "Error" 65212 "Error" 65211 "Error" 65210 "Error" 65209 "Error" 65208 "Error" 65207 "Error" 65206 "Error" 65205 "Error" 65204 "Error" 65203 "Error" 65202 "Error" 65201 "Error" 65200 "Error" 65199 "Error" 65198 "Error" 65197 "Error" 65196 "Error" 65195 "Error" 65194 "Error" 65193 "Error" 65192 "Error" 65191 "Error" 65190 "Error" 65189 "Error" 65188 "Error" 65187 "Error" 65186 "Error" 65185 "Error" 65184 "Error" 65183 "Error" 65182 "Error" 65181 "Error" 65180 "Error" 65179 "Error" 65178 "Error" 65177 "Error" 65176 "Error" 65175 "Error" 65174 "Error" 65173 "Error" 65172 "Error" 65171 "Error" 65170 "Error" 65169 "Error" 65168 "Error" 65167 "Error" 65166 "Error" 65165 "Error" 65164 "Error" 65163 "Error" 65162 "Error" 65161 "Error" 65160 "Error" 65159 "Error" 65158 "Error" 65157 "Error" 65156 "Error" 65155 "Error" 65154 "Error" 65153 "Error" 65152 "Error" 65151 "Error" 65150 "Error" 65149 "Error" 65148 "Error" 65147 "Error" 65146 "Error" 65145 "Error" 65144 "Error" 65143 "Error" 65142 "Error" 65141 "Error" 65140 "Error" 65139 "Error" 65138 "Error" 65137 "Error" 65136 "Error" 65135 "Error" 65134 "Error" 65133 "Error" 65132 "Error" 65131 "Error" 65130 "Error" 65129 "Error" 65128 "Error" 65127 "Error" 65126 "Error" 65125 "Error" 65124 "Error" 65123 "Error" 65122 "Error" 65121 "Error" 65120 "Error" 65119 "Error" 65118 "Error" 65117 "Error" 65116 "Error" 65115 "Error" 65114 "Error" 65113 "Error" 65112 "Error" 65111 "Error" 65110 "Error" 65109 "Error" 65108 "Error" 65107 "Error" 65106 "Error" 65105 "Error" 65104 "Error" 65103 "Error" 65102 "Error" 65101 "Error" 65100 "Error" 65099 "Error" 65098 "Error" 65097 "Error" 65096 "Error" 65095 "Error" 65094 "Error" 65093 "Error" 65092 "Error" 65091 "Error" 65090 "Error" 65089 "Error" 65088 "Error" 65087 "Error" 65086 "Error" 65085 "Error" 65084 "Error" 65083 "Error" 65082 "Error" 65081 "Error" 65080 "Error" 65079 "Error" 65078 "Error" 65077 "Error" 65076 "Error" 65075 "Error" 65074 "Error" 65073 "Error" 65072 "Error" 65071 "Error" 65070 "Error" 65069 "Error" 65068 "Error" 65067 "Error" 65066 "Error" 65065 "Error" 65064 "Error" 65063 "Error" 65062 "Error" 65061 "Error" 65060 "Error" 65059 "Error" 65058 "Error" 65057 "Error" 65056 "Error" 65055 "Error" 65054 "Error" 65053 "Error" 65052 "Error" 65051 "Error" 65050 "Error" 65049 "Error" 65048 "Error" 65047 "Error" 65046 "Error" 65045 "Error" 65044 "Error" 65043 "Error" 65042 "Error" 65041 "Error" 65040 "Error" 65039 "Error" 65038 "Error" 65037 "Error" 65036 "Error" 65035 "Error" 65034 "Error" 65033 "Error" 65032 "Error" 65031 "Error" 65030 "Error" 65029 "Error" 65028 "Error" 65027 "Error" 65026 "Error" 65025 "Error" 65024 "Error" ;
VAL_ 2565867787 EBS_LgtdAccl 255 "Not Available" 254 "Error" ;
VAL_ 2298375691 EBS_LFWhlSpd 65535 "Not Available" 65534 "Not Available" 65533 "Not Available" 65532 "Not Available" 65531 "Not Available" 65530 "Not Available" 65529 "Not Available" 65528 "Not Available" 65527 "Not Available" 65526 "Not Available" 65525 "Not Available" 65524 "Not Available" 65523 "Not Available" 65522 "Not Available" 65521 "Not Available" 65520 "Not Available" 65519 "Not Available" 65518 "Not Available" 65517 "Not Available" 65516 "Not Available" 65515 "Not Available" 65514 "Not Available" 65513 "Not Available" 65512 "Not Available" 65511 "Not Available" 65510 "Not Available" 65509 "Not Available" 65508 "Not Available" 65507 "Not Available" 65506 "Not Available" 65505 "Not Available" 65504 "Not Available" 65503 "Not Available" 65502 "Not Available" 65501 "Not Available" 65500 "Not Available" 65499 "Not Available" 65498 "Not Available" 65497 "Not Available" 65496 "Not Available" 65495 "Not Available" 65494 "Not Available" 65493 "Not Available" 65492 "Not Available" 65491 "Not Available" 65490 "Not Available" 65489 "Not Available" 65488 "Not Available" 65487 "Not Available" 65486 "Not Available" 65485 "Not Available" 65484 "Not Available" 65483 "Not Available" 65482 "Not Available" 65481 "Not Available" 65480 "Not Available" 65479 "Not Available" 65478 "Not Available" 65477 "Not Available" 65476 "Not Available" 65475 "Not Available" 65474 "Not Available" 65473 "Not Available" 65472 "Not Available" 65471 "Not Available" 65470 "Not Available" 65469 "Not Available" 65468 "Not Available" 65467 "Not Available" 65466 "Not Available" 65465 "Not Available" 65464 "Not Available" 65463 "Not Available" 65462 "Not Available" 65461 "Not Available" 65460 "Not Available" 65459 "Not Available" 65458 "Not Available" 65457 "Not Available" 65456 "Not Available" 65455 "Not Available" 65454 "Not Available" 65453 "Not Available" 65452 "Not Available" 65451 "Not Available" 65450 "Not Available" 65449 "Not Available" 65448 "Not Available" 65447 "Not Available" 65446 "Not Available" 65445 "Not Available" 65444 "Not Available" 65443 "Not Available" 65442 "Not Available" 65441 "Not Available" 65440 "Not Available" 65439 "Not Available" 65438 "Not Available" 65437 "Not Available" 65436 "Not Available" 65435 "Not Available" 65434 "Not Available" 65433 "Not Available" 65432 "Not Available" 65431 "Not Available" 65430 "Not Available" 65429 "Not Available" 65428 "Not Available" 65427 "Not Available" 65426 "Not Available" 65425 "Not Available" 65424 "Not Available" 65423 "Not Available" 65422 "Not Available" 65421 "Not Available" 65420 "Not Available" 65419 "Not Available" 65418 "Not Available" 65417 "Not Available" 65416 "Not Available" 65415 "Not Available" 65414 "Not Available" 65413 "Not Available" 65412 "Not Available" 65411 "Not Available" 65410 "Not Available" 65409 "Not Available" 65408 "Not Available" 65407 "Not Available" 65406 "Not Available" 65405 "Not Available" 65404 "Not Available" 65403 "Not Available" 65402 "Not Available" 65401 "Not Available" 65400 "Not Available" 65399 "Not Available" 65398 "Not Available" 65397 "Not Available" 65396 "Not Available" 65395 "Not Available" 65394 "Not Available" 65393 "Not Available" 65392 "Not Available" 65391 "Not Available" 65390 "Not Available" 65389 "Not Available" 65388 "Not Available" 65387 "Not Available" 65386 "Not Available" 65385 "Not Available" 65384 "Not Available" 65383 "Not Available" 65382 "Not Available" 65381 "Not Available" 65380 "Not Available" 65379 "Not Available" 65378 "Not Available" 65377 "Not Available" 65376 "Not Available" 65375 "Not Available" 65374 "Not Available" 65373 "Not Available" 65372 "Not Available" 65371 "Not Available" 65370 "Not Available" 65369 "Not Available" 65368 "Not Available" 65367 "Not Available" 65366 "Not Available" 65365 "Not Available" 65364 "Not Available" 65363 "Not Available" 65362 "Not Available" 65361 "Not Available" 65360 "Not Available" 65359 "Not Available" 65358 "Not Available" 65357 "Not Available" 65356 "Not Available" 65355 "Not Available" 65354 "Not Available" 65353 "Not Available" 65352 "Not Available" 65351 "Not Available" 65350 "Not Available" 65349 "Not Available" 65348 "Not Available" 65347 "Not Available" 65346 "Not Available" 65345 "Not Available" 65344 "Not Available" 65343 "Not Available" 65342 "Not Available" 65341 "Not Available" 65340 "Not Available" 65339 "Not Available" 65338 "Not Available" 65337 "Not Available" 65336 "Not Available" 65335 "Not Available" 65334 "Not Available" 65333 "Not Available" 65332 "Not Available" 65331 "Not Available" 65330 "Not Available" 65329 "Not Available" 65328 "Not Available" 65327 "Not Available" 65326 "Not Available" 65325 "Not Available" 65324 "Not Available" 65323 "Not Available" 65322 "Not Available" 65321 "Not Available" 65320 "Not Available" 65319 "Not Available" 65318 "Not Available" 65317 "Not Available" 65316 "Not Available" 65315 "Not Available" 65314 "Not Available" 65313 "Not Available" 65312 "Not Available" 65311 "Not Available" 65310 "Not Available" 65309 "Not Available" 65308 "Not Available" 65307 "Not Available" 65306 "Not Available" 65305 "Not Available" 65304 "Not Available" 65303 "Not Available" 65302 "Not Available" 65301 "Not Available" 65300 "Not Available" 65299 "Not Available" 65298 "Not Available" 65297 "Not Available" 65296 "Not Available" 65295 "Not Available" 65294 "Not Available" 65293 "Not Available" 65292 "Not Available" 65291 "Not Available" 65290 "Not Available" 65289 "Not Available" 65288 "Not Available" 65287 "Not Available" 65286 "Not Available" 65285 "Not Available" 65284 "Not Available" 65283 "Not Available" 65282 "Not Available" 65281 "Not Available" 65280 "Not Available" ;
VAL_ 2298375691 EBS_RFWhlSpd 65535 "Not Available" 65534 "Not Available" 65533 "Not Available" 65532 "Not Available" 65531 "Not Available" 65530 "Not Available" 65529 "Not Available" 65528 "Not Available" 65527 "Not Available" 65526 "Not Available" 65525 "Not Available" 65524 "Not Available" 65523 "Not Available" 65522 "Not Available" 65521 "Not Available" 65520 "Not Available" 65519 "Not Available" 65518 "Not Available" 65517 "Not Available" 65516 "Not Available" 65515 "Not Available" 65514 "Not Available" 65513 "Not Available" 65512 "Not Available" 65511 "Not Available" 65510 "Not Available" 65509 "Not Available" 65508 "Not Available" 65507 "Not Available" 65506 "Not Available" 65505 "Not Available" 65504 "Not Available" 65503 "Not Available" 65502 "Not Available" 65501 "Not Available" 65500 "Not Available" 65499 "Not Available" 65498 "Not Available" 65497 "Not Available" 65496 "Not Available" 65495 "Not Available" 65494 "Not Available" 65493 "Not Available" 65492 "Not Available" 65491 "Not Available" 65490 "Not Available" 65489 "Not Available" 65488 "Not Available" 65487 "Not Available" 65486 "Not Available" 65485 "Not Available" 65484 "Not Available" 65483 "Not Available" 65482 "Not Available" 65481 "Not Available" 65480 "Not Available" 65479 "Not Available" 65478 "Not Available" 65477 "Not Available" 65476 "Not Available" 65475 "Not Available" 65474 "Not Available" 65473 "Not Available" 65472 "Not Available" 65471 "Not Available" 65470 "Not Available" 65469 "Not Available" 65468 "Not Available" 65467 "Not Available" 65466 "Not Available" 65465 "Not Available" 65464 "Not Available" 65463 "Not Available" 65462 "Not Available" 65461 "Not Available" 65460 "Not Available" 65459 "Not Available" 65458 "Not Available" 65457 "Not Available" 65456 "Not Available" 65455 "Not Available" 65454 "Not Available" 65453 "Not Available" 65452 "Not Available" 65451 "Not Available" 65450 "Not Available" 65449 "Not Available" 65448 "Not Available" 65447 "Not Available" 65446 "Not Available" 65445 "Not Available" 65444 "Not Available" 65443 "Not Available" 65442 "Not Available" 65441 "Not Available" 65440 "Not Available" 65439 "Not Available" 65438 "Not Available" 65437 "Not Available" 65436 "Not Available" 65435 "Not Available" 65434 "Not Available" 65433 "Not Available" 65432 "Not Available" 65431 "Not Available" 65430 "Not Available" 65429 "Not Available" 65428 "Not Available" 65427 "Not Available" 65426 "Not Available" 65425 "Not Available" 65424 "Not Available" 65423 "Not Available" 65422 "Not Available" 65421 "Not Available" 65420 "Not Available" 65419 "Not Available" 65418 "Not Available" 65417 "Not Available" 65416 "Not Available" 65415 "Not Available" 65414 "Not Available" 65413 "Not Available" 65412 "Not Available" 65411 "Not Available" 65410 "Not Available" 65409 "Not Available" 65408 "Not Available" 65407 "Not Available" 65406 "Not Available" 65405 "Not Available" 65404 "Not Available" 65403 "Not Available" 65402 "Not Available" 65401 "Not Available" 65400 "Not Available" 65399 "Not Available" 65398 "Not Available" 65397 "Not Available" 65396 "Not Available" 65395 "Not Available" 65394 "Not Available" 65393 "Not Available" 65392 "Not Available" 65391 "Not Available" 65390 "Not Available" 65389 "Not Available" 65388 "Not Available" 65387 "Not Available" 65386 "Not Available" 65385 "Not Available" 65384 "Not Available" 65383 "Not Available" 65382 "Not Available" 65381 "Not Available" 65380 "Not Available" 65379 "Not Available" 65378 "Not Available" 65377 "Not Available" 65376 "Not Available" 65375 "Not Available" 65374 "Not Available" 65373 "Not Available" 65372 "Not Available" 65371 "Not Available" 65370 "Not Available" 65369 "Not Available" 65368 "Not Available" 65367 "Not Available" 65366 "Not Available" 65365 "Not Available" 65364 "Not Available" 65363 "Not Available" 65362 "Not Available" 65361 "Not Available" 65360 "Not Available" 65359 "Not Available" 65358 "Not Available" 65357 "Not Available" 65356 "Not Available" 65355 "Not Available" 65354 "Not Available" 65353 "Not Available" 65352 "Not Available" 65351 "Not Available" 65350 "Not Available" 65349 "Not Available" 65348 "Not Available" 65347 "Not Available" 65346 "Not Available" 65345 "Not Available" 65344 "Not Available" 65343 "Not Available" 65342 "Not Available" 65341 "Not Available" 65340 "Not Available" 65339 "Not Available" 65338 "Not Available" 65337 "Not Available" 65336 "Not Available" 65335 "Not Available" 65334 "Not Available" 65333 "Not Available" 65332 "Not Available" 65331 "Not Available" 65330 "Not Available" 65329 "Not Available" 65328 "Not Available" 65327 "Not Available" 65326 "Not Available" 65325 "Not Available" 65324 "Not Available" 65323 "Not Available" 65322 "Not Available" 65321 "Not Available" 65320 "Not Available" 65319 "Not Available" 65318 "Not Available" 65317 "Not Available" 65316 "Not Available" 65315 "Not Available" 65314 "Not Available" 65313 "Not Available" 65312 "Not Available" 65311 "Not Available" 65310 "Not Available" 65309 "Not Available" 65308 "Not Available" 65307 "Not Available" 65306 "Not Available" 65305 "Not Available" 65304 "Not Available" 65303 "Not Available" 65302 "Not Available" 65301 "Not Available" 65300 "Not Available" 65299 "Not Available" 65298 "Not Available" 65297 "Not Available" 65296 "Not Available" 65295 "Not Available" 65294 "Not Available" 65293 "Not Available" 65292 "Not Available" 65291 "Not Available" 65290 "Not Available" 65289 "Not Available" 65288 "Not Available" 65287 "Not Available" 65286 "Not Available" 65285 "Not Available" 65284 "Not Available" 65283 "Not Available" 65282 "Not Available" 65281 "Not Available" 65280 "Not Available" ;
VAL_ 2298375691 EBS_LRWhlSpd 65535 "Not Available" 65534 "Not Available" 65533 "Not Available" 65532 "Not Available" 65531 "Not Available" 65530 "Not Available" 65529 "Not Available" 65528 "Not Available" 65527 "Not Available" 65526 "Not Available" 65525 "Not Available" 65524 "Not Available" 65523 "Not Available" 65522 "Not Available" 65521 "Not Available" 65520 "Not Available" 65519 "Not Available" 65518 "Not Available" 65517 "Not Available" 65516 "Not Available" 65515 "Not Available" 65514 "Not Available" 65513 "Not Available" 65512 "Not Available" 65511 "Not Available" 65510 "Not Available" 65509 "Not Available" 65508 "Not Available" 65507 "Not Available" 65506 "Not Available" 65505 "Not Available" 65504 "Not Available" 65503 "Not Available" 65502 "Not Available" 65501 "Not Available" 65500 "Not Available" 65499 "Not Available" 65498 "Not Available" 65497 "Not Available" 65496 "Not Available" 65495 "Not Available" 65494 "Not Available" 65493 "Not Available" 65492 "Not Available" 65491 "Not Available" 65490 "Not Available" 65489 "Not Available" 65488 "Not Available" 65487 "Not Available" 65486 "Not Available" 65485 "Not Available" 65484 "Not Available" 65483 "Not Available" 65482 "Not Available" 65481 "Not Available" 65480 "Not Available" 65479 "Not Available" 65478 "Not Available" 65477 "Not Available" 65476 "Not Available" 65475 "Not Available" 65474 "Not Available" 65473 "Not Available" 65472 "Not Available" 65471 "Not Available" 65470 "Not Available" 65469 "Not Available" 65468 "Not Available" 65467 "Not Available" 65466 "Not Available" 65465 "Not Available" 65464 "Not Available" 65463 "Not Available" 65462 "Not Available" 65461 "Not Available" 65460 "Not Available" 65459 "Not Available" 65458 "Not Available" 65457 "Not Available" 65456 "Not Available" 65455 "Not Available" 65454 "Not Available" 65453 "Not Available" 65452 "Not Available" 65451 "Not Available" 65450 "Not Available" 65449 "Not Available" 65448 "Not Available" 65447 "Not Available" 65446 "Not Available" 65445 "Not Available" 65444 "Not Available" 65443 "Not Available" 65442 "Not Available" 65441 "Not Available" 65440 "Not Available" 65439 "Not Available" 65438 "Not Available" 65437 "Not Available" 65436 "Not Available" 65435 "Not Available" 65434 "Not Available" 65433 "Not Available" 65432 "Not Available" 65431 "Not Available" 65430 "Not Available" 65429 "Not Available" 65428 "Not Available" 65427 "Not Available" 65426 "Not Available" 65425 "Not Available" 65424 "Not Available" 65423 "Not Available" 65422 "Not Available" 65421 "Not Available" 65420 "Not Available" 65419 "Not Available" 65418 "Not Available" 65417 "Not Available" 65416 "Not Available" 65415 "Not Available" 65414 "Not Available" 65413 "Not Available" 65412 "Not Available" 65411 "Not Available" 65410 "Not Available" 65409 "Not Available" 65408 "Not Available" 65407 "Not Available" 65406 "Not Available" 65405 "Not Available" 65404 "Not Available" 65403 "Not Available" 65402 "Not Available" 65401 "Not Available" 65400 "Not Available" 65399 "Not Available" 65398 "Not Available" 65397 "Not Available" 65396 "Not Available" 65395 "Not Available" 65394 "Not Available" 65393 "Not Available" 65392 "Not Available" 65391 "Not Available" 65390 "Not Available" 65389 "Not Available" 65388 "Not Available" 65387 "Not Available" 65386 "Not Available" 65385 "Not Available" 65384 "Not Available" 65383 "Not Available" 65382 "Not Available" 65381 "Not Available" 65380 "Not Available" 65379 "Not Available" 65378 "Not Available" 65377 "Not Available" 65376 "Not Available" 65375 "Not Available" 65374 "Not Available" 65373 "Not Available" 65372 "Not Available" 65371 "Not Available" 65370 "Not Available" 65369 "Not Available" 65368 "Not Available" 65367 "Not Available" 65366 "Not Available" 65365 "Not Available" 65364 "Not Available" 65363 "Not Available" 65362 "Not Available" 65361 "Not Available" 65360 "Not Available" 65359 "Not Available" 65358 "Not Available" 65357 "Not Available" 65356 "Not Available" 65355 "Not Available" 65354 "Not Available" 65353 "Not Available" 65352 "Not Available" 65351 "Not Available" 65350 "Not Available" 65349 "Not Available" 65348 "Not Available" 65347 "Not Available" 65346 "Not Available" 65345 "Not Available" 65344 "Not Available" 65343 "Not Available" 65342 "Not Available" 65341 "Not Available" 65340 "Not Available" 65339 "Not Available" 65338 "Not Available" 65337 "Not Available" 65336 "Not Available" 65335 "Not Available" 65334 "Not Available" 65333 "Not Available" 65332 "Not Available" 65331 "Not Available" 65330 "Not Available" 65329 "Not Available" 65328 "Not Available" 65327 "Not Available" 65326 "Not Available" 65325 "Not Available" 65324 "Not Available" 65323 "Not Available" 65322 "Not Available" 65321 "Not Available" 65320 "Not Available" 65319 "Not Available" 65318 "Not Available" 65317 "Not Available" 65316 "Not Available" 65315 "Not Available" 65314 "Not Available" 65313 "Not Available" 65312 "Not Available" 65311 "Not Available" 65310 "Not Available" 65309 "Not Available" 65308 "Not Available" 65307 "Not Available" 65306 "Not Available" 65305 "Not Available" 65304 "Not Available" 65303 "Not Available" 65302 "Not Available" 65301 "Not Available" 65300 "Not Available" 65299 "Not Available" 65298 "Not Available" 65297 "Not Available" 65296 "Not Available" 65295 "Not Available" 65294 "Not Available" 65293 "Not Available" 65292 "Not Available" 65291 "Not Available" 65290 "Not Available" 65289 "Not Available" 65288 "Not Available" 65287 "Not Available" 65286 "Not Available" 65285 "Not Available" 65284 "Not Available" 65283 "Not Available" 65282 "Not Available" 65281 "Not Available" 65280 "Not Available" ;
VAL_ 2298375691 EBS_RRWhlSpd 65535 "Not Available" 65534 "Not Available" 65533 "Not Available" 65532 "Not Available" 65531 "Not Available" 65530 "Not Available" 65529 "Not Available" 65528 "Not Available" 65527 "Not Available" 65526 "Not Available" 65525 "Not Available" 65524 "Not Available" 65523 "Not Available" 65522 "Not Available" 65521 "Not Available" 65520 "Not Available" 65519 "Not Available" 65518 "Not Available" 65517 "Not Available" 65516 "Not Available" 65515 "Not Available" 65514 "Not Available" 65513 "Not Available" 65512 "Not Available" 65511 "Not Available" 65510 "Not Available" 65509 "Not Available" 65508 "Not Available" 65507 "Not Available" 65506 "Not Available" 65505 "Not Available" 65504 "Not Available" 65503 "Not Available" 65502 "Not Available" 65501 "Not Available" 65500 "Not Available" 65499 "Not Available" 65498 "Not Available" 65497 "Not Available" 65496 "Not Available" 65495 "Not Available" 65494 "Not Available" 65493 "Not Available" 65492 "Not Available" 65491 "Not Available" 65490 "Not Available" 65489 "Not Available" 65488 "Not Available" 65487 "Not Available" 65486 "Not Available" 65485 "Not Available" 65484 "Not Available" 65483 "Not Available" 65482 "Not Available" 65481 "Not Available" 65480 "Not Available" 65479 "Not Available" 65478 "Not Available" 65477 "Not Available" 65476 "Not Available" 65475 "Not Available" 65474 "Not Available" 65473 "Not Available" 65472 "Not Available" 65471 "Not Available" 65470 "Not Available" 65469 "Not Available" 65468 "Not Available" 65467 "Not Available" 65466 "Not Available" 65465 "Not Available" 65464 "Not Available" 65463 "Not Available" 65462 "Not Available" 65461 "Not Available" 65460 "Not Available" 65459 "Not Available" 65458 "Not Available" 65457 "Not Available" 65456 "Not Available" 65455 "Not Available" 65454 "Not Available" 65453 "Not Available" 65452 "Not Available" 65451 "Not Available" 65450 "Not Available" 65449 "Not Available" 65448 "Not Available" 65447 "Not Available" 65446 "Not Available" 65445 "Not Available" 65444 "Not Available" 65443 "Not Available" 65442 "Not Available" 65441 "Not Available" 65440 "Not Available" 65439 "Not Available" 65438 "Not Available" 65437 "Not Available" 65436 "Not Available" 65435 "Not Available" 65434 "Not Available" 65433 "Not Available" 65432 "Not Available" 65431 "Not Available" 65430 "Not Available" 65429 "Not Available" 65428 "Not Available" 65427 "Not Available" 65426 "Not Available" 65425 "Not Available" 65424 "Not Available" 65423 "Not Available" 65422 "Not Available" 65421 "Not Available" 65420 "Not Available" 65419 "Not Available" 65418 "Not Available" 65417 "Not Available" 65416 "Not Available" 65415 "Not Available" 65414 "Not Available" 65413 "Not Available" 65412 "Not Available" 65411 "Not Available" 65410 "Not Available" 65409 "Not Available" 65408 "Not Available" 65407 "Not Available" 65406 "Not Available" 65405 "Not Available" 65404 "Not Available" 65403 "Not Available" 65402 "Not Available" 65401 "Not Available" 65400 "Not Available" 65399 "Not Available" 65398 "Not Available" 65397 "Not Available" 65396 "Not Available" 65395 "Not Available" 65394 "Not Available" 65393 "Not Available" 65392 "Not Available" 65391 "Not Available" 65390 "Not Available" 65389 "Not Available" 65388 "Not Available" 65387 "Not Available" 65386 "Not Available" 65385 "Not Available" 65384 "Not Available" 65383 "Not Available" 65382 "Not Available" 65381 "Not Available" 65380 "Not Available" 65379 "Not Available" 65378 "Not Available" 65377 "Not Available" 65376 "Not Available" 65375 "Not Available" 65374 "Not Available" 65373 "Not Available" 65372 "Not Available" 65371 "Not Available" 65370 "Not Available" 65369 "Not Available" 65368 "Not Available" 65367 "Not Available" 65366 "Not Available" 65365 "Not Available" 65364 "Not Available" 65363 "Not Available" 65362 "Not Available" 65361 "Not Available" 65360 "Not Available" 65359 "Not Available" 65358 "Not Available" 65357 "Not Available" 65356 "Not Available" 65355 "Not Available" 65354 "Not Available" 65353 "Not Available" 65352 "Not Available" 65351 "Not Available" 65350 "Not Available" 65349 "Not Available" 65348 "Not Available" 65347 "Not Available" 65346 "Not Available" 65345 "Not Available" 65344 "Not Available" 65343 "Not Available" 65342 "Not Available" 65341 "Not Available" 65340 "Not Available" 65339 "Not Available" 65338 "Not Available" 65337 "Not Available" 65336 "Not Available" 65335 "Not Available" 65334 "Not Available" 65333 "Not Available" 65332 "Not Available" 65331 "Not Available" 65330 "Not Available" 65329 "Not Available" 65328 "Not Available" 65327 "Not Available" 65326 "Not Available" 65325 "Not Available" 65324 "Not Available" 65323 "Not Available" 65322 "Not Available" 65321 "Not Available" 65320 "Not Available" 65319 "Not Available" 65318 "Not Available" 65317 "Not Available" 65316 "Not Available" 65315 "Not Available" 65314 "Not Available" 65313 "Not Available" 65312 "Not Available" 65311 "Not Available" 65310 "Not Available" 65309 "Not Available" 65308 "Not Available" 65307 "Not Available" 65306 "Not Available" 65305 "Not Available" 65304 "Not Available" 65303 "Not Available" 65302 "Not Available" 65301 "Not Available" 65300 "Not Available" 65299 "Not Available" 65298 "Not Available" 65297 "Not Available" 65296 "Not Available" 65295 "Not Available" 65294 "Not Available" 65293 "Not Available" 65292 "Not Available" 65291 "Not Available" 65290 "Not Available" 65289 "Not Available" 65288 "Not Available" 65287 "Not Available" 65286 "Not Available" 65285 "Not Available" 65284 "Not Available" 65283 "Not Available" 65282 "Not Available" 65281 "Not Available" 65280 "Not Available" ;
VAL_ 2566858515 EHPSM_HISFctReq 7 "Failure" 6 "Reserved" 5 "Reserved" 4 "Reserved" 3 "HWP Active" 2 "ESA Active" 1 "LKA Active" 0 "Off" ;
VAL_ 2566858515 EHPSM_AvlStForHIS 7 "Reserved" 6 "Reserved" 5 "Reserved" 4 "Reserved" 3 "HWO Available Degreded" 2 "HWP Available" 1 "LKA/ESA Available" 0 "Not Available" ;
VAL_ 2566858515 EHPSM_AngCmdOverRng 1 "Over Range" 0 "Not Over Range" ;
VAL_ 2566858515 EHPSM_DrvrInpTqVal 65535 "Invalid" ;
VAL_ 2566858515 EHPSM_DrvrInpTqValVld 1 "Valid" 0 "Invalid" ;
VAL_ 2566858515 EHPSM_ErrRsnFB 15 "Reserved" 14 "Reserved" 13 "Reserved" 12 "Reserved" 11 "Reserved" 10 "Reserved" 9 "Reserved" 8 "vehicle speed is above the limit" 7 "Change rate of HIS Requested steering angle is above the limit" 6 "HIS Requested steering angle is above the limit" 5 "Over Voltage detected" 4 "Under Voltage detected" 3 "EHPS-M internal   error detected" 2 "Slave Controller communication Error" 1 "Master Controller communication Error" 0 "Not Error" ;
VAL_ 2566858515 EHPSM_WrkMod 15 "Invalid" 14 "Reserved" 13 "Reserved" 12 "Reserved" 11 "Reserved" 10 "Reserved" 9 "Reserved" 8 "Reserved" 7 "Error Mode" 6 "Warning Mode" 5 "Manual Intervent Mode" 4 "EPS Mode" 3 "Overlay_TQ_Mode" 2 "reserved" 1 "AutoSteering Mode" 0 "Standby Mode" ;
VAL_ 2365540115 EHPSM_SteerAngVld 1 "valid" 0 "Invalid" ;
VAL_ 2365540115 EHPSM_CalSt 1 "Calibrated" 0 "Uncalibration" ;
VAL_ 2365540115 EHPSM_SteerAng 65535 "Invalid" ;
VAL_ 2566787664 EPB_EPBPrkgSt 3 "Error" 2 "Released" 1 "Applied" 0 "Proportional Braking" ;
VAL_ 2566787664 EPB_WrkMod 3 "Work Shop Mode" 2 "Brake Pressure Control Mode" 1 "External Brake Control Mode" 0 "Normal Mode" ;
VAL_ 2566787664 EPB_ErrCod 1 "Error" 0 "Normal" ;
VAL_ 2566787664 EPB_EPBApplyKey 3 "Not Available" 2 "Error" 1 "Pressed" 0 "Not Pressed" ;
VAL_ 2566787664 EPB_SysSt 3 "Not Available" 2 "Driverless Active" 1 "Driverless Ready" 0 "Driverless not Ready" ;
VAL_ 2365562448 EPB_EPBWrkSt 15 "Not Available" 14 "Error" 13 "Reserved" 12 "Reserved" 11 "Reserved" 10 "Reserved" 9 "Reserved" 8 "Reserved" 7 "Secondary Brake Active（Reserved）" 6 "ADCU CDP Active" 5 "XBR Active（Reserved）" 4 "HCU CDP Active" 3 "Applying" 2 "Releasing" 1 "Applied" 0 "Released" ;
VAL_ 2365562448 EPB_LgtdCtrlAvlSt 3 "L3 Available Degrade" 2 "L3 Available" 1 "L2 and Below Available" 0 "Not Available" ;
VAL_ 2365562448 EPB_PBrkRlsInhbn 3 "Unavailable" 2 "Error" 1 "Park Brake release is inhibited" 0 "Park Brake release is not inhibited" ;
VAL_ 2365562448 EPB_PBrkInhbn 3 "Unavailable" 2 "Error" 1 "Park Brake is inhibited" 0 "Park Brake is not inhibited" ;
VAL_ 2365562448 EPB_HaltBrakeSt 15 "Unavailable" 14 "Error" 4 "Not functional" 3 "Active" 2 "Standby" 1 "Ready" 0 "Not Ready" ;
VAL_ 2566799649 BDCU_LoLgtSwt 3 "Reserved" 2 "Error" 1 "ON" 0 "OFF" ;
VAL_ 2566799649 BDCU_HiLgtSwt 3 "Reserved" 2 "Error" 1 "ON" 0 "OFF" ;
VAL_ 2566799649 BDCU_RightTurnLgtSwt 3 "Reserved" 2 "Error" 1 "ON" 0 "OFF" ;
VAL_ 2566799649 BDCU_LeftTurnLgtSwt 3 "Reserved" 2 "Error" 1 "ON" 0 "OFF" ;
VAL_ 2566799649 BDCU_HzrdLgtKey 3 "Reserved" 2 "Error" 1 "Press" 0 "Not Press" ;
VAL_ 2566799393 BDCU_HiLgtHdLgtSt 3 "Reserved" 2 "Reserved" 1 "ON" 0 "OFF" ;
VAL_ 2566799393 BDCU_FrFogLgtSt 3 "Reserved" 2 "Reserved" 1 "ON" 0 "OFF" ;
VAL_ 2566799393 BDCU_LoLgtHdLgtSt 3 "Reserved" 2 "Reserved" 1 "ON" 0 "OFF" ;
VAL_ 2566799393 BDCU_StopLgtSt 3 "Reserved" 2 "Reserved" 1 "ON" 0 "OFF" ;
VAL_ 2566799393 BDCU_ReFogLgtSt 3 "Reserved" 2 "Reserved" 1 "ON" 0 "OFF" ;
VAL_ 2566799393 BDCU_TurnSigLgtSt 7 "Reserved" 6 "Reserved" 5 "Reserved" 4 "Reserved" 3 "Reserved" 2 "Right Turn" 1 "Left Turn" 0 "OFF" ;
VAL_ 2566879009 BDCU_HzrdLgtSt 3 "Reserved" 2 "Reserved" 1 "ON" 0 "OFF" ;
VAL_ 2566891297 BDCU_DrvrSeatOccptSt 3 "Reserved" 2 "Reserved" 1 "Occupied" 0 "Unoccupied" ;
VAL_ 2566891297 BDCU_DrvrSeatBltSt 1 "Buckled" 0 "Not Buckled" ;
VAL_ 2566891297 BDCU_PassgSeatBltSt 1 "Buckled" 0 "Not Buckled" ;
VAL_ 2566891297 BDCU_PassgSeatOccptSt 3 "Reserved" 2 "Reserved" 1 "Occupied" 0 "Unoccupied" ;
VAL_ 2566879265 BDCU_LqdLvlSt 3 "Reserved" 2 "Reserved" 1 "Low" 0 "Normal" ;
VAL_ 2566879265 BDCU_HornWrkSt 3 "Electric and Air Horn" 2 "Air Horn" 1 "Electric Horn" 0 "OFF" ;
VAL_ 2566879265 BDCU_TrlrCnctnSt 3 "Reserved" 2 "Reserved" 1 "Connected" 0 "Not Connected" ;
VAL_ 2566879265 BDCU_WshngPmpErr 3 "Reserved" 2 "Open or Short Circuit to Ground" 1 "Short Circuit to Power" 0 "No Error" ;
VAL_ 2566879265 BDCU_RLSWiprSpdReq 7 "Reserved" 6 "Reserved" 5 "Reserved" 4 "Error" 3 "High" 2 "Low" 1 "INT" 0 "No Wiping" ;
VAL_ 2566879265 BDCU_LVPwrSt 7 "Reserved" 6 "Reserved" 5 "Reserved" 4 "Reserved" 3 "Reserved" 2 "ON" 1 "ACC" 0 "OFF" ;
VAL_ 2566879265 BDCU_PCSWiprCombSwt 7 "Reserved" 6 "Reserved" 5 "Error" 4 "Mist" 3 "High" 2 "Low" 1 "Auto" 0 "OFF" ;
VAL_ 2566879265 BDCU_RLSBri 250 "Invalid" ;
VAL_ 2566858220 DDCM_DrvrWindwPosn 255 "Invalid" ;
VAL_ 2566878956 DDCM_DrvrDoorAjarSt 3 "Reserved" 2 "Reserved" 1 "Open" 0 "Closed" ;
VAL_ 2566862317 PDCM_PassgWindwPosn 255 "Invalid" ;
VAL_ 2566862317 PDCM_PassgDoorAjarSt 3 "Reserved" 2 "Reserved" 1 "Open" 0 "Closed" ;
VAL_ 2566886241 HOD_SteerWhlVibrnSt 7 "Reserved" 6 "Reserved" 5 "Reserved" 4 "Reserved" 3 "Error" 2 "Level2（Reserved）" 1 "Level1" 0 "OFF" ;
VAL_ 2566886241 HOD_HandOnMonrSt1 7 "Reserved" 6 "Reserved" 5 "Reserved" 4 "Error" 3 "Two Hands Hold" 2 "One Hands Hold" 1 "One Hand or Two Hands Touch" 0 "Two Hands OFF" ;
VAL_ 2566886241 HOD_HandOnMonrSt2 3 "Reserved" 2 "Error" 1 "Hands ON" 0 "Hands OFF" ;
VAL_ 2566886241 HOD_LeftZoneMonr 3 "Error" 2 "Hands Hold" 1 "Hands Touch" 0 "Hands OFF" ;
VAL_ 2566886241 HOD_RightZoneMonr 3 "Error" 2 "Hands Hold" 1 "Hands Touch" 0 "Hands OFF" ;
VAL_ 2566886241 HOD_LeftHandOffDtcnSnsrErr 1 "Error" 0 "No Error" ;
VAL_ 2566886241 HOD_RightHandOffDtcnSnsrErr 1 "Error" 0 "No Error" ;
VAL_ 2566886241 HOD_OutsdHandOffDtcnSnsrErr 1 "Error" 0 "No Error" ;
VAL_ 2566886241 HOD_VibrnMotErr 1 "Error" 0 "No Error" ;
VAL_ 2566845491 TPMS_TireHiTWarn 3 "Not Supported" 2 "Error" 1 "High temperature warning" 0 "No Warning" ;
VAL_ 2566845491 TPMS_TireHiLoPWarn 7 "Not Available" 6 "Error" 5 "Not defined" 4 "Reserved" 3 "Under pressure 25% lower than defined" 2 "No Warning" 1 "Over pressure 30% higher than dfined" 0 "Reserved" ;
VAL_ 659 ADCU3A_HNASwtFB 1 "On" 0 "Off" ;
VAL_ 659 ADCU3A_LaneChgSwtFB 1 "On" 0 "Off" ;
VAL_ 659 ADCU3A_AutoLaneChgCfmFB 1 "Confirmation" 0 "Not Confirmation" ;
VAL_ 659 ADCU3A_AutoLaneChgRmnSetFB 3 "Reserved" 2 "Sound" 1 "Beep" 0 "Off" ;
VAL_ 659 ADCU3A_AutoLaneChgSetFB 3 "Reserved" 2 "High Sensitivity" 1 "Normal" 0 "Low Sensitivity" ;
VAL_ 659 ADCU3A_HWAStudyModSwtFB 1 "On" 0 "Off" ;
VAL_ 659 ADCU3A_HWAHNAWrkst 15 "Reserved" 14 "Reserved" 13 "Reserved" 12 "Reserved" 11 "Reserved" 10 "Reserved" 9 "HNA_Active" 8 "SafeStop" 7 "Override" 6 "StandWait" 5 "StandActive" 4 "Active_Control" 3 "Ready" 2 "Reject" 1 "Fault" 0 "Off" ;
VAL_ 659 ADCU3A_ALCFctSt 7 "Canot Lane Change" 6 "Change Lanes" 5 "Will Lane Change" 4 "Auto Lane Change Function Failure" 3 "Auto Lane Change Function Cancel" 2 "Auto Lane Change Function Overtime" 1 "Auto Lane Change Function Finish" 0 "No Display" ;
VAL_ 659 ADCU3A_TakeOverReq 7 "Reserved" 6 "Reserved" 5 "Reserved" 4 "Level4 Request" 3 "Level3 Request" 2 "Level2 Request" 1 "Level1 Request" 0 "No Request" ;
VAL_ 659 ADCU3A_HWAHNAFctRmn 15 "Reserved" 14 "Reserved" 13 "Reserved" 12 "Reserved" 11 "Reserved" 10 "Reserved" 9 "HWA Limitation Can't Active" 8 "HWA Out of Operational Design Domain" 7 "HWA Error" 6 "HWA Cancel" 5 "HWA Active" 4 "Off-Ramp" 3 "On-Ramp" 2 "Tunnel Ahead" 1 "Please Attention" 0 "No Reuest" ;
VAL_ 659 ADCU3A_LaneChgReq 3 "Reserved" 2 "Right" 1 "Left" 0 "No Request" ;
VAL_ 659 ADCU3A_TurnLgtClsRmn 1 "Closed" 0 "No Request" ;
VAL_ 659 ADCU3A_HWAFctLamp 7 "Reserved" 6 "Reserved" 5 "Reserved" 4 "Failure" 3 "Active" 2 "Ready" 1 "Reject" 0 "Off" ;
VAL_ 659 ADCU3A_LgtdCtrlSpdSetSt 255 "Invalid" ;
VAL_ 659 ADCU3A_LgtdCtrlTigapSetSt 7 "Reserved" 6 "Reserved" 5 "Reserved" 4 "Distance_4" 3 "Distance_3" 2 "Distance_2" 1 "Distance_1" 0 "No Display" ;
VAL_ 659 ADCU3A_LgtdCtrlTarDisp 7 "Reserved" 6 "Reserved" 5 "Reserved" 4 "Distance_4" 3 "Distance_3" 2 "Distance_2" 1 "Distance_1" 0 "No Display" ;
VAL_ 659 ADCU3A_LeftFisrtLaneTyp 7 "Left_Dash Right_Solid Lane" 6 "Left_Solid Right_Dash Lane" 5 "Double Dashed Lane" 4 "Double Solid Lane" 3 "road Edge" 2 "Dashed Lane" 1 "Solid Lane" 0 "No Display" ;
VAL_ 659 ADCU3A_LeftFirstLaneTrackSt 7 "Reserved" 6 "Reserved" 5 "Reserved" 4 "Reserved" 3 "Intervention" 2 "Warning" 1 "Line tracking" 0 "No display" ;
VAL_ 659 ADCU3A_LeftFirstLaneDy 8191 "Invalid" ;
VAL_ 659 ADCU3A_LeftFirstLaneAngYaw 65535 "Invalid" ;
VAL_ 659 ADCU3A_LeftFirstLaneCrvt 65535 "Invalid" ;
VAL_ 659 ADCU3A_LeftFirstLaneCrvtChg 65535 "Invalid" ;
VAL_ 659 ADCU3A_LeftSecLaneTyp 7 "Left_Dash Right_Solid Lane" 6 "Left_Solid Right_Dash Lane" 5 "Double Dashed Lane" 4 "Double Solid Lane" 3 "road Edge" 2 "Dashed Lane" 1 "Solid Lane" 0 "No Display" ;
VAL_ 659 ADCU3_LeftSecLaneTrackSt 7 "Reserved" 6 "Reserved" 5 "Reserved" 4 "Reserved" 3 "Intervention" 2 "Warning" 1 "Line tracking" 0 "No display" ;
VAL_ 659 ADCU3A_LeftSecLaneDy 8191 "Invalid" ;
VAL_ 659 ADCU3A_LeftSecLaneAngYaw 65535 "Invalid" ;
VAL_ 659 ADCU3A_LeftSecLaneCrvt 65535 "Invalid" ;
VAL_ 659 ADCU3A_LeftSecLaneCrvtChg 65535 "Invalid" ;
VAL_ 659 ADCU3A_RightFisrtLaneTyp 7 "Left_Dash Right_Solid Lane" 6 "Left_Solid Right_Dash Lane" 5 "Double Dashed Lane" 4 "Double Solid Lane" 3 "road Edge" 2 "Dashed Lane" 1 "Solid Lane" 0 "No Display" ;
VAL_ 659 ADCU3A_RightFirstLaneTrackSt 7 "Reserved" 6 "Reserved" 5 "Reserved" 4 "Reserved" 3 "Intervention" 2 "Warning" 1 "Line tracking" 0 "No display" ;
VAL_ 659 ADCU3A_RightFirstLaneDy 8191 "Invalid" ;
VAL_ 659 ADCU3A_RightFirstLaneAngYaw 65535 "Invalid" ;
VAL_ 659 ADCU3A_RightFirstLaneCrvt 65535 "Invalid" ;
VAL_ 659 ADCU3A_RightFirstLaneCrvtChg 65535 "Invalid" ;
VAL_ 660 ADCU3A_RightSecLaneTyp 7 "Left_Dash Right_Solid Lane" 6 "Left_Solid Right_Dash Lane" 5 "Double Dashed Lane" 4 "Double Solid Lane" 3 "road Edge" 2 "Dashed Lane" 1 "Solid Lane" 0 "No Display" ;
VAL_ 660 ADCU3_RightSecLaneTrackSt 7 "Reserved" 6 "Reserved" 5 "Reserved" 4 "Reserved" 3 "Intervention" 2 "Warning" 1 "Line tracking" 0 "No display" ;
VAL_ 660 ADCU3A_RightSecLaneDy 8191 "Invalid" ;
VAL_ 660 ADCU3A_RightSecLaneAngYaw 65535 "Invalid" ;
VAL_ 660 ADCU3A_RightSecLaneCrvt 65535 "Invalid" ;
VAL_ 660 ADCU3A_RightSecLaneCrvtChg 65535 "Invalid value" ;
VAL_ 660 ADCU3A_LeftTar01YawAng 511 "Invalid value" ;
VAL_ 660 ADCU3A_LeftTar02YawAng 511 "Invalid value" ;
VAL_ 660 ADCU3A_LeftTar03YawAng 511 "Invalid value" ;
VAL_ 660 ADCU3A_LeftTar04YawAng 511 "Invalid value" ;
VAL_ 660 ADCU3A_LeftTar05YawAng 511 "Invalid value" ;
VAL_ 660 ADCU3A_LeftTar06YawAng 511 "Invalid value" ;
VAL_ 660 ADCU3A_LeftTar07YawAng 511 "Invalid value" ;
VAL_ 660 ADCU3A_LeftTar08YawAng 511 "Invalid value" ;
VAL_ 660 ADCU3A_RightTar01YawAng 511 "Invalid value" ;
VAL_ 660 ADCU3A_RightTar02YawAng 511 "Invalid value" ;
VAL_ 660 ADCU3A_RightTar03YawAng 511 "Invalid value" ;
VAL_ 660 ADCU3A_RightTar04YawAng 511 "Invalid value" ;
VAL_ 660 ADCU3A_RightTar05YawAng 511 "Invalid value" ;
VAL_ 660 ADCU3A_RightTar06YawAng 511 "Invalid value" ;
VAL_ 660 ADCU3A_RightTar07YawAng 511 "Invalid value" ;
VAL_ 660 ADCU3A_RightTar08YawAng 511 "Invalid value" ;
VAL_ 660 ADCU3A_LgtdCtrlMainTarID 31 "Invalid value" ;
VAL_ 660 ADCU3A_LeftTar01Dtcd 1 "Detected" 0 "No Detected" ;
VAL_ 660 ADCU3A_LeftTar01ID 31 "Invalid value" ;
VAL_ 660 ADCU3A_LeftTar01Typ 15 "Reserved" 14 "Reserved" 13 "Reserved" 12 "Reserved" 11 "Reserved" 10 "Reserved" 9 "Reserved" 8 "Reserved" 7 "Tricycle" 6 "Pedestrain" 5 "Bicycle" 4 "Motorcycle" 3 "Bus" 2 "Truck" 1 "Car" 0 "Unkown" ;
VAL_ 660 ADCU3A_LeftTar01Dx 8191 "Invalid value" ;
VAL_ 660 ADCU3A_LeftTar01Dy 8191 "Invalid value" ;
VAL_ 660 ADCU3A_LeftTar02Dtcd 1 "Detected" 0 "No Detected" ;
VAL_ 660 ADCU3A_LeftTar02ID 31 "Invalid value" ;
VAL_ 660 ADCU3A_LeftTar02Typ 7 "Tricycle" 6 "Pedestrain" 5 "Bicycle" 4 "Motorcycle" 3 "Bus" 2 "Truck" 1 "Car" 0 "Unkown" ;
VAL_ 660 ADCU3A_LeftTar02Dx 8191 "Invalid value" ;
VAL_ 660 ADCU3A_LeftTar02Dy 8191 "Invalid value" ;
VAL_ 660 ADCU3A_LeftTar03Dtcd 1 "Detected" 0 "No Detected" ;
VAL_ 660 ADCU3A_LeftTar03ID 31 "Invalid value" ;
VAL_ 660 ADCU3A_LeftTar03Typ 7 "Tricycle" 6 "Pedestrain" 5 "Bicycle" 4 "Motorcycle" 3 "Bus" 2 "Truck" 1 "Car" 0 "Unkown" ;
VAL_ 660 ADCU3A_LeftTar03Dx 8191 "Invalid value" ;
VAL_ 660 ADCU3A_LeftTar03Dy 8191 "Invalid value" ;
VAL_ 660 ADCU3A_LeftTar04Dtcd 1 "Detected" 0 "No Detected" ;
VAL_ 660 ADCU3A_LeftTar04ID 31 "Invalid value" ;
VAL_ 660 ADCU3A_LeftTar04Typ 7 "Tricycle" 6 "Pedestrain" 5 "Bicycle" 4 "Motorcycle" 3 "Bus" 2 "Truck" 1 "Car" 0 "Unkown" ;
VAL_ 660 ADCU3A_LeftTar04Dx 8191 "Invalid value" ;
VAL_ 660 ADCU3A_LeftTar04Dy 8191 "Invalid value" ;
VAL_ 660 ADCU3A_LeftTar05Dtcd 1 "Detected" 0 "No Detected" ;
VAL_ 660 ADCU3A_LeftTar05ID 31 "Invalid value" ;
VAL_ 660 ADCU3A_LeftTar05Typ 7 "Tricycle" 6 "Pedestrain" 5 "Bicycle" 4 "Motorcycle" 3 "Bus" 2 "Truck" 1 "Car" 0 "Unkown" ;
VAL_ 660 ADCU3A_LeftTar05Dx 8191 "Invalid value" ;
VAL_ 660 ADCU3A_LeftTar05Dy 8191 "Invalid value" ;
VAL_ 660 ADCU3A_FrTar01YawAng 511 "Invalid value" ;
VAL_ 660 ADCU3A_FrTar02YawAng 511 "Invalid value" ;
VAL_ 675 ADCU3A_LeftTar06Dtcd 1 "Detected" 0 "No Detected" ;
VAL_ 675 ADCU3A_LeftTar06ID 31 "Invalid value" ;
VAL_ 675 ADCU3A_LeftTar06Typ 7 "Tricycle" 6 "Pedestrain" 5 "Bicycle" 4 "Motorcycle" 3 "Bus" 2 "Truck" 1 "Car" 0 "Unkown" ;
VAL_ 675 ADCU3A_LeftTar06Dx 8191 "Invalid value" ;
VAL_ 675 ADCU3A_LeftTar06Dy 8191 "Invalid value" ;
VAL_ 675 ADCU3A_LeftTar07Dtcd 1 "Detected" 0 "No Detected" ;
VAL_ 675 ADCU3A_LeftTar07ID 31 "Invalid value" ;
VAL_ 675 ADCU3A_LeftTar07Typ 7 "Tricycle" 6 "Pedestrain" 5 "Bicycle" 4 "Motorcycle" 3 "Bus" 2 "Truck" 1 "Car" 0 "Unkown" ;
VAL_ 675 ADCU3A_LeftTar07Dx 8191 "Invalid value" ;
VAL_ 675 ADCU3A_LeftTar07Dy 8191 "Invalid value" ;
VAL_ 675 ADCU3A_LeftTar08Dtcd 1 "Detected" 0 "No Detected" ;
VAL_ 675 ADCU3A_LeftTar08ID 31 "Invalid value" ;
VAL_ 675 ADCU3A_LeftTar08Typ 7 "Tricycle" 6 "Pedestrain" 5 "Bicycle" 4 "Motorcycle" 3 "Bus" 2 "Truck" 1 "Car" 0 "Unkown" ;
VAL_ 675 ADCU3A_LeftTar08Dx 8191 "Invalid value" ;
VAL_ 675 ADCU3A_LeftTar08Dy 8191 "Invalid value" ;
VAL_ 675 ADCU3A_RightTar01Dtcd 1 "Detected" 0 "No Detected" ;
VAL_ 675 ADCU3A_RightTar01ID 31 "Invalid value" ;
VAL_ 675 ADCU3A_RightTar01Typ 7 "Tricycle" 6 "Pedestrain" 5 "Bicycle" 4 "Motorcycle" 3 "Bus" 2 "Truck" 1 "Car" 0 "Unkown" ;
VAL_ 675 ADCU3A_RightTar01Dx 8191 "Invalid value" ;
VAL_ 675 ADCU3A_RightTar01Dy 8191 "Invalid value" ;
VAL_ 675 ADCU3A_RightTar02Dtcd 1 "Detected" 0 "No Detected" ;
VAL_ 675 ADCU3A_RightTar02ID 31 "Invalid value" ;
VAL_ 675 ADCU3A_RightTar02Typ 7 "Tricycle" 6 "Pedestrain" 5 "Bicycle" 4 "Motorcycle" 3 "Bus" 2 "Truck" 1 "Car" 0 "Unkown" ;
VAL_ 675 ADCU3A_RightTar02Dx 8191 "Invalid value" ;
VAL_ 675 ADCU3A_RightTar02Dy 8191 "Invalid value" ;
VAL_ 675 ADCU3A_RightTar03Dtcd 1 "Detected" 0 "No Detected" ;
VAL_ 675 ADCU3A_RightTar03ID 31 "Invalid value" ;
VAL_ 675 ADCU3A_RightTar03Typ 7 "Tricycle" 6 "Pedestrain" 5 "Bicycle" 4 "Motorcycle" 3 "Bus" 2 "Truck" 1 "Car" 0 "Unkown" ;
VAL_ 675 ADCU3A_RightTar03Dx 8191 "Invalid value" ;
VAL_ 675 ADCU3A_RightTar03Dy 8191 "Invalid value" ;
VAL_ 675 ADCU3A_RightTar04Dtcd 1 "Detected" 0 "No Detected" ;
VAL_ 675 ADCU3A_RightTar04ID 31 "Invalid value" ;
VAL_ 675 ADCU3A_RightTar04Typ 7 "Tricycle" 6 "Pedestrain" 5 "Bicycle" 4 "Motorcycle" 3 "Bus" 2 "Truck" 1 "Car" 0 "Unkown" ;
VAL_ 675 ADCU3A_RightTar04Dx 8191 "Invalid value" ;
VAL_ 675 ADCU3A_RightTar04Dy 8191 "Invalid value" ;
VAL_ 675 ADCU3A_RightTar05Dtcd 1 "Detected" 0 "No Detected" ;
VAL_ 675 ADCU3A_RightTar05ID 31 "Invalid value" ;
VAL_ 675 ADCU3A_RightTar05Typ 7 "Tricycle" 6 "Pedestrain" 5 "Bicycle" 4 "Motorcycle" 3 "Bus" 2 "Truck" 1 "Car" 0 "Unkown" ;
VAL_ 675 ADCU3A_RightTar05Dx 8191 "Invalid value" ;
VAL_ 675 ADCU3A_RightTar05Dy 8191 "Invalid value" ;
VAL_ 675 ADCU3A_RightTar06Dtcd 1 "Detected" 0 "No Detected" ;
VAL_ 675 ADCU3A_RightTar06ID 31 "Invalid value" ;
VAL_ 675 ADCU3A_RightTar06Typ 7 "Tricycle" 6 "Pedestrain" 5 "Bicycle" 4 "Motorcycle" 3 "Bus" 2 "Truck" 1 "Car" 0 "Unkown" ;
VAL_ 675 ADCU3A_RightTar06Dx 8191 "Invalid value" ;
VAL_ 675 ADCU3A_RightTar06Dy 8191 "Invalid value" ;
VAL_ 675 ADCU3A_RightTar07Dtcd 1 "Detected" 0 "No Detected" ;
VAL_ 675 ADCU3A_RightTar07ID 31 "Invalid value" 30 "Valid value" 29 "Valid value" 28 "Valid value" 27 "Valid value" 26 "Valid value" 25 "Valid value" 24 "Valid value" 23 "Valid value" 22 "Valid value" 21 "Valid value" 20 "Valid value" 19 "Valid value" 18 "Valid value" 17 "Valid value" 16 "Valid value" 15 "Valid value" 14 "Valid value" 13 "Valid value" 12 "Valid value" 11 "Valid value" 10 "Valid value" 9 "Valid value" 8 "Valid value" 7 "Valid value" 6 "Valid value" 5 "Valid value" 4 "Valid value" 3 "Valid value" 2 "Valid value" 1 "Valid value" 0 "Valid value" ;
VAL_ 675 ADCU3A_RightTar07Typ 7 "Tricycle" 6 "Pedestrain" 5 "Bicycle" 4 "Motorcycle" 3 "Bus" 2 "Truck" 1 "Car" 0 "Unkown" ;
VAL_ 675 ADCU3A_RightTar07Dx 8191 "Invalid value" ;
VAL_ 675 ADCU3A_RightTar07Dy 8191 "Invalid value" ;
VAL_ 675 ADCU3A_RightTar08Dtcd 1 "Detected" 0 "No Detected" ;
VAL_ 675 ADCU3A_RightTar08ID 31 "Invalid value" 30 "Valid value" 29 "Valid value" 28 "Valid value" 27 "Valid value" 26 "Valid value" 25 "Valid value" 24 "Valid value" 23 "Valid value" 22 "Valid value" 21 "Valid value" 20 "Valid value" 19 "Valid value" 18 "Valid value" 17 "Valid value" 16 "Valid value" 15 "Valid value" 14 "Valid value" 13 "Valid value" 12 "Valid value" 11 "Valid value" 10 "Valid value" 9 "Valid value" 8 "Valid value" 7 "Valid value" 6 "Valid value" 5 "Valid value" 4 "Valid value" 3 "Valid value" 2 "Valid value" 1 "Valid value" 0 "Valid value" ;
VAL_ 675 ADCU3A_RightTar08Typ 7 "Tricycle" 6 "Pedestrain" 5 "Bicycle" 4 "Motorcycle" 3 "Bus" 2 "Truck" 1 "Car" 0 "Unkown" ;
VAL_ 675 ADCU3A_RightTar08Dx 8191 "Invalid value" ;
VAL_ 675 ADCU3A_RightTar08Dy 8191 "Invalid value" ;
VAL_ 675 ADCU3A_FrTar03YawAng 511 "Invalid value" ;
VAL_ 676 ADCU3A_FrTar01Dtcd 1 "Detected" 0 "No Detected" ;
VAL_ 676 ADCU3A_FrTar01ID 31 "Invalid value" 30 "Valid value" 29 "Valid value" 28 "Valid value" 27 "Valid value" 26 "Valid value" 25 "Valid value" 24 "Valid value" 23 "Valid value" 22 "Valid value" 21 "Valid value" 20 "Valid value" 19 "Valid value" 18 "Valid value" 17 "Valid value" 16 "Valid value" 15 "Valid value" 14 "Valid value" 13 "Valid value" 12 "Valid value" 11 "Valid value" 10 "Valid value" 9 "Valid value" 8 "Valid value" 7 "Valid value" 6 "Valid value" 5 "Valid value" 4 "Valid value" 3 "Valid value" 2 "Valid value" 1 "Valid value" 0 "Valid value" ;
VAL_ 676 ADCU3A_FrTar01Typ 7 "Tricycle" 6 "Pedestrain" 5 "Bicycle" 4 "Motorcycle" 3 "Bus" 2 "Truck" 1 "Car" 0 "Unkown" ;
VAL_ 676 ADCU3A_FrTar01Dx 8191 "Invalid value" ;
VAL_ 676 ADCU3A_FrTar01Dy 8191 "Invalid value" ;
VAL_ 676 ADCU3A_FrTar02Dtcd 1 "Detected" 0 "No Detected" ;
VAL_ 676 ADCU3A_FrTar02ID 31 "Invalid value" 30 "Valid value" 29 "Valid value" 28 "Valid value" 27 "Valid value" 26 "Valid value" 25 "Valid value" 24 "Valid value" 23 "Valid value" 22 "Valid value" 21 "Valid value" 20 "Valid value" 19 "Valid value" 18 "Valid value" 17 "Valid value" 16 "Valid value" 15 "Valid value" 14 "Valid value" 13 "Valid value" 12 "Valid value" 11 "Valid value" 10 "Valid value" 9 "Valid value" 8 "Valid value" 7 "Valid value" 6 "Valid value" 5 "Valid value" 4 "Valid value" 3 "Valid value" 2 "Valid value" 1 "Valid value" 0 "Valid value" ;
VAL_ 676 ADCU3A_FrTar02Typ 7 "Tricycle" 6 "Pedestrain" 5 "Bicycle" 4 "Motorcycle" 3 "Bus" 2 "Truck" 1 "Car" 0 "Unkown" ;
VAL_ 676 ADCU3A_FrTar02Dx 8191 "Invalid value" ;
VAL_ 676 ADCU3A_FrTar02Dy 8191 "Invalid value" ;
VAL_ 676 ADCU3A_FrTar03Dtcd 1 "Detected" 0 "No Detected" ;
VAL_ 676 ADCU3A_FrTar03ID 31 "Invalid value" 30 "Valid value" 29 "Valid value" 28 "Valid value" 27 "Valid value" 26 "Valid value" 25 "Valid value" 24 "Valid value" 23 "Valid value" 22 "Valid value" 21 "Valid value" 20 "Valid value" 19 "Valid value" 18 "Valid value" 17 "Valid value" 16 "Valid value" 15 "Valid value" 14 "Valid value" 13 "Valid value" 12 "Valid value" 11 "Valid value" 10 "Valid value" 9 "Valid value" 8 "Valid value" 7 "Valid value" 6 "Valid value" 5 "Valid value" 4 "Valid value" 3 "Valid value" 2 "Valid value" 1 "Valid value" 0 "Valid value" ;
VAL_ 676 ADCU3A_FrTar03Typ 7 "Tricycle" 6 "Pedestrain" 5 "Bicycle" 4 "Motorcycle" 3 "Bus" 2 "Truck" 1 "Car" 0 "Unkown" ;
VAL_ 676 ADCU3A_FrTar03Dx 8191 "Invalid value" ;
VAL_ 676 ADCU3A_FrTar03Dy 8191 "Invalid value" ;
VAL_ 676 ADCU3A_FrTar04Dtcd 1 "Detected" 0 "No Detected" ;
VAL_ 676 ADCU3A_FrTar04ID 31 "Invalid value" 30 "Valid value" 29 "Valid value" 28 "Valid value" 27 "Valid value" 26 "Valid value" 25 "Valid value" 24 "Valid value" 23 "Valid value" 22 "Valid value" 21 "Valid value" 20 "Valid value" 19 "Valid value" 18 "Valid value" 17 "Valid value" 16 "Valid value" 15 "Valid value" 14 "Valid value" 13 "Valid value" 12 "Valid value" 11 "Valid value" 10 "Valid value" 9 "Valid value" 8 "Valid value" 7 "Valid value" 6 "Valid value" 5 "Valid value" 4 "Valid value" 3 "Valid value" 2 "Valid value" 1 "Valid value" 0 "Valid value" ;
VAL_ 676 ADCU3A_FrTar04Typ 7 "Tricycle" 6 "Pedestrain" 5 "Bicycle" 4 "Motorcycle" 3 "Bus" 2 "Truck" 1 "Car" 0 "Unkown" ;
VAL_ 676 ADCU3A_FrTar04Dx 8191 "Invalid value" ;
VAL_ 676 ADCU3A_FrTar04Dy 8191 "Invalid value" ;
VAL_ 676 ADCU3A_ReTar01Dtcd 1 "Detected" 0 "No Detected" ;
VAL_ 676 ADCU3A_ReTar01ID 31 "Invalid value" 30 "Valid value" 29 "Valid value" 28 "Valid value" 27 "Valid value" 26 "Valid value" 25 "Valid value" 24 "Valid value" 23 "Valid value" 22 "Valid value" 21 "Valid value" 20 "Valid value" 19 "Valid value" 18 "Valid value" 17 "Valid value" 16 "Valid value" 15 "Valid value" 14 "Valid value" 13 "Valid value" 12 "Valid value" 11 "Valid value" 10 "Valid value" 9 "Valid value" 8 "Valid value" 7 "Valid value" 6 "Valid value" 5 "Valid value" 4 "Valid value" 3 "Valid value" 2 "Valid value" 1 "Valid value" 0 "Valid value" ;
VAL_ 676 ADCU3A_ReTar01Typ 7 "Tricycle" 6 "Pedestrain" 5 "Bicycle" 4 "Motorcycle" 3 "Bus" 2 "Truck" 1 "Car" 0 "Unkown" ;
VAL_ 676 ADCU3A_ReTar01Dx 8191 "Invalid value" ;
VAL_ 676 ADCU3A_ReTar01Dy 8191 "Invalid value" ;
VAL_ 676 ADCU3A_ReTar02Dtcd 1 "Detected" 0 "No Detected" ;
VAL_ 676 ADCU3A_ReTar02ID 31 "Invalid value" 30 "Valid value" 29 "Valid value" 28 "Valid value" 27 "Valid value" 26 "Valid value" 25 "Valid value" 24 "Valid value" 23 "Valid value" 22 "Valid value" 21 "Valid value" 20 "Valid value" 19 "Valid value" 18 "Valid value" 17 "Valid value" 16 "Valid value" 15 "Valid value" 14 "Valid value" 13 "Valid value" 12 "Valid value" 11 "Valid value" 10 "Valid value" 9 "Valid value" 8 "Valid value" 7 "Valid value" 6 "Valid value" 5 "Valid value" 4 "Valid value" 3 "Valid value" 2 "Valid value" 1 "Valid value" 0 "Valid value" ;
VAL_ 676 ADCU3A_ReTar02Typ 7 "Tricycle" 6 "Pedestrain" 5 "Bicycle" 4 "Motorcycle" 3 "Bus" 2 "Truck" 1 "Car" 0 "Unkown" ;
VAL_ 676 ADCU3A_ReTar02Dx 8191 "Invalid value" ;
VAL_ 676 ADCU3A_ReTar02Dy 8191 "Invalid value" ;
VAL_ 676 ADCU3A_ReTar03Dtcd 1 "Detected" 0 "No Detected" ;
VAL_ 676 ADCU3A_ReTar03ID 31 "Invalid value" 30 "Valid value" 29 "Valid value" 28 "Valid value" 27 "Valid value" 26 "Valid value" 25 "Valid value" 24 "Valid value" 23 "Valid value" 22 "Valid value" 21 "Valid value" 20 "Valid value" 19 "Valid value" 18 "Valid value" 17 "Valid value" 16 "Valid value" 15 "Valid value" 14 "Valid value" 13 "Valid value" 12 "Valid value" 11 "Valid value" 10 "Valid value" 9 "Valid value" 8 "Valid value" 7 "Valid value" 6 "Valid value" 5 "Valid value" 4 "Valid value" 3 "Valid value" 2 "Valid value" 1 "Valid value" 0 "Valid value" ;
VAL_ 676 ADCU3A_ReTar03Typ 7 "Tricycle" 6 "Pedestrain" 5 "Bicycle" 4 "Motorcycle" 3 "Bus" 2 "Truck" 1 "Car" 0 "Unkown" ;
VAL_ 676 ADCU3A_ReTar03Dx 8191 "Invalid value" ;
VAL_ 676 ADCU3A_ReTar03Dy 8191 "Invalid value" ;
VAL_ 676 ADCU3A_ReTar04Dtcd 1 "Detected" 0 "No Detected" ;
VAL_ 676 ADCU3A_ReTar04ID 31 "Invalid value" 30 "Valid value" 29 "Valid value" 28 "Valid value" 27 "Valid value" 26 "Valid value" 25 "Valid value" 24 "Valid value" 23 "Valid value" 22 "Valid value" 21 "Valid value" 20 "Valid value" 19 "Valid value" 18 "Valid value" 17 "Valid value" 16 "Valid value" 15 "Valid value" 14 "Valid value" 13 "Valid value" 12 "Valid value" 11 "Valid value" 10 "Valid value" 9 "Valid value" 8 "Valid value" 7 "Valid value" 6 "Valid value" 5 "Valid value" 4 "Valid value" 3 "Valid value" 2 "Valid value" 1 "Valid value" 0 "Valid value" ;
VAL_ 676 ADCU3A_ReTar04Typ 7 "Tricycle" 6 "Pedestrain" 5 "Bicycle" 4 "Motorcycle" 3 "Bus" 2 "Truck" 1 "Car" 0 "Unkown" ;
VAL_ 676 ADCU3A_ReTar04Dx 8191 "Invalid value" ;
VAL_ 676 ADCU3A_ReTar04Dy 8191 "Invalid value" ;
VAL_ 676 ADCU3A_VehTarLeadLaneDir 3 "Right" 2 "Left" 1 "Front" 0 "No Display" ;
VAL_ 676 ADCU3A_VehTarLeadLaneColr 7 "Reserved" 6 "Reserved" 5 "Reserved" 4 "White" 3 "Gray" 2 "Green" 1 "Red" 0 "No Display" ;
VAL_ 676 ADCU3A_VehTarLeadLaneC0 127 "Reserved" 126 "Reserved" 125 "Reserved" 124 "Reserved" 123 "Reserved" 122 "Reserved" 121 "Reserved" 120 "Reserved" 119 "Reserved" 118 "Reserved" 117 "Reserved" 116 "Reserved" 115 "Reserved" 114 "Reserved" 113 "Reserved" 112 "Reserved" 111 "Reserved" ;
VAL_ 676 ADCU3A_VehTarLeadLaneC1 255 "Reserved" 254 "Reserved" 253 "Reserved" 252 "Reserved" 251 "Reserved" 250 "Reserved" 249 "Reserved" 248 "Reserved" 247 "Reserved" 246 "Reserved" 245 "Reserved" 244 "Reserved" 243 "Reserved" 242 "Reserved" 241 "Reserved" 240 "Reserved" 239 "Reserved" 238 "Reserved" 237 "Reserved" 236 "Reserved" 235 "Reserved" 234 "Reserved" 233 "Reserved" 232 "Reserved" 231 "Reserved" 230 "Reserved" 229 "Reserved" 228 "Reserved" 227 "Reserved" 226 "Reserved" 225 "Reserved" 224 "Reserved" 223 "Reserved" 222 "Reserved" ;
VAL_ 676 ADCU3A_VehTarLeadLaneC2 1023 "Reserved" 1022 "Reserved" 1021 "Reserved" 1020 "Reserved" 1019 "Reserved" 1018 "Reserved" 1017 "Reserved" 1016 "Reserved" 1015 "Reserved" 1014 "Reserved" 1013 "Reserved" 1012 "Reserved" 1011 "Reserved" 1010 "Reserved" 1009 "Reserved" 1008 "Reserved" 1007 "Reserved" 1006 "Reserved" 1005 "Reserved" 1004 "Reserved" 1003 "Reserved" 1002 "Reserved" 1001 "Reserved" ;
VAL_ 676 ADCU3A_VehTarLeadLaneC3 2001 "Reserved" ;
VAL_ 676 ADCU3A_VehCurrLeadLaneDir 3 "Right" 2 "Left" 1 "Front" 0 "No Display" ;
VAL_ 676 ADCU3A_VehCurrLeadLaneColr 7 "Reserved" 6 "Reserved" 5 "Reserved" 4 "White" 3 "Gray" 2 "Green" 1 "Red" 0 "No Display" ;
VAL_ 676 ADCU3A_VehCurrLeadLaneLen 8191 "Invalid" 511 "Invalid value" ;
VAL_ 676 ADCU3A_FrTar04YawAng 511 "Invalid value" ;
VAL_ 676 ADCU3A_ReTar01YawAng 511 "Invalid value" ;
VAL_ 676 ADCU3A_ReTar02YawAng 511 "Invalid value" ;
VAL_ 676 ADCU3A_ReTar03YawAng 511 "Invalid value" ;
VAL_ 676 ADCU3A_ReTar04YawAng 511 "Invalid value" ;
